VERSION ""

NS_ :

BS_:

BU_: PKP_PRND_Keypad HVAC Compressor_HPP DCDC_Inmotion_DC2 SME VCCU SME_4 SME_3 SME_2 SME_1 Diag_Tester BMS DCDC_inmotion_DC1 TCU Praker_GW OBC_Dilong DCDC_Dilong VCU
VAL_TABLE_ D_OBC_Faults 1 "Fault" 0 "Normal" ;
VAL_TABLE_ AAAAAAAAAAAAAAAAAAAAANew_Value_T 1 "Heating mode" 0 "Battery mode" ;
VAL_TABLE_ LED_Secondry_color 9 "Description for the value '0x9'" 8 "Amber/Orange" 7 "White/Light_Blue" 6 "Magenta" 5 "Cyan" 4 "Yellow" 3 "Blue" 2 "Green" 1 "Red" 0 "off" ;
VAL_TABLE_ Led_State 3 "Alternate_blink" 2 "Blink" 1 "On" 0 "Off" ;
VAL_TABLE_ LED_color 9 "Yellow/Green" 8 "Amber/Orange" 7 "White/light_Blue" 6 "magenta" 5 "Cyan" 4 "Yellow" 3 "Blue" 2 "Green" 1 "red" 0 "OFF" ;
VAL_TABLE_ Back_light_color 9 "Yellow/Green" 8 "Amber/Orange" 7 "White/light_blue" 6 "magenta" 5 "Cyan" 4 "Yellow" 3 "Blue" 2 "Green" 1 "Red" ;
VAL_TABLE_ Key_LED_number 4 "Description for the value '0x4'" 3 "Key_LED3" 2 "Key_LED2" 1 "Key_LED1" ;
VAL_TABLE_ Adress_claim_at_boot 1 "command_enabled" 0 "command_Disabled" ;
VAL_TABLE_ RX_command_list 128 "Set_CANopen_protocol" 125 "Set_backlight_color" 124 "LED_dim_at_startup" 123 "Set_backlight_level_at_startup" 122 "Start_DEMO_mode" 119 "Periodic_key_message_period" 117 "Heartbeat" 116 "Address_claim_at_boot" 115 "LED_acknowledgment" 114 "Event_state_transmission" 113 "Periodic_state_transmission" 112 "Set_source_address" 111 "Baud_rate_setting" 110 "Set_destination_address" 52 "Set_startup_LED_show" 42 "Get_software_revision" 40 "Set_startup_keys_message" 3 "Set_backlight_level" 2 "Set_LED_brightness_level" 1 "LED_Command" ;
VAL_TABLE_ Vt_Sig_LED_secondary_color 9 "Yellow/green" 8 "Amber/Orange" 7 "White/light_blue" 6 "Magenta" 5 "Cyan" 4 "Yellow" 3 "Blue" 2 "Green" 1 "Red" 0 "off" ;
VAL_TABLE_ TX_command_list 249 "Heart" 115 "LED_ack_message" 42 "software_revision" 1 "Key_contact_state" ;
VAL_TABLE_ VT_sig_LED_state 3 "Alternate_blink" 2 "Blink" 1 "on" 0 "off" ;
VAL_TABLE_ Vtsig_fault32_DC1 3 "Not Tested" 2 "Error Indicator" 1 "Active" 0 "Not Active" ;
VAL_TABLE_ Vtsig_fault31_DC1 3 "Not Tested" 2 "Error Indicator" 1 "Active" 0 "Not Active" ;
VAL_TABLE_ Vtsig_fault30_DC1 3 "Not Tested" 2 "Error Indicator" 1 "Active" 0 "Not Active" ;
VAL_TABLE_ Vtsig_fault29_DC1 3 "Not Tested" 2 "Error Indicator" 1 "Active" 0 "Not Active" ;
VAL_TABLE_ Vtsig_fault28_DC1 3 "Not Tested" 2 "Error Indicator" 1 "Active" 0 "Not Active" ;
VAL_TABLE_ Vtsig_fault27_DC1 3 "Not Tested" 2 "Error Indicator" 1 "Active" 0 "Not Active" ;
VAL_TABLE_ Vtsig_fault26_DC1 3 "Not Tested" 2 "Error Indicator" 1 "Active" 0 "Not Active" ;
VAL_TABLE_ Vtsig_fault25_DC1 3 "Not Tested" 2 "Error Indicator" 1 "Active" 0 "Not Active" ;
VAL_TABLE_ Vtsig_fault24_DC1 3 "Not Tested" 2 "Error Indicator" 1 "Active" 0 "Not Active" ;
VAL_TABLE_ Vtsig_fault23_DC1 3 "Not Tested" 2 "Error Indicator" 1 "Active" 0 "Not Active" ;
VAL_TABLE_ Vtsig_fault22_DC1 3 "Not Tested" 2 "Error Indicator" 1 "Active" 0 "Not Active" ;
VAL_TABLE_ Vtsig_fault21_DC1 3 "Not Tested" 2 "Error Indicator" 1 "Active" 0 "Not Active" ;
VAL_TABLE_ Vtsig_fault20_DC1 3 "Not Tested" 2 "Error Indicator" 1 "Active" 0 "Not Active" ;
VAL_TABLE_ Vtsig_fault19_DC1 3 "Not Tested" 2 "Error Indicator" 1 "Active" 0 "Not Active" ;
VAL_TABLE_ Vtsig_fault18_DC1 3 "Not Tested" 2 "Error Indicator" 1 "Active" 0 "Not Active" ;
VAL_TABLE_ Vtsig_fault17_DC1 3 "Not Tested" 2 "Error Indicator" 1 "Active" 0 "Not Active" ;
VAL_TABLE_ Vtsig_fault16_DC1 3 "Not Tested" 2 "Error Indicator" 1 "Active" 0 "Not Active" ;
VAL_TABLE_ Vtsig_fault15_DC1 3 "Not Tested" 2 "Error Indicator" 1 "Active" 0 "Not Active" ;
VAL_TABLE_ Vtsig_fault14_DC1 3 "Not Tested" 2 "Error Indicator" 1 "Active" 0 "Not Active" ;
VAL_TABLE_ Vtsig_fault13_DC1 3 "Not Tested" 2 "Error Indicator" 1 "Active" 0 "Not Active" ;
VAL_TABLE_ Vtsig_fault12_DC1 3 "Not Tested" 2 "Error Indicator" 1 "Active" 0 "Not Active" ;
VAL_TABLE_ Vtsig_fault11_DC1 3 "Not Tested" 2 "Error Indicator" 1 "Active" 0 "Not Active" ;
VAL_TABLE_ Vtsig_fault9_DC1 3 "Not Tested" 2 "Error Indicator" 1 "Active" 0 "Not Active" ;
VAL_TABLE_ Vtsig_fault8_DC1 3 "Not Tested" 2 "Error Indicator" 1 "Active" 0 "Not Active" ;
VAL_TABLE_ Vtsig_fault7_DC1 3 "Not Tested" 2 "Error Indicator" 1 "Active" 0 "Not Active" ;
VAL_TABLE_ Vtsig_fault6_DC1 3 "Not Tested" 2 "Error Indicator" 1 "Active" 0 "Not Active" ;
VAL_TABLE_ Vtsig_fault5_DC1 3 "Not Tested" 2 "Error Indicator" 1 "Active" 0 "Not Active" ;
VAL_TABLE_ Vtsig_fault4_DC1 3 "Not Tested" 2 "Error indicator" 1 "Active" 0 "Not Active" ;
VAL_TABLE_ Vtsig_fault3_DC1 3 "Not Tested'" 2 "Error indicator" 1 "Actve" 0 "Not Active" ;
VAL_TABLE_ Vtsig_fault2_DC1 3 "Not tested" 2 "Error indicator" 1 "Active" 0 "Not Active" ;
VAL_TABLE_ Fault11_DC1 3 "Not tested" 2 "Error indicator" 1 "Active" 0 "Not active" ;
VAL_TABLE_ Fault10_DC1 3 "Not tested" 2 "Error indicator" 1 "Active" 0 "not active" ;
VAL_TABLE_ A_HVAC_AC_group_2 128 "Zone 2 FRSH AIR " 64 "Zone 2 Heat ON" 32 "Zone 2 Fan HI" 16 "Zone 2 Fan ON" 8 "Floor Heat ON " 4 "Boost Pump ON " 2 "Fault Lamp ON " 1 "Heat Valve ON " ;
VAL_TABLE_ rx_ac_load_shading 3 "ignore" 2 "Medium Blowers speed" 1 "Run unloaded with medium " 0 "Run normal. " ;
VAL_TABLE_ rx_floor_heat_status 15 "ignored" 10 "Rear Unit High Blower Speed" 9 "Rear Unit Low Blower Speed" 8 "Rear Unit Natural Convection" 7 "Rear Unit Heat Valve Open" 6 "Rear Unit Heat Valve Closed" 5 "Front Unit High Blower Speed" 4 "Front Unit Low Blower Speed" 3 "Front Unit Natural Convection" 2 "Front Unit Heat Valve Open" 1 "Front Unit Heat Valve Closed" 0 "Inactive" ;
VAL_TABLE_ rx_freshair 3 "ignored" 2 "FreshAir" 1 "Recirculation" 0 "Controlled" ;
VAL_TABLE_ rx_hvac_opr_mode 15 "no action" 14 "EvapratoCondenserFansHigh Speed" 13 "Condenser Fans - High Speed" 12 "Evaporator Blowers - High Speed" 6 "All Heat Valves Open. AC OFF " 5 "Cooling/Reheat/Vent/low amb" 4 "Auto/Reheat" 3 "Reheat" 2 "Cooling/Vent    " 1 "Heating / Vent" 0 "Only Vent " ;
VAL_TABLE_ rx_controller_reset 3 "ignored" 2 "Not defined    " 1 "Forces blower speed to low speed" 0 "Runs in standard mode    " ;
VAL_TABLE_ rx_HighBlowerSpeedHeat 3 "Description for the value '0x3'" 1 "Force blower speed to high" 0 "Runs in standard mode" ;
VAL_TABLE_ rx_hvac_on_off 3 "Inactive" 1 "runs to default/ requested mode" 0 "Inactive" ;
VAL_TABLE_ rx_boostpump_signal 2 "no action" 1 "Boost Pump is oN" 0 "Boost Pump is off" ;
VAL_TABLE_ RX_blowerspeed 3 "igniore" 1 "Forceblowerspeedtolow" 0 "Runs in standard mode  " ;
VAL_TABLE_ Recirculation 3 "not used" 2 "door controlled per ladder diag" 1 "door open all the time" 0 "door closed all the time" ;
VAL_TABLE_ HigBloweHeatmode 1 "Heat mode-speed overidden" 0 "Normal" ;
VAL_TABLE_ HVACOperatingModes 15 "Description for the value '0xF'" 14 "EvporatorCondenserFansHighSpeed" 13 "Condenser Fans - High Speed" 12 "Evaporator Blowers - High Speed" 6 "All Heat Valves Open. AC OFF." 5 "Cooling/Reheat/Vent" 4 "Auto/Reheat ambient cut-out" 2 "Cooling/Vent" 1 "Heating/Vent" 0 "Only Vent (fresh air)" ;
VAL_TABLE_ BMSRequest 2 "Compressor off." 1 "Compressor at 50%,Heaters on off" 0 "Run normal." ;
VAL_TABLE_ BatteryCoolerStatus 2 "Ignore" 1 "ON" 0 "OFF" ;
VAL_TABLE_ IdleUpStatus 3 "Skip" 1 "ON" 0 "OFF" ;
VAL_TABLE_ BoostPumpStatus 2 "bus controls the boost pump" 1 "notify boost pump is oN" 0 "notify boost pump is off" ;
VAL_TABLE_ LowBlowerSpeedSignal 3 "Skip" 1 "Low" 0 "Standard" ;
VAL_TABLE_ A_HVAC_AC_group_1 128 "Fresh Air ON" 64 "Unloader 2 Energized " 32 "Unloader 1 Energized" 16 "Compressor ON" 8 "Cond. Fan Low Speed Bit" 4 "Cond. Fan High Speed" 2 "Evap. Fan Low Speed" 1 "Evap. Fan High Speed" ;
VAL_TABLE_ AAAaAAA_Electric 3 "Not Available" 2 "Critical Overheat" 1 "OverHeat" 0 "Ok" ;
VAL_TABLE_ AA_D_ElCompFaultOverloadOutput 3 "Not Available" 2 "Reserved" 1 "Error Active" 0 "OK" ;
VAL_TABLE_ AA_D_ElCompFaultTractionVoltage 3 "Not Available" 2 "OverVoltage" 1 "Undervoltage" 0 "Ok" ;
VAL_TABLE_ D_ElCompFaultTempElectrical 3 "Description for the value '0x3'" 2 "Critical Overheat" 1 "Overheat" 0 "OK" ;
VAL_TABLE_ AA_D_ElCompFaultOilLevel 3 "Not available" 2 "Reserved" 1 "LOW" 0 "OK" ;
VAL_TABLE_ AA_D_ElCompHvilStatus 7 "Not available" 6 "Reserved" 5 "Reserved" 4 "Reserved" 3 "Reserved" 2 "HVIL_diff >1V" 1 "HVIL < 5V" 0 "HVIl >= 5V" ;
VAL_TABLE_ AA_D_ElCompStatus 7 "Not available" 3 "Error Permanent" 2 "Error Recoverable" 1 "Running" 0 "Standby" ;
VAL_TABLE_ AA_D_ElCompEnableInput_NotUsed 3 "Not  Available" 2 "Error" 1 "RUN" 0 "Do not RUN" ;
VAL_TABLE_ A_MCU_Error 10 "MCU stator over temp" 9 "MCU inverter fault" 8 "MCU stator over temp" 7 "MCU CAN Active" 6 "MCU inverter over temp" 5 " MCU over speed warning" 4 "MCU over speed alarm" 3 "MCU undervoltage alarm" 2 "MCU overvoltage alarm" 1 "MCU limp home mode " 0 "No error" ;
VAL_TABLE_ A_TCu_error 3 "TCU_wtachdogerror2" 2 "TCU_wtachdogerror1" 1 "Trans Temp error" 0 "No error" ;
VAL_TABLE_ A_VMM_MiscellenousStatus 3 "Not available" 2 "Error" 1 "Active" 0 "Not active" ;
VAL_TABLE_ AA1_EBS 3 "SNA" 2 "Error" 1 "Brake pedal being pressed" 0 "BrakePedaisnot being Presssed" ;
VAL_TABLE_ A_halt_brake 3 "Not available" 2 "Error " 1 "Halt brake Active" 0 "Halt brake Passive" ;
VAL_TABLE_ A_ABS_amber_warn 3 "No action" 2 "Reserved" 1 "ON" 0 "OFF" ;
VAL_TABLE_ ABS_operation 3 "Not available" 2 "Reserved" 1 "Fully operational" 0 "Not Fully operational" ;
VAL_TABLE_ A_ABS_Off_Road 3 "Not available" 2 "Error" 1 "ABS off road active" 0 "ABS off road Passive" ;
VAL_TABLE_ A_ABC_Active 3 "Not Available" 2 "Reserved" 1 "ABS_Active" 0 "ABS passive but not active" ;
VAL_TABLE_ A_Brake_Switch 3 "Not available or not installed" 2 "Error" 1 "Brake Pedal Depressed" 0 "Brake Pedal Released" ;
VAL_TABLE_ A_park_brake 2 "Error" 1 "Brake Set" 0 "Brake not Set" ;
VAL_TABLE_ A_Seat_Belt 3 "Not available" 2 "Error" 1 "Buckled" 0 "Not Buckeld" ;
VAL_TABLE_ AA7 1 "Version 1,2 or  3" 0 "Version 4" ;
VAL_TABLE_ AA5 127 "SNA" ;
VAL_TABLE_ AA4 3 "SNA" 2 "Class C DTC" 1 "Fast Flash" 0 "Slow Flash" ;
VAL_TABLE_ AA3 3 "SNA" 2 "Reserved" 1 "Fast Flash" 0 "Slow Flash" ;
VAL_TABLE_ AA2 3 "SNA" 2 "Short MIL for WWH OBD" 1 "ON" 0 "OFF" ;
VAL_TABLE_ AA1 3 "SNA" 2 "Reserved" 1 "ON" 0 "OFF" ;
VAL_TABLE_ A_pgn 3 "Not tested" 2 "Error indicator" 1 "Active" 0 "Not active" ;
VAL_TABLE_ vtSig_ST_KL 15 "Signal Invalid" 10 "KL15- On" 9 "KL15- Change" 6 "KL30 B- On" 5 "KL30 B- Change" ;
VAL_TABLE_ VrSig_CTR_CLSY_CR 3 "signal invalid" 2 "open central locking" 1 "dont open central locking" ;
VAL_TABLE_ vtsig_bits16_siganlinvalid 65535 "Signal Invalid" ;
VAL_TABLE_ Vtsig_Bits2_DefaultValue0x3 3 "Default Value" ;
VAL_TABLE_ vtsig_bits12 4095 "Signal Invalid" ;
VAL_TABLE_ vtsig_bit4 15 "Signal Invalid" ;
VAL_TABLE_ vtsig_bits8 255 "Signal Invalid" ;
VAL_TABLE_ Wakeup_Rsn_Copy_3 255 "Snaa" 5 "Clamp15" 4 "Switch" 3 "RTC" 2 "Plug Present" 1 "Control_pilot" 0 "Network" ;
VAL_TABLE_ Vehicle_renegotiate_Copy_3 3 "SNA" 2 "Error" 1 "Requested" 0 "Not_requested" ;
VAL_TABLE_ Vehicle_contactor_status_Copy_3 3 "SNA" 2 "Stuck" 1 "Close" 0 "Open" ;
VAL_TABLE_ vehicle_chg_status_Copy_3 3 "Description for the value '0x3'" 2 "reserved" 1 "start_charging" 0 "stop_charging" ;
VAL_TABLE_ Vehicle_charge_selection_Copy_3 3 "SNA" 2 "error" 1 "secondary node" 0 "Primary node" ;
VAL_TABLE_ Vehicle_charge_permission_Copy_3 3 "Stop" 2 "Emergency stop" 1 "allowed" 0 "Not allowed" ;
VAL_TABLE_ VCVCCU_V2G_EVErrorCode_Copy_3 11 "No data" 10 "CHARGING_SYSTEM_INCOMPATIBILITY" 9 "RESERVED_C" 8 "RESERVED_B" 7 "RESERVED_A" 6 "CHARGING_VOLTAGE_OUT_OF_RANGE" 5 "FAILCHARGCURRENTDIFFERENTIAL" 4 "FAILED_EVRESSMALFUNCTION" 3 "FAILChargeCONNECT_LOCK_FAULT" 2 "FAILED_EVSHIFT_POSITION" 1 "FAILED_RESSTEMPERATURE_INHIBIT" 0 "NO_ERROR" ;
VAL_TABLE_ VCVCCU_V2G_Core_StackError_Copy_ 16 "StackError_PBufToSmall" 15 "StackError_InvalidKeyPair" 14 "StackError_NvM" 13 "StackError_NegativeResponseCode" 12 "StackError_InvalidRxParameter" 11 "StackError_InvalidRxMessage" 10 "StackError_Crypto" 9 "StackError_XmlSecurity" 8 "StackError_Exi" 7 "StackError_IpBase" 6 "StackError_Timeout" 5 "Timeout_RequestNotAcknowledged" 4 "Timeout_RequestAcknowledged" 3 "StackError_InvalidTxParameter" 2 "StackError_TransportLayer" 1 "StackError_SLAC" 0 "StackError_NoError" ;
VAL_TABLE_ VCVCCU_V2G_Core_SDPSecurityTx_Co 16 "SDPSecurity_None" 0 "SDPSecurity_Tls" ;
VAL_TABLE_ VCVCCU_V2G_Core_SAPSchemaID_Copy 4 "SAPSchemaIDs_None" 3 "NumOfSupportedSchemas" 2 "SAPSchemaIDs_DIN" 1 "SAPSchemaIDs_ISO_Ed2_CD" 0 "SAPSchemaIDs_ISO" ;
VAL_TABLE_ VCCU_mobile_status_Copy_3 3 "SNA" 2 "Vehicle immobile Fault" 1 "Vehicle Imobile" 0 "Vehicle mobile" ;
VAL_TABLE_ VCCU_Diag_Active_Copy_3 1 "Diag_no_active" 0 "Diag_active" ;
VAL_TABLE_ VCCU_Charge_unit_request_Copy_3 3 "SNA" 2 "Enable ventilation" 1 "Enable" 0 "Disable" ;
VAL_TABLE_ VCCU_8bit_Eroor_Copy_3 255 "SNA" 254 "Error" ;
VAL_TABLE_ VCCU_16bit_error_Copy_3 65535 "SNA" 65534 "Error" ;
VAL_TABLE_ V2G_SAP_response_code_Copy_3 2 "FAILED_NO_NEGOTIATION" 1 "OKNEGOTIAMINOR_DEVIATION" 0 "OK_SUCCESSFUL_NEGOTIATION" ;
VAL_TABLE_ V2G_core_msg_status_Copy_3 50 "StopCommunicationSession_Failed" 49 "StopCommunicationSession_OK" 48 "MsgStatus_SessionStop_Failed" 47 "MsgStatus_SessionStop_OK" 46 "WeldingDetection_Failed" 45 "MsgStatus_WeldingDetection_OK" 44 "MsgStatus_CurrentDemand_Failed" 43 "MsgStatus_CurrentDemand_OK" 42 "MsgStatus_PreCharge_Failed" 41 "MsgStatus_PreCharge_OK" 40 "MsgStatus_CableCheck_Failed" 39 "MsgStatus_CableCheck_OK" 38 "MsgStatus_ChargingStatus_Failed" 37 "MsgStatus_ChargingStatus_OK" 36 "MsgStatus_MeteringReceipt_Failed" 35 "MsgStatus_MeteringReceipt_OK" 34 "MsgStatus_PowerDelivery_Failed" 33 "MsgStatus_PowerDelivery_OK" 32 "ChargeParameterDiscovery_Failed" 31 "ChargeParameterDiscovery_OK" 30 "MsgStatus_Authorization_Failed" 29 "MsgStatus_Authorization_OK" 28 "MsgStatus_PaymentDetails_Failed" 27 "PaymentDetails_OK" 26 "CertificateUpdate_Failed" 25 "CertificateUpdate_OK" 24 "CertificateInstallation_Failed" 23 "CertificateInstallation_OK" 22 "MsgStatus_ReadProvCert_Failed" 21 "MsgStatus_ReadProvCert_OK" 20 "WrapperReadRootCerts_Failed" 19 "MsgStatus_ReadRootCerts_OK" 18 "PaymentServiceSelection_Failed" 17 "PaymentServiceSelection_OK" 16 "MsgStatus_ServiceDetail_Failed" 15 "MsgStatus_ServiceDetail_OK" 14 "ReadContrCertChain_Failed" 13 "ReadContrCertChain_OK" 12 "ServiceDiscovery_Failed" 11 "MsgStatus_ServiceDiscovery_OK" 10 "MsgStatus_SessionSetup_Failed" 9 "MsgStatus_SessionSetup_OK" 8 "SupportedAppProtocol_Failed" 7 "SupportedAppProtocol_OK" 6 "MsgStatus_TransportLayer_Failed" 5 "MsgStatus_TransportLayer_OK" 4 "SECCDiscoveryProtocol_Failed" 3 "SECCDiscoveryProtocol_OK" 2 "MsgStatus_SLAC_Failed" 1 "MsgStatus_SLAC_OK" 0 "MsgStatus_None" ;
VAL_TABLE_ V2G_core_msg_state_Copy_3 5 "msgstate_timeout" 4 "msgstate_response_received" 3 "msgstate_transmission_confirmed" 2 "msgstate_request_sent" 1 "msgstate_streaming_request" 0 "Msg_state_waitfor next_request" ;
VAL_TABLE_ UpShift_In_Progress_Copy_3 1 "High gear Shift is in progress" 0 "High Shift is not in progress" ;
VAL_TABLE_ Upshift_Failed_Copy_3 1 "shift to High gear failed" 0 "shift to High gear successful" ;
VAL_TABLE_ Tolerance_unit_Copy_3 9 "WH" 8 "W_S" 7 "W" 6 "VA" 5 "V" 4 "HA" 3 "A" 2 "S" 1 "M" 0 "H" ;
VAL_TABLE_ timer_status_Copy_3 3 "SNA" 2 "Elapsed" 1 "Running" 0 "Stopped" ;
VAL_TABLE_ TCU_System_type_Copy_3 0 "Unknown" ;
VAL_TABLE_ Sw_Status_Copy_3 3 "sna" 2 "Error" 1 "Pressed" 0 "Not Pressed" ;
VAL_TABLE_ StateM_machine_error_Copy_3 20 "SMER_InvalidControlPilotState" 19 "PaymtServiceSelect_ServMismatch" 18 "InitialAlignmentCheckOngoinTimer" 17 "SMER_Timer_PairingOngoingTimer" 16 "Timer_FinePositionOngoingTimer" 15 "SMER_StackError" 14 "NoContractInstallatiServiceAvbl" 13 "NoContractCertificateServiceAvlb" 12 "NoSharedPaymentOption" 11 "InvalidEnergyTransferMode" 10 "Discovery_NoSharedSecurityOption" 9 "InitializatContrctSelectiFailed" 8 "SMER_Timer_PreChargeOngoingTimer" 7 "Timer_CableCheckOngoingTimer" 6 "ChargeParmtrDiscveryOngoingTimer" 5 "Timer_AuthorizationOngoingTimer" 4 "SMETimer_ReadyToChargeTimer" 3 "Timer_CommunicationSetupTimer" 2 "SMER_Timer_SequencePerformTimer" 1 "SMER_Timer_IPAddressWaitTimer" 0 "SMER_NoError" ;
VAL_TABLE_ state_msg_state_Copy_3 3 "SMMS_WaitingForApplication" 2 "SMMS_ProcessingResponse" 1 "SMMS_WaitingForResponse" 0 "SMMS_PreparingRequest" ;
VAL_TABLE_ state_mchine_status_Copy_3 32 "PowerDemand" 31 "InitialAlignmentCheck" 30 "Pairing" 29 "FinePositioning" 28 "FinePositioningSetup" 27 "Error_Stopped" 26 "Error_WaitForRetry" 25 "Finished" 24 "StopCommunicationSession" 23 "SessionStop" 22 "WeldingDetection" 21 "MeteringReceipt" 20 "CurrentDemand" 19 "ChargingStatus" 18 "PowerDelivery" 17 "PreCharge" 16 "CableCheck" 15 "ChargeParameterDiscovery" 14 "Authorization" 13 "PaymentDetails" 12 "CertificateUpdate" 11 "CertificateInstallation" 10 "PaymentServiceSelection" 9 "ServiceDetails" 8 "ServiceDiscovery" 7 "SessionSetup" 6 "SupportedAppProtocol" 5 "TLConnection" 4 "SECCDiscoveryProtocol" 3 "WaitForIP" 2 "SLAC" 1 "Initialized" 0 "None" ;
VAL_TABLE_ ST_SER_DSCO_PLG_Copy_3 3 "Description for the value '0x2'" 2 "Service Disconnector Connected" 1 "Service Disconnector Open" ;
VAL_TABLE_ ST_MEASMT_ISL_Copy_3 3 "Signal Invalid" 2 "Iso measurement  running" 1 "Iso measurement not running" ;
VAL_TABLE_ ST_ERR_ISL_EXTN_BN_HV_VT_Copy_3 3 "Signal Invalid" 2 "Active" 1 "Not Active" 0 "No statement possible" ;
VAL_TABLE_ ST_AC_CHGNG_EPRG_Copy_3 2 "Signal Invalid" 1 "Activated" 0 "Deactivated" ;
VAL_TABLE_ SNA_Copy_3 255 "SNA" ;
VAL_TABLE_ Slow_Upshift_Copy_3 1 "Shift require more amnt of time" 0 "Shift in a normal amount of time" ;
VAL_TABLE_ Shift_Disabled_Copy_3 1 "Gear shift disabled" 0 "Gear shift not disabled" ;
VAL_TABLE_ Self_Diag_Status_Copy_3 7 "SNA" 6 "Error" 5 "Short Btw pins" 4 "Supply Voltage Failure'" 3 "Open Load" 2 "Short to Batt" 1 "Short to GND" 0 "Ok" ;
VAL_TABLE_ Selected_Gear_Copy_3 3 "Shift in Progress" 2 "High" 1 "Low" 0 "Neutral" ;
VAL_TABLE_ RTC_req_Copy_3 3 "SNA" 2 "reserved" 1 "requested" 0 "Not requested" ;
VAL_TABLE_ RQ_CHGRDI_Copy_3 2 "Char with depa time and cond" 1 "Plug & Charge (default)" 0 "no charging" ;
VAL_TABLE_ Retract_status_Copy_3 3 "Not avalible" 2 "Error" 1 "Ramp Extracted" 0 "Ramp retracted" ;
VAL_TABLE_ Resistance_Copy_3 7 "SNA" 6 "Error" 5 "S3_480_ohm" 4 "S3_150_ohm" 3 "1500 Ohm" 2 "680 ohm" 1 "220 Ohm" 0 "100 Ohm" ;
VAL_TABLE_ Ramp_move_Copy_3 3 "Not availble" 2 "error" 1 "Ramp being move" 0 "ramp being not move" ;
VAL_TABLE_ Ramp_enable_Copy_3 3 "not available" 2 "error" 1 "enable" 0 "disable" ;
VAL_TABLE_ PWM_charge_mode_req_Copy_3 3 "Description for the value '0x3'" 2 "Error" 1 "PWM_charge_mode_request_D" 0 "PWM_charge_mode_request_C" ;
VAL_TABLE_ PTC_diag_Copy_3 7 "SNA" 6 "Error" 5 "Reserved 1" 4 "Out of range" 3 "Open Load" 2 "Short to Batt" 1 "Short to GND" 0 "Ok" ;
VAL_TABLE_ PTC2_Copy_3 7 "SNA" 6 "reserved3" 5 "reserved2" 4 "reserved1" 3 "Open Load" 2 "Short to Batt" 1 "Short to GND" 0 "Ok" ;
VAL_TABLE_ Precond_desire_Copy_3 255 "SNA" 1 "Yes" 0 "No" ;
VAL_TABLE_ Pre_HVAC_Copy_3 3 "SNA" 2 "no_warm water , cool & venti" 1 "hot water and heating" 0 "only warm water , ventilation" ;
VAL_TABLE_ Pos_Feedback_Copy_3 7 "SNA" 6 "Reseved3" 5 "Reserved2" 4 "Reserved1" 3 "Open Load" 2 "Short to Batt" 1 "Short to GND" 0 "Ok" ;
VAL_TABLE_ Plug_present_self_diag_Copy_3 7 "SNA" 6 "Reseved3" 5 "Reserved2" 4 "Reserved1" 3 "Open Load" 2 "Short to Batt" 1 "Short to GND" 0 "Ok" ;
VAL_TABLE_ plug_lock_permission_Copy_3 3 "Description for the value '0x3'" 2 "Reserved" 1 "Allowed" 0 "Not_allowed" ;
VAL_TABLE_ PKP_number_Copy_3 3 "Key 4" 2 "Key 3" 1 "Key 2" 0 "Key 1" ;
VAL_TABLE_ Openstatusofdoor1_Copy_3 3 "Not availble" 2 "Error" 1 "Open" 0 "Closed" ;
VAL_TABLE_ Nm01_Copy_3 1 "Charg_Comm_active" 0 "Charg_Comm_not _active" ;
VAL_TABLE_ New_Value_Table_151_Copy_3 11 "reserved c" 10 "reserved B" 9 "Reserved A" 8 "Reserved 9" 7 "Reserved 8" 6 "EVSE Malfunction" 5 "EVSE Emergency Shutdwon" 4 "EVSE Isolation Monitoring Active" 3 "EVSE Utility Interrupt Event" 2 "EVSE Shutdown" 1 "EVSE Ready" 0 "EVSE_Not_Ready" ;
VAL_TABLE_ Motor_Req_Copy_3 7 "SNA" 6 "Reserved3" 5 "Reserved2" 4 "Reserved1" 3 "Measurement" 2 "Direction B" 1 "Directon A" 0 "Stop" ;
VAL_TABLE_ Motor_L_U_Copy_3 3 "SNA" 2 "Reserved" 1 "Unlock" 0 "Lock" ;
VAL_TABLE_ Modes_Copy_3 1 "Battery mode" 0 "Heating mode" ;
VAL_TABLE_ MCU_System_Type_Copy_3 15 "Undefined" 14 "Undefined" 13 "Undefined" 12 "Undefined" 11 "Undefined" 10 "Undefined" 9 "Undefined" 8 "Undefined" 7 "EM-PMI318B-T360-465V" 6 "Undefined" 5 "EM-PMI318B-T520E-465V" 4 "EM-PMI318B-T440E-255V" 3 "EM-PMI318-T400-255V" 2 "EM-PMI318-T360-425V" 1 "EM-PMI318-T350-255V" 0 "UnKnown" ;
VAL_TABLE_ lockstatusofdoor1_Copy_3 3 "Not Available" 2 "Error" 1 "lock" 0 "Unlock" ;
VAL_TABLE_ Lock_motor_Copy_3 7 "SNA" 6 "Error" 5 "Reserved2" 4 "Resserved1" 3 "Measurement" 2 "Direction B" 1 "Direction A" 0 "Idle" ;
VAL_TABLE_ LIN_Freq_Copy_3 255 "Not Available" 1 "60 Hz" 0 "50 Hz" ;
VAL_TABLE_ LIN_EV_Frequencies_Copy_3 255 "Not available" 2 "both 50 Hz_60 Hz" 1 "only 60 Hz" 0 "only 50 Hz" ;
VAL_TABLE_ Limit_mode_Copy_3 15 "Error indicator" 14 "Not Available" 11 "External output voltage limit" 10 "Internal output voltage limit" 9 "External current limitation" 8 "High side current limitation" 7 "High side power limitation" 6 "coolant temp limitation" 5 "Power stage temp limitation" 4 "High input voltage limitation" 3 "low input voltage limitation" 2 "Event limitation" 1 "Maximum current limitatio" 0 "No Limitation" ;
VAL_TABLE_ LED_State_Copy_3 3 "Description for the value '0x3'" 2 "Off" 1 "On" 0 "Off" ;
VAL_TABLE_ LED_colour_Secondary_colour_Copy 9 "Yellow / Green  " 8 "Amber / Orange" 7 "White / Light blue " 6 "Magneta" 5 "Cyan" 4 "Yellow" 3 "Blue" 2 "Green" 1 "Red" 0 "Off" ;
VAL_TABLE_ isolation_mesmt_req_Copy_3 3 "Description for the value '0x3'" 2 "reserved" 1 "requested" 0 "Not_requested" ;
VAL_TABLE_ isolate_mesmt_status_Copy_3 3 "SNA" 2 "Error" 1 "Active" 0 "Not active" ;
VAL_TABLE_ inlet_motor_status_Copy_3 7 "SNA" 6 "Error" 5 "Reserved3" 4 "Reserved2" 3 "Reserved1" 2 "Moving" 1 "Locked" 0 "Unlocked" ;
VAL_TABLE_ Hw_varient_Copy_3 3 "SNA" 2 "reserved" 1 "Combo1 inlet" 0 "Combo2 " ;
VAL_TABLE_ HS_req_Copy_3 3 "SNA" 2 "Reserved" 1 "Enable" 0 "Disable" ;
VAL_TABLE_ high_side_diag_Copy_3 7 "SNA" 6 "Error" 5 "Short Btw pins" 4 "Inverse Currrent" 3 "Open Load" 2 "Short to Batt" 1 "Short to GND" 0 "Ok" ;
VAL_TABLE_ Forced_Gear_Engagement_Torque_Co 1 "TCU imposing min torque reqt" 0 "TCU not imposing min torque reqt" ;
VAL_TABLE_ EVSE_resp_code_Copy_3 26 "FAILED_CERTIFICATE_REVOKED" 25 "FAILED_CERTIFICATE_NOT_ALLOW_e" 24 "FAILED_CONTACTOR_ERROR" 22 "FAILED_WRNG_ENRGY_TRNSFER_TYPE" 21 "FAILED_NO_CHARGE_SERVICE_SELECt" 20 "FAILED_MTRING_SIGNTURE_NOT_VALID" 19 "FAILED_CHARGING_PROFILE_INVALID" 18 "FAILED_TARIFF_SELECTION_INVALID" 17 "FAILED_POWER_DELIVERY_NOT_APPLy" 16 "FAILED_WRONG_CHARGE_PARAMETER" 15 "FAILED_CONTRACT_CANCELED" 14 "FAILED_CHALLENGE_INVALID" 13 "FAILED_CERT_CHAIN_ERROR" 12 "FAILED_NO_CERTIFICATE_AVAILABLE" 11 "FAILED_SIGNATURE_ERROR" 10 "FAILED_CERTIFICATE_EXPIRED" 9 "FAILED_PAYMENT_SELECTION_INVALID" 8 "FAILED_SERVICE_SELECTION_INVALID" 7 "FAILED_UNKNOWN_SESSION" 6 "FAILED_SERVICE_IDINVALID" 5 "FAILED_SEQUENCE_ERROR" 4 "FAILED" 3 "OK_CERTIFICATE_EXPIRES_SOON" 2 "OK_OLD_SESSION_JOINED" 1 "OK_NEW_SESSION_ESTABLISHED" 0 "OK" ;
VAL_TABLE_ EVSE_Process_Copy_3 1 "ongoing" 0 "Finished" ;
VAL_TABLE_ EVSE_notification_Copy_3 2 "Re_Negotation" 1 "Stop Charging" 0 "None" ;
VAL_TABLE_ EVSE_isoltae_status_Copy_3 4 "No_Imd" 3 "Fault" 2 "Warning" 1 "Valid" 0 "Invalid" ;
VAL_TABLE_ energy_trans_mode_Copy_3 32 "Description for the value '0x18'" 16 "Energy_transfermode_combo_core" 8 "Energy_transfermode_DC_extend" 4 "Energy_transfermode_DCcore" 2 "Energy_transfermode_AC_3P" 1 "Energy_transfermode_AC_1P" 0 "Energy_transfermode_none" ;
VAL_TABLE_ energy_mode_Copy_3 15 "undefined" 5 "DC_unique" 4 "DC_combo_core" 3 "DC_extended" 2 "DC_core" 1 "AC_three_phase_core" 0 "Ac_single_phse_core" ;
VAL_TABLE_ E2E_state_charge_vehicle_Copy_3 32 "NoDATA_OK" 5 "Valid_NND" 3 "Valid_Error" 2 "Valid_SEQ" 1 "Valid_REP" 0 "Valid_Ok" ;
VAL_TABLE_ e2e_state_Copy_3 255 "Hard_run_time_error" 119 "Soft_run_time_error" 69 "Invalid_NND" 67 "Invalid_Error" 66 "Invalid_SEQ" 65 "Invalid_REP" 64 "Invalid_Ok" 53 "Init_NND" 51 "Init_error" 50 "Init_SEQ" 49 "Init_REP" 48 "Init_Ok" 37 "No_Data_NND" 35 "No_data_error" 34 "No_data_SEQ" 33 "No_data_REP" 32 "No_data_ok" 5 "valid NND" 3 "valid Error" 2 "valid SEQ" 1 "valid REP" 0 "valid ok" ;
VAL_TABLE_ Down_Shift_In_progress_Copy_3 1 "High gear Shift is in progress" 0 "High Shift is not in progress" ;
VAL_TABLE_ Down_Shift_failed_Copy_3 1 "shift to low gear failed" 0 "shift to Low gear Successful" ;
VAL_TABLE_ Door_Enable_Copy_3 2 "Not available" 1 "Error" 0 "Enabled" ;
VAL_TABLE_ DM13_suspend_signal_Copy_3 15 "not available" 14 "ResumingNormalpattern" 3 "Temporarysuspensionofsomemsg" 2 "Temporarysuspensionofallmsg" 1 "Indefinitesuspensionofsomemsg" 0 "Indefinitesuspensionofallmsg" ;
VAL_TABLE_ DM13_hold_signal_Copy_3 15 "Not available" 1 "Devices whose broadcast state" 0 "All Devices" ;
VAL_TABLE_ DilongDCDC_Faults_Copy_3 256 "Communication fault" 128 "Internal fault" 64 "Output short circuit protection" 32 "Input under voltage" 16 "Input over voltage" 8 "Output under voltage" 4 "Output over voltage" 2 "Output over current" 1 "Over temperature shutdown" ;
VAL_TABLE_ dept_Copy_3 0 "SNA" ;
VAL_TABLE_ DCDC_control_Copy_3 15 "Error Indicator" 14 "Not availble" 13 "Error state" 12 "Shutting down" 2 "Current control" 1 "Voltage control" 0 "Standby" ;
VAL_TABLE_ D_OBC_Mode_Copy_3 1 "Heating" 0 "Battery" ;
VAL_TABLE_ D_OBC_Charging_status_flag_Copy_ 16 "0 com normal 1 com timeout" 8 "0 start state 1 off" 4 "0 normal 1 input volt error" 2 "0 normal 1 charg temp too high" 1 "0 normal 1 HW failure" ;
VAL_TABLE_ D_OBC_Charging_state_Copy_3 2 "Charging complete" 1 "Bat prote,charger turn off op" 0 "The charger starts charging " ;
VAL_TABLE_ D_OBC_Charging_boot_status_Copy_ 32 "0 normal 1 alarm" 16 "0 normal 1 alarm" 8 "0 normal 1 alarm" 4 "2 fault 3 no electic lock" 2 "0 unlock 1 lock" 1 "0 disconnect 1 HW close" ;
VAL_TABLE_ D_DCDC_Switch_Control_Copy_3 1 "Shutdown" 0 "Power on" ;
VAL_TABLE_ D_DCDC_status_Copy_3 1 "Stop" 0 "Work" ;
VAL_TABLE_ D_DCDC_Fault_list_Copy_3 32768 "Reserve" 16384 "Reserve" 8192 "Reserve" 4096 "Reserve" 2048 "Reserve" 1024 "Reserve" 512 "Reserve" 256 "Communication fault alarm" 128 "Internal fault alarm " 64 "Output shortcircuit protection " 32 "Input under voltage alarm " 16 "Input over-voltage alarm" 8 "Output undervoltage alarm" 4 "Output over-voltage alarm" 2 "Output over-current alarm" 1 "Over temperature shutdown" ;
VAL_TABLE_ Current_Transmission_Mode_Copy_3 3 "Forward Low" 2 "Forward Automatic" 1 "Reverse" 0 "Neutral" ;
VAL_TABLE_ CTR_FKTN_PRTNT_DRV_Copy_3 -2147483648 "Signal invalid" ;
VAL_TABLE_ CTR_BS_PRTNT_DRV_Copy_3 65535 "Signal Invalid" ;
VAL_TABLE_ Cp_wakeup_Copy_3 3 "sna" 2 "error" 1 "wakeup detected" 0 "wakeup not detected" ;
VAL_TABLE_ CP_chrage_mode_req_Copy_3 7 "SNA" 6 "Error" 5 "Reserved 3" 4 "Reserved 2" 3 "Reserved 1" 2 "Mode D" 1 "Mode C" 0 "Mode B" ;
VAL_TABLE_ Controlmode_Copy_3 3 "take no action" 2 "reserved" 1 "Current control" 0 "Voltage control " ;
VAL_TABLE_ Contactor_req_Copy_3 3 "Description for the value '0x3'" 2 "force_open" 1 "close" 0 "open" ;
VAL_TABLE_ connection_status_Copy_3 3 "Description for the value '0x3'" 2 "error" 1 "connected" 0 "not connected" ;
VAL_TABLE_ CommandEnableDCC2_Copy_3 3 "Take no action" 2 "Reserved" 1 "Enable" 0 "Standby" ;
VAL_TABLE_ Clamp_15_active_Copy_3 1 "Clamp_15_noactive" 0 "Clamp15_Active" ;
VAL_TABLE_ chg_unit_state_Copy_3 7 "SNA" 6 "EVSE State F" 5 "EVSE State E" 4 "EVSE State D" 3 "EVSE State C" 2 "EVSE State B2" 1 "EVSE state B1" 0 "EVSE state A" ;
VAL_TABLE_ chg_unit_mode_Copy_3 7 "sna" 6 "error" 5 "reserved" 4 "Charge Pantograph" 3 "Charging LIN" 2 "Charging Not allowed" 1 "Charge PWM" 0 "Charge V2G" ;
VAL_TABLE_ chg_selct_ack_Copy_3 3 "sna" 2 "error" 1 "secondary node" 0 "primary_node" ;
VAL_TABLE_ Charge_State_Copy_3 2 "Charging complete" 1 "Bat prtect charger turn off" 0 "Charger start charging" ;
VAL_TABLE_ Charge_Comm_Active_Copy_3 1 "Description for the value '0x1'" 0 "Charg_Comm_Active" ;
VAL_TABLE_ Charg_Lin_Active_Copy_3 1 "Charg_Lin_Non active" 0 "Charg_Lin_Active" ;
VAL_TABLE_ Broadcast_Copy_3 3 "dont care" 2 "reserved" 1 "start broadcast" 0 "Stop broadcast" ;
VAL_TABLE_ Brakes_Copy_3 3 "Not available" 2 "Error indicator" 1 "Fuel level sufficient" 0 "Fuel level not sufficient" ;
VAL_TABLE_ Boolean_Copy_3 1 "True" 0 "False" ;
VAL_TABLE_ appl_func_mode_req_Copy_3 2 "Reset" 1 "Charging mode" 0 "none" ;
VAL_TABLE_ appl_chg_mode_req_Copy_3 6 "Stop Charging" 5 "Renegotation" 4 "Start welding detection" 3 "Start power delivery" 2 "Precharge completed" 1 "Negotating Charging Parameters" 0 "None" ;
VAL_TABLE_ AMB_TEMP_Copy_3 127 "SNA" ;
VAL_TABLE_ Air_Pressure_Out_of_Range_Copy_3 1 "solenoids is out of range" 0 "solenoids is in normal range" ;
VAL_TABLE_ Wakeup_Rsn_Copy_2 255 "Snaa" 5 "Clamp15" 4 "Switch" 3 "RTC" 2 "Plug Present" 1 "Control_pilot" 0 "Network" ;
VAL_TABLE_ Vehicle_renegotiate_Copy_2 3 "SNA" 2 "Error" 1 "Requested" 0 "Not_requested" ;
VAL_TABLE_ Vehicle_contactor_status_Copy_2 3 "SNA" 2 "Stuck" 1 "Close" 0 "Open" ;
VAL_TABLE_ vehicle_chg_status_Copy_2 3 "Description for the value '0x3'" 2 "reserved" 1 "start_charging" 0 "stop_charging" ;
VAL_TABLE_ Vehicle_charge_selection_Copy_2 3 "SNA" 2 "error" 1 "secondary node" 0 "Primary node" ;
VAL_TABLE_ Vehicle_charge_permission_Copy_2 3 "Stop" 2 "Emergency stop" 1 "allowed" 0 "Not allowed" ;
VAL_TABLE_ VCVCCU_V2G_EVErrorCode_Copy_2 11 "No data" 10 "CHARGING_SYSTEM_INCOMPATIBILITY" 9 "RESERVED_C" 8 "RESERVED_B" 7 "RESERVED_A" 6 "CHARGING_VOLTAGE_OUT_OF_RANGE" 5 "FAILCHARGCURRENTDIFFERENTIAL" 4 "FAILED_EVRESSMALFUNCTION" 3 "FAILChargeCONNECT_LOCK_FAULT" 2 "FAILED_EVSHIFT_POSITION" 1 "FAILED_RESSTEMPERATURE_INHIBIT" 0 "NO_ERROR" ;
VAL_TABLE_ VCVCCU_V2G_Core_StackError_Copy_ 16 "StackError_PBufToSmall" 15 "StackError_InvalidKeyPair" 14 "StackError_NvM" 13 "StackError_NegativeResponseCode" 12 "StackError_InvalidRxParameter" 11 "StackError_InvalidRxMessage" 10 "StackError_Crypto" 9 "StackError_XmlSecurity" 8 "StackError_Exi" 7 "StackError_IpBase" 6 "StackError_Timeout" 5 "Timeout_RequestNotAcknowledged" 4 "Timeout_RequestAcknowledged" 3 "StackError_InvalidTxParameter" 2 "StackError_TransportLayer" 1 "StackError_SLAC" 0 "StackError_NoError" ;
VAL_TABLE_ VCVCCU_V2G_Core_SDPSecurityTx_Co 16 "SDPSecurity_None" 0 "SDPSecurity_Tls" ;
VAL_TABLE_ VCVCCU_V2G_Core_SAPSchemaID_Copy 4 "SAPSchemaIDs_None" 3 "NumOfSupportedSchemas" 2 "SAPSchemaIDs_DIN" 1 "SAPSchemaIDs_ISO_Ed2_CD" 0 "SAPSchemaIDs_ISO" ;
VAL_TABLE_ VCCU_mobile_status_Copy_2 3 "SNA" 2 "Vehicle immobile Fault" 1 "Vehicle Imobile" 0 "Vehicle mobile" ;
VAL_TABLE_ VCCU_Diag_Active_Copy_2 1 "Diag_no_active" 0 "Diag_active" ;
VAL_TABLE_ VCCU_Charge_unit_request_Copy_2 3 "SNA" 2 "Enable ventilation" 1 "Enable" 0 "Disable" ;
VAL_TABLE_ VCCU_8bit_Eroor_Copy_2 255 "SNA" 254 "Error" ;
VAL_TABLE_ VCCU_16bit_error_Copy_2 65535 "SNA" 65534 "Error" ;
VAL_TABLE_ V2G_SAP_response_code_Copy_2 2 "FAILED_NO_NEGOTIATION" 1 "OKNEGOTIAMINOR_DEVIATION" 0 "OK_SUCCESSFUL_NEGOTIATION" ;
VAL_TABLE_ V2G_core_msg_status_Copy_2 50 "StopCommunicationSession_Failed" 49 "StopCommunicationSession_OK" 48 "MsgStatus_SessionStop_Failed" 47 "MsgStatus_SessionStop_OK" 46 "WeldingDetection_Failed" 45 "MsgStatus_WeldingDetection_OK" 44 "MsgStatus_CurrentDemand_Failed" 43 "MsgStatus_CurrentDemand_OK" 42 "MsgStatus_PreCharge_Failed" 41 "MsgStatus_PreCharge_OK" 40 "MsgStatus_CableCheck_Failed" 39 "MsgStatus_CableCheck_OK" 38 "MsgStatus_ChargingStatus_Failed" 37 "MsgStatus_ChargingStatus_OK" 36 "MsgStatus_MeteringReceipt_Failed" 35 "MsgStatus_MeteringReceipt_OK" 34 "MsgStatus_PowerDelivery_Failed" 33 "MsgStatus_PowerDelivery_OK" 32 "ChargeParameterDiscovery_Failed" 31 "ChargeParameterDiscovery_OK" 30 "MsgStatus_Authorization_Failed" 29 "MsgStatus_Authorization_OK" 28 "MsgStatus_PaymentDetails_Failed" 27 "PaymentDetails_OK" 26 "CertificateUpdate_Failed" 25 "CertificateUpdate_OK" 24 "CertificateInstallation_Failed" 23 "CertificateInstallation_OK" 22 "MsgStatus_ReadProvCert_Failed" 21 "MsgStatus_ReadProvCert_OK" 20 "WrapperReadRootCerts_Failed" 19 "MsgStatus_ReadRootCerts_OK" 18 "PaymentServiceSelection_Failed" 17 "PaymentServiceSelection_OK" 16 "MsgStatus_ServiceDetail_Failed" 15 "MsgStatus_ServiceDetail_OK" 14 "ReadContrCertChain_Failed" 13 "ReadContrCertChain_OK" 12 "ServiceDiscovery_Failed" 11 "MsgStatus_ServiceDiscovery_OK" 10 "MsgStatus_SessionSetup_Failed" 9 "MsgStatus_SessionSetup_OK" 8 "SupportedAppProtocol_Failed" 7 "SupportedAppProtocol_OK" 6 "MsgStatus_TransportLayer_Failed" 5 "MsgStatus_TransportLayer_OK" 4 "SECCDiscoveryProtocol_Failed" 3 "SECCDiscoveryProtocol_OK" 2 "MsgStatus_SLAC_Failed" 1 "MsgStatus_SLAC_OK" 0 "MsgStatus_None" ;
VAL_TABLE_ V2G_core_msg_state_Copy_2 5 "msgstate_timeout" 4 "msgstate_response_received" 3 "msgstate_transmission_confirmed" 2 "msgstate_request_sent" 1 "msgstate_streaming_request" 0 "Msg_state_waitfor next_request" ;
VAL_TABLE_ UpShift_In_Progress_Copy_2 1 "High gear Shift is in progress" 0 "High Shift is not in progress" ;
VAL_TABLE_ Upshift_Failed_Copy_2 1 "shift to High gear failed" 0 "shift to High gear successful" ;
VAL_TABLE_ Tolerance_unit_Copy_2 9 "WH" 8 "W_S" 7 "W" 6 "VA" 5 "V" 4 "HA" 3 "A" 2 "S" 1 "M" 0 "H" ;
VAL_TABLE_ timer_status_Copy_2 3 "SNA" 2 "Elapsed" 1 "Running" 0 "Stopped" ;
VAL_TABLE_ TCU_System_type_Copy_2 0 "Unknown" ;
VAL_TABLE_ Sw_Status_Copy_2 3 "sna" 2 "Error" 1 "Pressed" 0 "Not Pressed" ;
VAL_TABLE_ StateM_machine_error_Copy_2 20 "SMER_InvalidControlPilotState" 19 "PaymtServiceSelect_ServMismatch" 18 "InitialAlignmentCheckOngoinTimer" 17 "SMER_Timer_PairingOngoingTimer" 16 "Timer_FinePositionOngoingTimer" 15 "SMER_StackError" 14 "NoContractInstallatiServiceAvbl" 13 "NoContractCertificateServiceAvlb" 12 "NoSharedPaymentOption" 11 "InvalidEnergyTransferMode" 10 "Discovery_NoSharedSecurityOption" 9 "InitializatContrctSelectiFailed" 8 "SMER_Timer_PreChargeOngoingTimer" 7 "Timer_CableCheckOngoingTimer" 6 "ChargeParmtrDiscveryOngoingTimer" 5 "Timer_AuthorizationOngoingTimer" 4 "SMETimer_ReadyToChargeTimer" 3 "Timer_CommunicationSetupTimer" 2 "SMER_Timer_SequencePerformTimer" 1 "SMER_Timer_IPAddressWaitTimer" 0 "SMER_NoError" ;
VAL_TABLE_ state_msg_state_Copy_2 3 "SMMS_WaitingForApplication" 2 "SMMS_ProcessingResponse" 1 "SMMS_WaitingForResponse" 0 "SMMS_PreparingRequest" ;
VAL_TABLE_ state_mchine_status_Copy_2 32 "PowerDemand" 31 "InitialAlignmentCheck" 30 "Pairing" 29 "FinePositioning" 28 "FinePositioningSetup" 27 "Error_Stopped" 26 "Error_WaitForRetry" 25 "Finished" 24 "StopCommunicationSession" 23 "SessionStop" 22 "WeldingDetection" 21 "MeteringReceipt" 20 "CurrentDemand" 19 "ChargingStatus" 18 "PowerDelivery" 17 "PreCharge" 16 "CableCheck" 15 "ChargeParameterDiscovery" 14 "Authorization" 13 "PaymentDetails" 12 "CertificateUpdate" 11 "CertificateInstallation" 10 "PaymentServiceSelection" 9 "ServiceDetails" 8 "ServiceDiscovery" 7 "SessionSetup" 6 "SupportedAppProtocol" 5 "TLConnection" 4 "SECCDiscoveryProtocol" 3 "WaitForIP" 2 "SLAC" 1 "Initialized" 0 "None" ;
VAL_TABLE_ ST_SER_DSCO_PLG_Copy_2 3 "Description for the value '0x2'" 2 "Service Disconnector Connected" 1 "Service Disconnector Open" ;
VAL_TABLE_ ST_MEASMT_ISL_Copy_2 3 "Signal Invalid" 2 "Iso measurement  running" 1 "Iso measurement not running" ;
VAL_TABLE_ ST_ERR_ISL_EXTN_BN_HV_VT_Copy_2 3 "Signal Invalid" 2 "Active" 1 "Not Active" 0 "No statement possible" ;
VAL_TABLE_ ST_AC_CHGNG_EPRG_Copy_2 2 "Signal Invalid" 1 "Activated" 0 "Deactivated" ;
VAL_TABLE_ SNA_Copy_2 255 "SNA" ;
VAL_TABLE_ Slow_Upshift_Copy_2 1 "Shift require more amnt of time" 0 "Shift in a normal amount of time" ;
VAL_TABLE_ Shift_Disabled_Copy_2 1 "Gear shift disabled" 0 "Gear shift not disabled" ;
VAL_TABLE_ Self_Diag_Status_Copy_2 7 "SNA" 6 "Error" 5 "Short Btw pins" 4 "Supply Voltage Failure'" 3 "Open Load" 2 "Short to Batt" 1 "Short to GND" 0 "Ok" ;
VAL_TABLE_ Selected_Gear_Copy_2 3 "Shift in Progress" 2 "High" 1 "Low" 0 "Neutral" ;
VAL_TABLE_ RTC_req_Copy_2 3 "SNA" 2 "reserved" 1 "requested" 0 "Not requested" ;
VAL_TABLE_ RQ_CHGRDI_Copy_2 2 "Char with depa time and cond" 1 "Plug & Charge (default)" 0 "no charging" ;
VAL_TABLE_ Retract_status_Copy_2 3 "Not avalible" 2 "Error" 1 "Ramp Extracted" 0 "Ramp retracted" ;
VAL_TABLE_ Resistance_Copy_2 7 "SNA" 6 "Error" 5 "S3_480_ohm" 4 "S3_150_ohm" 3 "1500 Ohm" 2 "680 ohm" 1 "220 Ohm" 0 "100 Ohm" ;
VAL_TABLE_ Ramp_move_Copy_2 3 "Not availble" 2 "error" 1 "Ramp being move" 0 "ramp being not move" ;
VAL_TABLE_ Ramp_enable_Copy_2 3 "not available" 2 "error" 1 "enable" 0 "disable" ;
VAL_TABLE_ PWM_charge_mode_req_Copy_2 3 "Description for the value '0x3'" 2 "Error" 1 "PWM_charge_mode_request_D" 0 "PWM_charge_mode_request_C" ;
VAL_TABLE_ PTC_diag_Copy_2 7 "SNA" 6 "Error" 5 "Reserved 1" 4 "Out of range" 3 "Open Load" 2 "Short to Batt" 1 "Short to GND" 0 "Ok" ;
VAL_TABLE_ PTC2_Copy_2 7 "SNA" 6 "reserved3" 5 "reserved2" 4 "reserved1" 3 "Open Load" 2 "Short to Batt" 1 "Short to GND" 0 "Ok" ;
VAL_TABLE_ Precond_desire_Copy_2 255 "SNA" 1 "Yes" 0 "No" ;
VAL_TABLE_ Pre_HVAC_Copy_2 3 "SNA" 2 "no_warm water , cool & venti" 1 "hot water and heating" 0 "only warm water , ventilation" ;
VAL_TABLE_ Pos_Feedback_Copy_2 7 "SNA" 6 "Reseved3" 5 "Reserved2" 4 "Reserved1" 3 "Open Load" 2 "Short to Batt" 1 "Short to GND" 0 "Ok" ;
VAL_TABLE_ Plug_present_self_diag_Copy_2 7 "SNA" 6 "Reseved3" 5 "Reserved2" 4 "Reserved1" 3 "Open Load" 2 "Short to Batt" 1 "Short to GND" 0 "Ok" ;
VAL_TABLE_ plug_lock_permission_Copy_2 3 "Description for the value '0x3'" 2 "Reserved" 1 "Allowed" 0 "Not_allowed" ;
VAL_TABLE_ PKP_number_Copy_2 3 "Key 4" 2 "Key 3" 1 "Key 2" 0 "Key 1" ;
VAL_TABLE_ Openstatusofdoor1_Copy_2 3 "Not availble" 2 "Error" 1 "Open" 0 "Closed" ;
VAL_TABLE_ Nm01_Copy_2 1 "Charg_Comm_active" 0 "Charg_Comm_not _active" ;
VAL_TABLE_ New_Value_Table_151_Copy_2 11 "reserved c" 10 "reserved B" 9 "Reserved A" 8 "Reserved 9" 7 "Reserved 8" 6 "EVSE Malfunction" 5 "EVSE Emergency Shutdwon" 4 "EVSE Isolation Monitoring Active" 3 "EVSE Utility Interrupt Event" 2 "EVSE Shutdown" 1 "EVSE Ready" 0 "EVSE_Not_Ready" ;
VAL_TABLE_ Motor_Req_Copy_2 7 "SNA" 6 "Reserved3" 5 "Reserved2" 4 "Reserved1" 3 "Measurement" 2 "Direction B" 1 "Directon A" 0 "Stop" ;
VAL_TABLE_ Motor_L_U_Copy_2 3 "SNA" 2 "Reserved" 1 "Unlock" 0 "Lock" ;
VAL_TABLE_ Modes_Copy_2 1 "Battery mode" 0 "Heating mode" ;
VAL_TABLE_ MCU_System_Type_Copy_2 15 "Undefined" 14 "Undefined" 13 "Undefined" 12 "Undefined" 11 "Undefined" 10 "Undefined" 9 "Undefined" 8 "Undefined" 7 "EM-PMI318B-T360-465V" 6 "Undefined" 5 "EM-PMI318B-T520E-465V" 4 "EM-PMI318B-T440E-255V" 3 "EM-PMI318-T400-255V" 2 "EM-PMI318-T360-425V" 1 "EM-PMI318-T350-255V" 0 "UnKnown" ;
VAL_TABLE_ lockstatusofdoor1_Copy_2 3 "Not Available" 2 "Error" 1 "lock" 0 "Unlock" ;
VAL_TABLE_ Lock_motor_Copy_2 7 "SNA" 6 "Error" 5 "Reserved2" 4 "Resserved1" 3 "Measurement" 2 "Direction B" 1 "Direction A" 0 "Idle" ;
VAL_TABLE_ LIN_Freq_Copy_2 255 "Not Available" 1 "60 Hz" 0 "50 Hz" ;
VAL_TABLE_ LIN_EV_Frequencies_Copy_2 255 "Not available" 2 "both 50 Hz_60 Hz" 1 "only 60 Hz" 0 "only 50 Hz" ;
VAL_TABLE_ Limit_mode_Copy_2 15 "Error indicator" 14 "Not Available" 11 "External output voltage limit" 10 "Internal output voltage limit" 9 "External current limitation" 8 "High side current limitation" 7 "High side power limitation" 6 "coolant temp limitation" 5 "Power stage temp limitation" 4 "High input voltage limitation" 3 "low input voltage limitation" 2 "Event limitation" 1 "Maximum current limitatio" 0 "No Limitation" ;
VAL_TABLE_ LED_State_Copy_2 3 "Description for the value '0x3'" 2 "Off" 1 "On" 0 "Off" ;
VAL_TABLE_ LED_colour_Secondary_colour_Copy 9 "Yellow / Green  " 8 "Amber / Orange" 7 "White / Light blue " 6 "Magneta" 5 "Cyan" 4 "Yellow" 3 "Blue" 2 "Green" 1 "Red" 0 "Off" ;
VAL_TABLE_ isolation_mesmt_req_Copy_2 3 "Description for the value '0x3'" 2 "reserved" 1 "requested" 0 "Not_requested" ;
VAL_TABLE_ isolate_mesmt_status_Copy_2 3 "SNA" 2 "Error" 1 "Active" 0 "Not active" ;
VAL_TABLE_ inlet_motor_status_Copy_2 7 "SNA" 6 "Error" 5 "Reserved3" 4 "Reserved2" 3 "Reserved1" 2 "Moving" 1 "Locked" 0 "Unlocked" ;
VAL_TABLE_ Hw_varient_Copy_2 3 "SNA" 2 "reserved" 1 "Combo1 inlet" 0 "Combo2 " ;
VAL_TABLE_ HS_req_Copy_2 3 "SNA" 2 "Reserved" 1 "Enable" 0 "Disable" ;
VAL_TABLE_ high_side_diag_Copy_2 7 "SNA" 6 "Error" 5 "Short Btw pins" 4 "Inverse Currrent" 3 "Open Load" 2 "Short to Batt" 1 "Short to GND" 0 "Ok" ;
VAL_TABLE_ Forced_Gear_Engagement_Torque_Co 1 "TCU imposing min torque reqt" 0 "TCU not imposing min torque reqt" ;
VAL_TABLE_ EVSE_resp_code_Copy_2 26 "FAILED_CERTIFICATE_REVOKED" 25 "FAILED_CERTIFICATE_NOT_ALLOW_e" 24 "FAILED_CONTACTOR_ERROR" 22 "FAILED_WRNG_ENRGY_TRNSFER_TYPE" 21 "FAILED_NO_CHARGE_SERVICE_SELECt" 20 "FAILED_MTRING_SIGNTURE_NOT_VALID" 19 "FAILED_CHARGING_PROFILE_INVALID" 18 "FAILED_TARIFF_SELECTION_INVALID" 17 "FAILED_POWER_DELIVERY_NOT_APPLy" 16 "FAILED_WRONG_CHARGE_PARAMETER" 15 "FAILED_CONTRACT_CANCELED" 14 "FAILED_CHALLENGE_INVALID" 13 "FAILED_CERT_CHAIN_ERROR" 12 "FAILED_NO_CERTIFICATE_AVAILABLE" 11 "FAILED_SIGNATURE_ERROR" 10 "FAILED_CERTIFICATE_EXPIRED" 9 "FAILED_PAYMENT_SELECTION_INVALID" 8 "FAILED_SERVICE_SELECTION_INVALID" 7 "FAILED_UNKNOWN_SESSION" 6 "FAILED_SERVICE_IDINVALID" 5 "FAILED_SEQUENCE_ERROR" 4 "FAILED" 3 "OK_CERTIFICATE_EXPIRES_SOON" 2 "OK_OLD_SESSION_JOINED" 1 "OK_NEW_SESSION_ESTABLISHED" 0 "OK" ;
VAL_TABLE_ EVSE_Process_Copy_2 1 "ongoing" 0 "Finished" ;
VAL_TABLE_ EVSE_notification_Copy_2 2 "Re_Negotation" 1 "Stop Charging" 0 "None" ;
VAL_TABLE_ EVSE_isoltae_status_Copy_2 4 "No_Imd" 3 "Fault" 2 "Warning" 1 "Valid" 0 "Invalid" ;
VAL_TABLE_ energy_trans_mode_Copy_2 32 "Description for the value '0x18'" 16 "Energy_transfermode_combo_core" 8 "Energy_transfermode_DC_extend" 4 "Energy_transfermode_DCcore" 2 "Energy_transfermode_AC_3P" 1 "Energy_transfermode_AC_1P" 0 "Energy_transfermode_none" ;
VAL_TABLE_ energy_mode_Copy_2 15 "undefined" 5 "DC_unique" 4 "DC_combo_core" 3 "DC_extended" 2 "DC_core" 1 "AC_three_phase_core" 0 "Ac_single_phse_core" ;
VAL_TABLE_ E2E_state_charge_vehicle_Copy_2 32 "NoDATA_OK" 5 "Valid_NND" 3 "Valid_Error" 2 "Valid_SEQ" 1 "Valid_REP" 0 "Valid_Ok" ;
VAL_TABLE_ e2e_state_Copy_2 255 "Hard_run_time_error" 119 "Soft_run_time_error" 69 "Invalid_NND" 67 "Invalid_Error" 66 "Invalid_SEQ" 65 "Invalid_REP" 64 "Invalid_Ok" 53 "Init_NND" 51 "Init_error" 50 "Init_SEQ" 49 "Init_REP" 48 "Init_Ok" 37 "No_Data_NND" 35 "No_data_error" 34 "No_data_SEQ" 33 "No_data_REP" 32 "No_data_ok" 5 "valid NND" 3 "valid Error" 2 "valid SEQ" 1 "valid REP" 0 "valid ok" ;
VAL_TABLE_ Down_Shift_In_progress_Copy_2 1 "High gear Shift is in progress" 0 "High Shift is not in progress" ;
VAL_TABLE_ Down_Shift_failed_Copy_2 1 "shift to low gear failed" 0 "shift to Low gear Successful" ;
VAL_TABLE_ Door_Enable_Copy_2 2 "Not available" 1 "Error" 0 "Enabled" ;
VAL_TABLE_ DM13_suspend_signal_Copy_2 15 "not available" 14 "ResumingNormalpattern" 3 "Temporarysuspensionofsomemsg" 2 "Temporarysuspensionofallmsg" 1 "Indefinitesuspensionofsomemsg" 0 "Indefinitesuspensionofallmsg" ;
VAL_TABLE_ DM13_hold_signal_Copy_2 15 "Not available" 1 "Devices whose broadcast state" 0 "All Devices" ;
VAL_TABLE_ DilongDCDC_Faults_Copy_2 256 "Communication fault" 128 "Internal fault" 64 "Output short circuit protection" 32 "Input under voltage" 16 "Input over voltage" 8 "Output under voltage" 4 "Output over voltage" 2 "Output over current" 1 "Over temperature shutdown" ;
VAL_TABLE_ dept_Copy_2 0 "SNA" ;
VAL_TABLE_ DCDC_control_Copy_2 15 "Error Indicator" 14 "Not availble" 13 "Error state" 12 "Shutting down" 2 "Current control" 1 "Voltage control" 0 "Standby" ;
VAL_TABLE_ D_OBC_Mode_Copy_2 1 "Heating" 0 "Battery" ;
VAL_TABLE_ D_OBC_Charging_status_flag_Copy_ 16 "0 com normal 1 com timeout" 8 "0 start state 1 off" 4 "0 normal 1 input volt error" 2 "0 normal 1 charg temp too high" 1 "0 normal 1 HW failure" ;
VAL_TABLE_ D_OBC_Charging_state_Copy_2 2 "Charging complete" 1 "Bat prote,charger turn off op" 0 "The charger starts charging " ;
VAL_TABLE_ D_OBC_Charging_boot_status_Copy_ 32 "0 normal 1 alarm" 16 "0 normal 1 alarm" 8 "0 normal 1 alarm" 4 "2 fault 3 no electic lock" 2 "0 unlock 1 lock" 1 "0 disconnect 1 HW close" ;
VAL_TABLE_ D_DCDC_Switch_Control_Copy_2 1 "Shutdown" 0 "Power on" ;
VAL_TABLE_ D_DCDC_status_Copy_2 1 "Stop" 0 "Work" ;
VAL_TABLE_ D_DCDC_Fault_list_Copy_2 32768 "Reserve" 16384 "Reserve" 8192 "Reserve" 4096 "Reserve" 2048 "Reserve" 1024 "Reserve" 512 "Reserve" 256 "Communication fault alarm" 128 "Internal fault alarm " 64 "Output shortcircuit protection " 32 "Input under voltage alarm " 16 "Input over-voltage alarm" 8 "Output undervoltage alarm" 4 "Output over-voltage alarm" 2 "Output over-current alarm" 1 "Over temperature shutdown" ;
VAL_TABLE_ Current_Transmission_Mode_Copy_2 3 "Forward Low" 2 "Forward Automatic" 1 "Reverse" 0 "Neutral" ;
VAL_TABLE_ CTR_FKTN_PRTNT_DRV_Copy_2 -2147483648 "Signal invalid" ;
VAL_TABLE_ CTR_BS_PRTNT_DRV_Copy_2 65535 "Signal Invalid" ;
VAL_TABLE_ Cp_wakeup_Copy_2 3 "sna" 2 "error" 1 "wakeup detected" 0 "wakeup not detected" ;
VAL_TABLE_ CP_chrage_mode_req_Copy_2 7 "SNA" 6 "Error" 5 "Reserved 3" 4 "Reserved 2" 3 "Reserved 1" 2 "Mode D" 1 "Mode C" 0 "Mode B" ;
VAL_TABLE_ Controlmode_Copy_2 3 "take no action" 2 "reserved" 1 "Current control" 0 "Voltage control " ;
VAL_TABLE_ Contactor_req_Copy_2 3 "Description for the value '0x3'" 2 "force_open" 1 "close" 0 "open" ;
VAL_TABLE_ connection_status_Copy_2 3 "Description for the value '0x3'" 2 "error" 1 "connected" 0 "not connected" ;
VAL_TABLE_ CommandEnableDCC2_Copy_2 3 "Take no action" 2 "Reserved" 1 "Enable" 0 "Standby" ;
VAL_TABLE_ Clamp_15_active_Copy_2 1 "Clamp_15_noactive" 0 "Clamp15_Active" ;
VAL_TABLE_ chg_unit_state_Copy_2 7 "SNA" 6 "EVSE State F" 5 "EVSE State E" 4 "EVSE State D" 3 "EVSE State C" 2 "EVSE State B2" 1 "EVSE state B1" 0 "EVSE state A" ;
VAL_TABLE_ chg_unit_mode_Copy_2 7 "sna" 6 "error" 5 "reserved" 4 "Charge Pantograph" 3 "Charging LIN" 2 "Charging Not allowed" 1 "Charge PWM" 0 "Charge V2G" ;
VAL_TABLE_ chg_selct_ack_Copy_2 3 "sna" 2 "error" 1 "secondary node" 0 "primary_node" ;
VAL_TABLE_ Charge_State_Copy_2 2 "Charging complete" 1 "Bat prtect charger turn off" 0 "Charger start charging" ;
VAL_TABLE_ Charge_Comm_Active_Copy_2 1 "Description for the value '0x1'" 0 "Charg_Comm_Active" ;
VAL_TABLE_ Charg_Lin_Active_Copy_2 1 "Charg_Lin_Non active" 0 "Charg_Lin_Active" ;
VAL_TABLE_ Broadcast_Copy_2 3 "dont care" 2 "reserved" 1 "start broadcast" 0 "Stop broadcast" ;
VAL_TABLE_ Brakes_Copy_2 3 "Not available" 2 "Error indicator" 1 "Fuel level sufficient" 0 "Fuel level not sufficient" ;
VAL_TABLE_ Boolean_Copy_2 1 "True" 0 "False" ;
VAL_TABLE_ appl_func_mode_req_Copy_2 2 "Reset" 1 "Charging mode" 0 "none" ;
VAL_TABLE_ appl_chg_mode_req_Copy_2 6 "Stop Charging" 5 "Renegotation" 4 "Start welding detection" 3 "Start power delivery" 2 "Precharge completed" 1 "Negotating Charging Parameters" 0 "None" ;
VAL_TABLE_ AMB_TEMP_Copy_2 127 "SNA" ;
VAL_TABLE_ Air_Pressure_Out_of_Range_Copy_2 1 "solenoids is out of range" 0 "solenoids is in normal range" ;
VAL_TABLE_ Wakeup_Rsn_Copy_1 255 "Snaa" 5 "Clamp15" 4 "Switch" 3 "RTC" 2 "Plug Present" 1 "Control_pilot" 0 "Network" ;
VAL_TABLE_ Vehicle_renegotiate_Copy_1 3 "SNA" 2 "Error" 1 "Requested" 0 "Not_requested" ;
VAL_TABLE_ Vehicle_contactor_status_Copy_1 3 "SNA" 2 "Stuck" 1 "Close" 0 "Open" ;
VAL_TABLE_ vehicle_chg_status_Copy_1 3 "Description for the value '0x3'" 2 "reserved" 1 "start_charging" 0 "stop_charging" ;
VAL_TABLE_ Vehicle_charge_selection_Copy_1 3 "SNA" 2 "error" 1 "secondary node" 0 "Primary node" ;
VAL_TABLE_ Vehicle_charge_permission_Copy_1 3 "Stop" 2 "Emergency stop" 1 "allowed" 0 "Not allowed" ;
VAL_TABLE_ VCVCCU_V2G_EVErrorCode_Copy_1 11 "No data" 10 "CHARGING_SYSTEM_INCOMPATIBILITY" 9 "RESERVED_C" 8 "RESERVED_B" 7 "RESERVED_A" 6 "CHARGING_VOLTAGE_OUT_OF_RANGE" 5 "FAILCHARGCURRENTDIFFERENTIAL" 4 "FAILED_EVRESSMALFUNCTION" 3 "FAILChargeCONNECT_LOCK_FAULT" 2 "FAILED_EVSHIFT_POSITION" 1 "FAILED_RESSTEMPERATURE_INHIBIT" 0 "NO_ERROR" ;
VAL_TABLE_ VCVCCU_V2G_Core_StackError_Copy_ 16 "StackError_PBufToSmall" 15 "StackError_InvalidKeyPair" 14 "StackError_NvM" 13 "StackError_NegativeResponseCode" 12 "StackError_InvalidRxParameter" 11 "StackError_InvalidRxMessage" 10 "StackError_Crypto" 9 "StackError_XmlSecurity" 8 "StackError_Exi" 7 "StackError_IpBase" 6 "StackError_Timeout" 5 "Timeout_RequestNotAcknowledged" 4 "Timeout_RequestAcknowledged" 3 "StackError_InvalidTxParameter" 2 "StackError_TransportLayer" 1 "StackError_SLAC" 0 "StackError_NoError" ;
VAL_TABLE_ VCVCCU_V2G_Core_SDPSecurityTx_Co 16 "SDPSecurity_None" 0 "SDPSecurity_Tls" ;
VAL_TABLE_ VCVCCU_V2G_Core_SAPSchemaID_Copy 4 "SAPSchemaIDs_None" 3 "NumOfSupportedSchemas" 2 "SAPSchemaIDs_DIN" 1 "SAPSchemaIDs_ISO_Ed2_CD" 0 "SAPSchemaIDs_ISO" ;
VAL_TABLE_ VCCU_mobile_status_Copy_1 3 "SNA" 2 "Vehicle immobile Fault" 1 "Vehicle Imobile" 0 "Vehicle mobile" ;
VAL_TABLE_ VCCU_Diag_Active_Copy_1 1 "Diag_no_active" 0 "Diag_active" ;
VAL_TABLE_ VCCU_Charge_unit_request_Copy_1 3 "SNA" 2 "Enable ventilation" 1 "Enable" 0 "Disable" ;
VAL_TABLE_ VCCU_8bit_Eroor_Copy_1 255 "SNA" 254 "Error" ;
VAL_TABLE_ VCCU_16bit_error_Copy_1 65535 "SNA" 65534 "Error" ;
VAL_TABLE_ V2G_SAP_response_code_Copy_1 2 "FAILED_NO_NEGOTIATION" 1 "OKNEGOTIAMINOR_DEVIATION" 0 "OK_SUCCESSFUL_NEGOTIATION" ;
VAL_TABLE_ V2G_core_msg_status_Copy_1 50 "StopCommunicationSession_Failed" 49 "StopCommunicationSession_OK" 48 "MsgStatus_SessionStop_Failed" 47 "MsgStatus_SessionStop_OK" 46 "WeldingDetection_Failed" 45 "MsgStatus_WeldingDetection_OK" 44 "MsgStatus_CurrentDemand_Failed" 43 "MsgStatus_CurrentDemand_OK" 42 "MsgStatus_PreCharge_Failed" 41 "MsgStatus_PreCharge_OK" 40 "MsgStatus_CableCheck_Failed" 39 "MsgStatus_CableCheck_OK" 38 "MsgStatus_ChargingStatus_Failed" 37 "MsgStatus_ChargingStatus_OK" 36 "MsgStatus_MeteringReceipt_Failed" 35 "MsgStatus_MeteringReceipt_OK" 34 "MsgStatus_PowerDelivery_Failed" 33 "MsgStatus_PowerDelivery_OK" 32 "ChargeParameterDiscovery_Failed" 31 "ChargeParameterDiscovery_OK" 30 "MsgStatus_Authorization_Failed" 29 "MsgStatus_Authorization_OK" 28 "MsgStatus_PaymentDetails_Failed" 27 "PaymentDetails_OK" 26 "CertificateUpdate_Failed" 25 "CertificateUpdate_OK" 24 "CertificateInstallation_Failed" 23 "CertificateInstallation_OK" 22 "MsgStatus_ReadProvCert_Failed" 21 "MsgStatus_ReadProvCert_OK" 20 "WrapperReadRootCerts_Failed" 19 "MsgStatus_ReadRootCerts_OK" 18 "PaymentServiceSelection_Failed" 17 "PaymentServiceSelection_OK" 16 "MsgStatus_ServiceDetail_Failed" 15 "MsgStatus_ServiceDetail_OK" 14 "ReadContrCertChain_Failed" 13 "ReadContrCertChain_OK" 12 "ServiceDiscovery_Failed" 11 "MsgStatus_ServiceDiscovery_OK" 10 "MsgStatus_SessionSetup_Failed" 9 "MsgStatus_SessionSetup_OK" 8 "SupportedAppProtocol_Failed" 7 "SupportedAppProtocol_OK" 6 "MsgStatus_TransportLayer_Failed" 5 "MsgStatus_TransportLayer_OK" 4 "SECCDiscoveryProtocol_Failed" 3 "SECCDiscoveryProtocol_OK" 2 "MsgStatus_SLAC_Failed" 1 "MsgStatus_SLAC_OK" 0 "MsgStatus_None" ;
VAL_TABLE_ V2G_core_msg_state_Copy_1 5 "msgstate_timeout" 4 "msgstate_response_received" 3 "msgstate_transmission_confirmed" 2 "msgstate_request_sent" 1 "msgstate_streaming_request" 0 "Msg_state_waitfor next_request" ;
VAL_TABLE_ UpShift_In_Progress_Copy_1 1 "High gear Shift is in progress" 0 "High Shift is not in progress" ;
VAL_TABLE_ Upshift_Failed_Copy_1 1 "shift to High gear failed" 0 "shift to High gear successful" ;
VAL_TABLE_ Tolerance_unit_Copy_1 9 "WH" 8 "W_S" 7 "W" 6 "VA" 5 "V" 4 "HA" 3 "A" 2 "S" 1 "M" 0 "H" ;
VAL_TABLE_ timer_status_Copy_1 3 "SNA" 2 "Elapsed" 1 "Running" 0 "Stopped" ;
VAL_TABLE_ TCU_System_type_Copy_1 0 "Unknown" ;
VAL_TABLE_ Sw_Status_Copy_1 3 "sna" 2 "Error" 1 "Pressed" 0 "Not Pressed" ;
VAL_TABLE_ StateM_machine_error_Copy_1 20 "SMER_InvalidControlPilotState" 19 "PaymtServiceSelect_ServMismatch" 18 "InitialAlignmentCheckOngoinTimer" 17 "SMER_Timer_PairingOngoingTimer" 16 "Timer_FinePositionOngoingTimer" 15 "SMER_StackError" 14 "NoContractInstallatiServiceAvbl" 13 "NoContractCertificateServiceAvlb" 12 "NoSharedPaymentOption" 11 "InvalidEnergyTransferMode" 10 "Discovery_NoSharedSecurityOption" 9 "InitializatContrctSelectiFailed" 8 "SMER_Timer_PreChargeOngoingTimer" 7 "Timer_CableCheckOngoingTimer" 6 "ChargeParmtrDiscveryOngoingTimer" 5 "Timer_AuthorizationOngoingTimer" 4 "SMETimer_ReadyToChargeTimer" 3 "Timer_CommunicationSetupTimer" 2 "SMER_Timer_SequencePerformTimer" 1 "SMER_Timer_IPAddressWaitTimer" 0 "SMER_NoError" ;
VAL_TABLE_ state_msg_state_Copy_1 3 "SMMS_WaitingForApplication" 2 "SMMS_ProcessingResponse" 1 "SMMS_WaitingForResponse" 0 "SMMS_PreparingRequest" ;
VAL_TABLE_ state_mchine_status_Copy_1 32 "PowerDemand" 31 "InitialAlignmentCheck" 30 "Pairing" 29 "FinePositioning" 28 "FinePositioningSetup" 27 "Error_Stopped" 26 "Error_WaitForRetry" 25 "Finished" 24 "StopCommunicationSession" 23 "SessionStop" 22 "WeldingDetection" 21 "MeteringReceipt" 20 "CurrentDemand" 19 "ChargingStatus" 18 "PowerDelivery" 17 "PreCharge" 16 "CableCheck" 15 "ChargeParameterDiscovery" 14 "Authorization" 13 "PaymentDetails" 12 "CertificateUpdate" 11 "CertificateInstallation" 10 "PaymentServiceSelection" 9 "ServiceDetails" 8 "ServiceDiscovery" 7 "SessionSetup" 6 "SupportedAppProtocol" 5 "TLConnection" 4 "SECCDiscoveryProtocol" 3 "WaitForIP" 2 "SLAC" 1 "Initialized" 0 "None" ;
VAL_TABLE_ ST_SER_DSCO_PLG_Copy_1 3 "Description for the value '0x2'" 2 "Service Disconnector Connected" 1 "Service Disconnector Open" ;
VAL_TABLE_ ST_MEASMT_ISL_Copy_1 3 "Signal Invalid" 2 "Iso measurement  running" 1 "Iso measurement not running" ;
VAL_TABLE_ ST_ERR_ISL_EXTN_BN_HV_VT_Copy_1 3 "Signal Invalid" 2 "Active" 1 "Not Active" 0 "No statement possible" ;
VAL_TABLE_ ST_AC_CHGNG_EPRG_Copy_1 2 "Signal Invalid" 1 "Activated" 0 "Deactivated" ;
VAL_TABLE_ SNA_Copy_1 255 "SNA" ;
VAL_TABLE_ Slow_Upshift_Copy_1 1 "Shift require more amnt of time" 0 "Shift in a normal amount of time" ;
VAL_TABLE_ Shift_Disabled_Copy_1 1 "Gear shift disabled" 0 "Gear shift not disabled" ;
VAL_TABLE_ Self_Diag_Status_Copy_1 7 "SNA" 6 "Error" 5 "Short Btw pins" 4 "Supply Voltage Failure'" 3 "Open Load" 2 "Short to Batt" 1 "Short to GND" 0 "Ok" ;
VAL_TABLE_ Selected_Gear_Copy_1 3 "Shift in Progress" 2 "High" 1 "Low" 0 "Neutral" ;
VAL_TABLE_ RTC_req_Copy_1 3 "SNA" 2 "reserved" 1 "requested" 0 "Not requested" ;
VAL_TABLE_ RQ_CHGRDI_Copy_1 2 "Char with depa time and cond" 1 "Plug & Charge (default)" 0 "no charging" ;
VAL_TABLE_ Retract_status_Copy_1 3 "Not avalible" 2 "Error" 1 "Ramp Extracted" 0 "Ramp retracted" ;
VAL_TABLE_ Resistance_Copy_1 7 "SNA" 6 "Error" 5 "S3_480_ohm" 4 "S3_150_ohm" 3 "1500 Ohm" 2 "680 ohm" 1 "220 Ohm" 0 "100 Ohm" ;
VAL_TABLE_ Ramp_move_Copy_1 3 "Not availble" 2 "error" 1 "Ramp being move" 0 "ramp being not move" ;
VAL_TABLE_ Ramp_enable_Copy_1 3 "not available" 2 "error" 1 "enable" 0 "disable" ;
VAL_TABLE_ PWM_charge_mode_req_Copy_1 3 "Description for the value '0x3'" 2 "Error" 1 "PWM_charge_mode_request_D" 0 "PWM_charge_mode_request_C" ;
VAL_TABLE_ PTC_diag_Copy_1 7 "SNA" 6 "Error" 5 "Reserved 1" 4 "Out of range" 3 "Open Load" 2 "Short to Batt" 1 "Short to GND" 0 "Ok" ;
VAL_TABLE_ PTC2_Copy_1 7 "SNA" 6 "reserved3" 5 "reserved2" 4 "reserved1" 3 "Open Load" 2 "Short to Batt" 1 "Short to GND" 0 "Ok" ;
VAL_TABLE_ Precond_desire_Copy_1 255 "SNA" 1 "Yes" 0 "No" ;
VAL_TABLE_ Pre_HVAC_Copy_1 3 "SNA" 2 "no_warm water , cool & venti" 1 "hot water and heating" 0 "only warm water , ventilation" ;
VAL_TABLE_ Pos_Feedback_Copy_1 7 "SNA" 6 "Reseved3" 5 "Reserved2" 4 "Reserved1" 3 "Open Load" 2 "Short to Batt" 1 "Short to GND" 0 "Ok" ;
VAL_TABLE_ Plug_present_self_diag_Copy_1 7 "SNA" 6 "Reseved3" 5 "Reserved2" 4 "Reserved1" 3 "Open Load" 2 "Short to Batt" 1 "Short to GND" 0 "Ok" ;
VAL_TABLE_ plug_lock_permission_Copy_1 3 "Description for the value '0x3'" 2 "Reserved" 1 "Allowed" 0 "Not_allowed" ;
VAL_TABLE_ PKP_number_Copy_1 3 "Key 4" 2 "Key 3" 1 "Key 2" 0 "Key 1" ;
VAL_TABLE_ Openstatusofdoor1_Copy_1 3 "Not availble" 2 "Error" 1 "Open" 0 "Closed" ;
VAL_TABLE_ Nm01_Copy_1 1 "Charg_Comm_active" 0 "Charg_Comm_not _active" ;
VAL_TABLE_ New_Value_Table_151_Copy_1 11 "reserved c" 10 "reserved B" 9 "Reserved A" 8 "Reserved 9" 7 "Reserved 8" 6 "EVSE Malfunction" 5 "EVSE Emergency Shutdwon" 4 "EVSE Isolation Monitoring Active" 3 "EVSE Utility Interrupt Event" 2 "EVSE Shutdown" 1 "EVSE Ready" 0 "EVSE_Not_Ready" ;
VAL_TABLE_ Motor_Req_Copy_1 7 "SNA" 6 "Reserved3" 5 "Reserved2" 4 "Reserved1" 3 "Measurement" 2 "Direction B" 1 "Directon A" 0 "Stop" ;
VAL_TABLE_ Motor_L_U_Copy_1 3 "SNA" 2 "Reserved" 1 "Unlock" 0 "Lock" ;
VAL_TABLE_ Modes_Copy_1 1 "Battery mode" 0 "Heating mode" ;
VAL_TABLE_ MCU_System_Type_Copy_1 15 "Undefined" 14 "Undefined" 13 "Undefined" 12 "Undefined" 11 "Undefined" 10 "Undefined" 9 "Undefined" 8 "Undefined" 7 "EM-PMI318B-T360-465V" 6 "Undefined" 5 "EM-PMI318B-T520E-465V" 4 "EM-PMI318B-T440E-255V" 3 "EM-PMI318-T400-255V" 2 "EM-PMI318-T360-425V" 1 "EM-PMI318-T350-255V" 0 "UnKnown" ;
VAL_TABLE_ lockstatusofdoor1_Copy_1 3 "Not Available" 2 "Error" 1 "lock" 0 "Unlock" ;
VAL_TABLE_ Lock_motor_Copy_1 7 "SNA" 6 "Error" 5 "Reserved2" 4 "Resserved1" 3 "Measurement" 2 "Direction B" 1 "Direction A" 0 "Idle" ;
VAL_TABLE_ LIN_Freq_Copy_1 255 "Not Available" 1 "60 Hz" 0 "50 Hz" ;
VAL_TABLE_ LIN_EV_Frequencies_Copy_1 255 "Not available" 2 "both 50 Hz_60 Hz" 1 "only 60 Hz" 0 "only 50 Hz" ;
VAL_TABLE_ Limit_mode_Copy_1 15 "Error indicator" 14 "Not Available" 11 "External output voltage limit" 10 "Internal output voltage limit" 9 "External current limitation" 8 "High side current limitation" 7 "High side power limitation" 6 "coolant temp limitation" 5 "Power stage temp limitation" 4 "High input voltage limitation" 3 "low input voltage limitation" 2 "Event limitation" 1 "Maximum current limitatio" 0 "No Limitation" ;
VAL_TABLE_ LED_State_Copy_1 3 "Description for the value '0x3'" 2 "Off" 1 "On" 0 "Off" ;
VAL_TABLE_ LED_colour_Secondary_colour_Copy 9 "Yellow / Green  " 8 "Amber / Orange" 7 "White / Light blue " 6 "Magneta" 5 "Cyan" 4 "Yellow" 3 "Blue" 2 "Green" 1 "Red" 0 "Off" ;
VAL_TABLE_ isolation_mesmt_req_Copy_1 3 "Description for the value '0x3'" 2 "reserved" 1 "requested" 0 "Not_requested" ;
VAL_TABLE_ isolate_mesmt_status_Copy_1 3 "SNA" 2 "Error" 1 "Active" 0 "Not active" ;
VAL_TABLE_ inlet_motor_status_Copy_1 7 "SNA" 6 "Error" 5 "Reserved3" 4 "Reserved2" 3 "Reserved1" 2 "Moving" 1 "Locked" 0 "Unlocked" ;
VAL_TABLE_ Hw_varient_Copy_1 3 "SNA" 2 "reserved" 1 "Combo1 inlet" 0 "Combo2 " ;
VAL_TABLE_ HS_req_Copy_1 3 "SNA" 2 "Reserved" 1 "Enable" 0 "Disable" ;
VAL_TABLE_ high_side_diag_Copy_1 7 "SNA" 6 "Error" 5 "Short Btw pins" 4 "Inverse Currrent" 3 "Open Load" 2 "Short to Batt" 1 "Short to GND" 0 "Ok" ;
VAL_TABLE_ Forced_Gear_Engagement_Torque_Co 1 "TCU imposing min torque reqt" 0 "TCU not imposing min torque reqt" ;
VAL_TABLE_ EVSE_resp_code_Copy_1 26 "FAILED_CERTIFICATE_REVOKED" 25 "FAILED_CERTIFICATE_NOT_ALLOW_e" 24 "FAILED_CONTACTOR_ERROR" 22 "FAILED_WRNG_ENRGY_TRNSFER_TYPE" 21 "FAILED_NO_CHARGE_SERVICE_SELECt" 20 "FAILED_MTRING_SIGNTURE_NOT_VALID" 19 "FAILED_CHARGING_PROFILE_INVALID" 18 "FAILED_TARIFF_SELECTION_INVALID" 17 "FAILED_POWER_DELIVERY_NOT_APPLy" 16 "FAILED_WRONG_CHARGE_PARAMETER" 15 "FAILED_CONTRACT_CANCELED" 14 "FAILED_CHALLENGE_INVALID" 13 "FAILED_CERT_CHAIN_ERROR" 12 "FAILED_NO_CERTIFICATE_AVAILABLE" 11 "FAILED_SIGNATURE_ERROR" 10 "FAILED_CERTIFICATE_EXPIRED" 9 "FAILED_PAYMENT_SELECTION_INVALID" 8 "FAILED_SERVICE_SELECTION_INVALID" 7 "FAILED_UNKNOWN_SESSION" 6 "FAILED_SERVICE_IDINVALID" 5 "FAILED_SEQUENCE_ERROR" 4 "FAILED" 3 "OK_CERTIFICATE_EXPIRES_SOON" 2 "OK_OLD_SESSION_JOINED" 1 "OK_NEW_SESSION_ESTABLISHED" 0 "OK" ;
VAL_TABLE_ EVSE_Process_Copy_1 1 "ongoing" 0 "Finished" ;
VAL_TABLE_ EVSE_notification_Copy_1 2 "Re_Negotation" 1 "Stop Charging" 0 "None" ;
VAL_TABLE_ EVSE_isoltae_status_Copy_1 4 "No_Imd" 3 "Fault" 2 "Warning" 1 "Valid" 0 "Invalid" ;
VAL_TABLE_ energy_trans_mode_Copy_1 32 "Description for the value '0x18'" 16 "Energy_transfermode_combo_core" 8 "Energy_transfermode_DC_extend" 4 "Energy_transfermode_DCcore" 2 "Energy_transfermode_AC_3P" 1 "Energy_transfermode_AC_1P" 0 "Energy_transfermode_none" ;
VAL_TABLE_ energy_mode_Copy_1 15 "undefined" 5 "DC_unique" 4 "DC_combo_core" 3 "DC_extended" 2 "DC_core" 1 "AC_three_phase_core" 0 "Ac_single_phse_core" ;
VAL_TABLE_ E2E_state_charge_vehicle_Copy_1 32 "NoDATA_OK" 5 "Valid_NND" 3 "Valid_Error" 2 "Valid_SEQ" 1 "Valid_REP" 0 "Valid_Ok" ;
VAL_TABLE_ e2e_state_Copy_1 255 "Hard_run_time_error" 119 "Soft_run_time_error" 69 "Invalid_NND" 67 "Invalid_Error" 66 "Invalid_SEQ" 65 "Invalid_REP" 64 "Invalid_Ok" 53 "Init_NND" 51 "Init_error" 50 "Init_SEQ" 49 "Init_REP" 48 "Init_Ok" 37 "No_Data_NND" 35 "No_data_error" 34 "No_data_SEQ" 33 "No_data_REP" 32 "No_data_ok" 5 "valid NND" 3 "valid Error" 2 "valid SEQ" 1 "valid REP" 0 "valid ok" ;
VAL_TABLE_ Down_Shift_In_progress_Copy_1 1 "High gear Shift is in progress" 0 "High Shift is not in progress" ;
VAL_TABLE_ Down_Shift_failed_Copy_1 1 "shift to low gear failed" 0 "shift to Low gear Successful" ;
VAL_TABLE_ Door_Enable_Copy_1 2 "Not available" 1 "Error" 0 "Enabled" ;
VAL_TABLE_ DM13_suspend_signal_Copy_1 15 "not available" 14 "ResumingNormalpattern" 3 "Temporarysuspensionofsomemsg" 2 "Temporarysuspensionofallmsg" 1 "Indefinitesuspensionofsomemsg" 0 "Indefinitesuspensionofallmsg" ;
VAL_TABLE_ DM13_hold_signal_Copy_1 15 "Not available" 1 "Devices whose broadcast state" 0 "All Devices" ;
VAL_TABLE_ DilongDCDC_Faults_Copy_1 256 "Communication fault" 128 "Internal fault" 64 "Output short circuit protection" 32 "Input under voltage" 16 "Input over voltage" 8 "Output under voltage" 4 "Output over voltage" 2 "Output over current" 1 "Over temperature shutdown" ;
VAL_TABLE_ dept_Copy_1 0 "SNA" ;
VAL_TABLE_ DCDC_control_Copy_1 15 "Error Indicator" 14 "Not availble" 13 "Error state" 12 "Shutting down" 2 "Current control" 1 "Voltage control" 0 "Standby" ;
VAL_TABLE_ D_OBC_Mode_Copy_1 1 "Heating" 0 "Battery" ;
VAL_TABLE_ D_OBC_Charging_status_flag_Copy_ 16 "0 com normal 1 com timeout" 8 "0 start state 1 off" 4 "0 normal 1 input volt error" 2 "0 normal 1 charg temp too high" 1 "0 normal 1 HW failure" ;
VAL_TABLE_ D_OBC_Charging_state_Copy_1 2 "Charging complete" 1 "Bat prote,charger turn off op" 0 "The charger starts charging " ;
VAL_TABLE_ D_OBC_Charging_boot_status_Copy_ 32 "0 normal 1 alarm" 16 "0 normal 1 alarm" 8 "0 normal 1 alarm" 4 "2 fault 3 no electic lock" 2 "0 unlock 1 lock" 1 "0 disconnect 1 HW close" ;
VAL_TABLE_ D_DCDC_Switch_Control_Copy_1 1 "Shutdown" 0 "Power on" ;
VAL_TABLE_ D_DCDC_status_Copy_1 1 "Stop" 0 "Work" ;
VAL_TABLE_ D_DCDC_Fault_list_Copy_1 32768 "Reserve" 16384 "Reserve" 8192 "Reserve" 4096 "Reserve" 2048 "Reserve" 1024 "Reserve" 512 "Reserve" 256 "Communication fault alarm" 128 "Internal fault alarm " 64 "Output shortcircuit protection " 32 "Input under voltage alarm " 16 "Input over-voltage alarm" 8 "Output undervoltage alarm" 4 "Output over-voltage alarm" 2 "Output over-current alarm" 1 "Over temperature shutdown" ;
VAL_TABLE_ Current_Transmission_Mode_Copy_1 3 "Forward Low" 2 "Forward Automatic" 1 "Reverse" 0 "Neutral" ;
VAL_TABLE_ CTR_FKTN_PRTNT_DRV_Copy_1 -2147483648 "Signal invalid" ;
VAL_TABLE_ CTR_BS_PRTNT_DRV_Copy_1 65535 "Signal Invalid" ;
VAL_TABLE_ Cp_wakeup_Copy_1 3 "sna" 2 "error" 1 "wakeup detected" 0 "wakeup not detected" ;
VAL_TABLE_ CP_chrage_mode_req_Copy_1 7 "SNA" 6 "Error" 5 "Reserved 3" 4 "Reserved 2" 3 "Reserved 1" 2 "Mode D" 1 "Mode C" 0 "Mode B" ;
VAL_TABLE_ Controlmode_Copy_1 3 "take no action" 2 "reserved" 1 "Current control" 0 "Voltage control " ;
VAL_TABLE_ Contactor_req_Copy_1 3 "Description for the value '0x3'" 2 "force_open" 1 "close" 0 "open" ;
VAL_TABLE_ connection_status_Copy_1 3 "Description for the value '0x3'" 2 "error" 1 "connected" 0 "not connected" ;
VAL_TABLE_ CommandEnableDCC2_Copy_1 3 "Take no action" 2 "Reserved" 1 "Enable" 0 "Standby" ;
VAL_TABLE_ Clamp_15_active_Copy_1 1 "Clamp_15_noactive" 0 "Clamp15_Active" ;
VAL_TABLE_ chg_unit_state_Copy_1 7 "SNA" 6 "EVSE State F" 5 "EVSE State E" 4 "EVSE State D" 3 "EVSE State C" 2 "EVSE State B2" 1 "EVSE state B1" 0 "EVSE state A" ;
VAL_TABLE_ chg_unit_mode_Copy_1 7 "sna" 6 "error" 5 "reserved" 4 "Charge Pantograph" 3 "Charging LIN" 2 "Charging Not allowed" 1 "Charge PWM" 0 "Charge V2G" ;
VAL_TABLE_ chg_selct_ack_Copy_1 3 "sna" 2 "error" 1 "secondary node" 0 "primary_node" ;
VAL_TABLE_ Charge_State_Copy_1 2 "Charging complete" 1 "Bat prtect charger turn off" 0 "Charger start charging" ;
VAL_TABLE_ Charge_Comm_Active_Copy_1 1 "Description for the value '0x1'" 0 "Charg_Comm_Active" ;
VAL_TABLE_ Charg_Lin_Active_Copy_1 1 "Charg_Lin_Non active" 0 "Charg_Lin_Active" ;
VAL_TABLE_ Broadcast_Copy_1 3 "dont care" 2 "reserved" 1 "start broadcast" 0 "Stop broadcast" ;
VAL_TABLE_ Brakes_Copy_1 3 "Not available" 2 "Error indicator" 1 "Fuel level sufficient" 0 "Fuel level not sufficient" ;
VAL_TABLE_ Boolean_Copy_1 1 "True" 0 "False" ;
VAL_TABLE_ appl_func_mode_req_Copy_1 2 "Reset" 1 "Charging mode" 0 "none" ;
VAL_TABLE_ appl_chg_mode_req_Copy_1 6 "Stop Charging" 5 "Renegotation" 4 "Start welding detection" 3 "Start power delivery" 2 "Precharge completed" 1 "Negotating Charging Parameters" 0 "None" ;
VAL_TABLE_ AMB_TEMP_Copy_1 127 "SNA" ;
VAL_TABLE_ Air_Pressure_Out_of_Range_Copy_1 1 "solenoids is out of range" 0 "solenoids is in normal range" ;
VAL_TABLE_ RTC_req 3 "SNA" 2 "reserved" 1 "requested" 0 "Not requested" ;
VAL_TABLE_ Motor_Req 7 "SNA" 6 "Reserved3" 5 "Reserved2" 4 "Reserved1" 3 "Measurement" 2 "Direction B" 1 "Directon A" 0 "Stop" ;
VAL_TABLE_ SNA 255 "SNA" ;
VAL_TABLE_ Motor_L_U 3 "SNA" 2 "Reserved" 1 "Unlock" 0 "Lock" ;
VAL_TABLE_ HS_req 3 "SNA" 2 "Reserved" 1 "Enable" 0 "Disable" ;
VAL_TABLE_ CP_chrage_mode_req 7 "SNA" 6 "Error" 5 "Reserved 3" 4 "Reserved 2" 3 "Reserved 1" 2 "Mode D" 1 "Mode C" 0 "Mode B" ;
VAL_TABLE_ VCCU_Charge_unit_request 3 "SNA" 2 "Enable ventilation" 1 "Enable" 0 "Disable" ;
VAL_TABLE_ energy_mode 15 "undefined" 5 "DC_unique" 4 "DC_combo_core" 3 "DC_extended" 2 "DC_core" 1 "AC_three_phase_core" 0 "Ac_single_phse_core" ;
VAL_TABLE_ VCVCCU_V2G_EVErrorCode 11 "No data" 10 "CHARGING_SYSTEM_INCOMPATIBILITY" 9 "RESERVED_C" 8 "RESERVED_B" 7 "RESERVED_A" 6 "CHARGING_VOLTAGE_OUT_OF_RANGE" 5 "FAILCHARGCURRENTDIFFERENTIAL" 4 "FAILED_EVRESSMALFUNCTION" 3 "FAILChargeCONNECT_LOCK_FAULT" 2 "FAILED_EVSHIFT_POSITION" 1 "FAILED_RESSTEMPERATURE_INHIBIT" 0 "NO_ERROR" ;
VAL_TABLE_ LIN_EV_Frequencies 255 "Not available" 2 "both 50 Hz_60 Hz" 1 "only 60 Hz" 0 "only 50 Hz" ;
VAL_TABLE_ Vehicle_renegotiate 3 "SNA" 2 "Error" 1 "Requested" 0 "Not_requested" ;
VAL_TABLE_ PWM_charge_mode_req 3 "Description for the value '0x3'" 2 "Error" 1 "PWM_charge_mode_request_D" 0 "PWM_charge_mode_request_C" ;
VAL_TABLE_ plug_lock_permission 3 "Description for the value '0x3'" 2 "Reserved" 1 "Allowed" 0 "Not_allowed" ;
VAL_TABLE_ isolate_mesmt_status 3 "SNA" 2 "Error" 1 "Active" 0 "Not active" ;
VAL_TABLE_ Vehicle_contactor_status 3 "SNA" 2 "Stuck" 1 "Close" 0 "Open" ;
VAL_TABLE_ Vehicle_charge_selection 3 "SNA" 2 "error" 1 "secondary node" 0 "Primary node" ;
VAL_TABLE_ Vehicle_charge_permission 3 "Stop" 2 "Emergency stop" 1 "allowed" 0 "Not allowed" ;
VAL_TABLE_ DM13_suspend_signal 15 "not available" 14 "ResumingNormalpattern" 3 "Temporarysuspensionofsomemsg" 2 "Temporarysuspensionofallmsg" 1 "Indefinitesuspensionofsomemsg" 0 "Indefinitesuspensionofallmsg" ;
VAL_TABLE_ DM13_hold_signal 15 "Not available" 1 "Devices whose broadcast state" 0 "All Devices" ;
VAL_TABLE_ Broadcast 3 "dont care" 2 "reserved" 1 "start broadcast" 0 "Stop broadcast" ;
VAL_TABLE_ VCVCCU_V2G_Core_StackError 16 "StackError_PBufToSmall" 15 "StackError_InvalidKeyPair" 14 "StackError_NvM" 13 "StackError_NegativeResponseCode" 12 "StackError_InvalidRxParameter" 11 "StackError_InvalidRxMessage" 10 "StackError_Crypto" 9 "StackError_XmlSecurity" 8 "StackError_Exi" 7 "StackError_IpBase" 6 "StackError_Timeout" 5 "Timeout_RequestNotAcknowledged" 4 "Timeout_RequestAcknowledged" 3 "StackError_InvalidTxParameter" 2 "StackError_TransportLayer" 1 "StackError_SLAC" 0 "StackError_NoError" ;
VAL_TABLE_ VCVCCU_V2G_Core_SDPSecurityTx 16 "SDPSecurity_None" 0 "SDPSecurity_Tls" ;
VAL_TABLE_ VCVCCU_V2G_Core_SAPSchemaID 4 "SAPSchemaIDs_None" 3 "NumOfSupportedSchemas" 2 "SAPSchemaIDs_DIN" 1 "SAPSchemaIDs_ISO_Ed2_CD" 0 "SAPSchemaIDs_ISO" ;
VAL_TABLE_ V2G_SAP_response_code 2 "FAILED_NO_NEGOTIATION" 1 "OKNEGOTIAMINOR_DEVIATION" 0 "OK_SUCCESSFUL_NEGOTIATION" ;
VAL_TABLE_ V2G_core_msg_status 50 "StopCommunicationSession_Failed" 49 "StopCommunicationSession_OK" 48 "MsgStatus_SessionStop_Failed" 47 "MsgStatus_SessionStop_OK" 46 "WeldingDetection_Failed" 45 "MsgStatus_WeldingDetection_OK" 44 "MsgStatus_CurrentDemand_Failed" 43 "MsgStatus_CurrentDemand_OK" 42 "MsgStatus_PreCharge_Failed" 41 "MsgStatus_PreCharge_OK" 40 "MsgStatus_CableCheck_Failed" 39 "MsgStatus_CableCheck_OK" 38 "MsgStatus_ChargingStatus_Failed" 37 "MsgStatus_ChargingStatus_OK" 36 "MsgStatus_MeteringReceipt_Failed" 35 "MsgStatus_MeteringReceipt_OK" 34 "MsgStatus_PowerDelivery_Failed" 33 "MsgStatus_PowerDelivery_OK" 32 "ChargeParameterDiscovery_Failed" 31 "ChargeParameterDiscovery_OK" 30 "MsgStatus_Authorization_Failed" 29 "MsgStatus_Authorization_OK" 28 "MsgStatus_PaymentDetails_Failed" 27 "PaymentDetails_OK" 26 "CertificateUpdate_Failed" 25 "CertificateUpdate_OK" 24 "CertificateInstallation_Failed" 23 "CertificateInstallation_OK" 22 "MsgStatus_ReadProvCert_Failed" 21 "MsgStatus_ReadProvCert_OK" 20 "WrapperReadRootCerts_Failed" 19 "MsgStatus_ReadRootCerts_OK" 18 "PaymentServiceSelection_Failed" 17 "PaymentServiceSelection_OK" 16 "MsgStatus_ServiceDetail_Failed" 15 "MsgStatus_ServiceDetail_OK" 14 "ReadContrCertChain_Failed" 13 "ReadContrCertChain_OK" 12 "ServiceDiscovery_Failed" 11 "MsgStatus_ServiceDiscovery_OK" 10 "MsgStatus_SessionSetup_Failed" 9 "MsgStatus_SessionSetup_OK" 8 "SupportedAppProtocol_Failed" 7 "SupportedAppProtocol_OK" 6 "MsgStatus_TransportLayer_Failed" 5 "MsgStatus_TransportLayer_OK" 4 "SECCDiscoveryProtocol_Failed" 3 "SECCDiscoveryProtocol_OK" 2 "MsgStatus_SLAC_Failed" 1 "MsgStatus_SLAC_OK" 0 "MsgStatus_None" ;
VAL_TABLE_ V2G_core_msg_state 5 "msgstate_timeout" 4 "msgstate_response_received" 3 "msgstate_transmission_confirmed" 2 "msgstate_request_sent" 1 "msgstate_streaming_request" 0 "Msg_state_waitfor next_request" ;
VAL_TABLE_ state_mchine_status 32 "PowerDemand" 31 "InitialAlignmentCheck" 30 "Pairing" 29 "FinePositioning" 28 "FinePositioningSetup" 27 "Error_Stopped" 26 "Error_WaitForRetry" 25 "Finished" 24 "StopCommunicationSession" 23 "SessionStop" 22 "WeldingDetection" 21 "MeteringReceipt" 20 "CurrentDemand" 19 "ChargingStatus" 18 "PowerDelivery" 17 "PreCharge" 16 "CableCheck" 15 "ChargeParameterDiscovery" 14 "Authorization" 13 "PaymentDetails" 12 "CertificateUpdate" 11 "CertificateInstallation" 10 "PaymentServiceSelection" 9 "ServiceDetails" 8 "ServiceDiscovery" 7 "SessionSetup" 6 "SupportedAppProtocol" 5 "TLConnection" 4 "SECCDiscoveryProtocol" 3 "WaitForIP" 2 "SLAC" 1 "Initialized" 0 "None" ;
VAL_TABLE_ state_msg_state 3 "SMMS_WaitingForApplication" 2 "SMMS_ProcessingResponse" 1 "SMMS_WaitingForResponse" 0 "SMMS_PreparingRequest" ;
VAL_TABLE_ StateM_machine_error 20 "SMER_InvalidControlPilotState" 19 "PaymtServiceSelect_ServMismatch" 18 "InitialAlignmentCheckOngoinTimer" 17 "SMER_Timer_PairingOngoingTimer" 16 "Timer_FinePositionOngoingTimer" 15 "SMER_StackError" 14 "NoContractInstallatiServiceAvbl" 13 "NoContractCertificateServiceAvlb" 12 "NoSharedPaymentOption" 11 "InvalidEnergyTransferMode" 10 "Discovery_NoSharedSecurityOption" 9 "InitializatContrctSelectiFailed" 8 "SMER_Timer_PreChargeOngoingTimer" 7 "Timer_CableCheckOngoingTimer" 6 "ChargeParmtrDiscveryOngoingTimer" 5 "Timer_AuthorizationOngoingTimer" 4 "SMETimer_ReadyToChargeTimer" 3 "Timer_CommunicationSetupTimer" 2 "SMER_Timer_SequencePerformTimer" 1 "SMER_Timer_IPAddressWaitTimer" 0 "SMER_NoError" ;
VAL_TABLE_ energy_trans_mode 32 "Description for the value '0x18'" 16 "Energy_transfermode_combo_core" 8 "Energy_transfermode_DC_extend" 4 "Energy_transfermode_DCcore" 2 "Energy_transfermode_AC_3P" 1 "Energy_transfermode_AC_1P" 0 "Energy_transfermode_none" ;
VAL_TABLE_ appl_func_mode_req 2 "Reset" 1 "Charging mode" 0 "none" ;
VAL_TABLE_ appl_chg_mode_req 6 "Stop Charging" 5 "Renegotation" 4 "Start welding detection" 3 "Start power delivery" 2 "Precharge completed" 1 "Negotating Charging Parameters" 0 "None" ;
VAL_TABLE_ dept 0 "SNA" ;
VAL_TABLE_ Pre_HVAC 3 "SNA" 2 "no_warm water , cool & venti" 1 "hot water and heating" 0 "only warm water , ventilation" ;
VAL_TABLE_ Precond_desire 255 "SNA" 1 "Yes" 0 "No" ;
VAL_TABLE_ AMB_TEMP 127 "SNA" ;
VAL_TABLE_ EVSE_resp_code 26 "FAILED_CERTIFICATE_REVOKED" 25 "FAILED_CERTIFICATE_NOT_ALLOW_e" 24 "FAILED_CONTACTOR_ERROR" 22 "FAILED_WRNG_ENRGY_TRNSFER_TYPE" 21 "FAILED_NO_CHARGE_SERVICE_SELECt" 20 "FAILED_MTRING_SIGNTURE_NOT_VALID" 19 "FAILED_CHARGING_PROFILE_INVALID" 18 "FAILED_TARIFF_SELECTION_INVALID" 17 "FAILED_POWER_DELIVERY_NOT_APPLy" 16 "FAILED_WRONG_CHARGE_PARAMETER" 15 "FAILED_CONTRACT_CANCELED" 14 "FAILED_CHALLENGE_INVALID" 13 "FAILED_CERT_CHAIN_ERROR" 12 "FAILED_NO_CERTIFICATE_AVAILABLE" 11 "FAILED_SIGNATURE_ERROR" 10 "FAILED_CERTIFICATE_EXPIRED" 9 "FAILED_PAYMENT_SELECTION_INVALID" 8 "FAILED_SERVICE_SELECTION_INVALID" 7 "FAILED_UNKNOWN_SESSION" 6 "FAILED_SERVICE_IDINVALID" 5 "FAILED_SEQUENCE_ERROR" 4 "FAILED" 3 "OK_CERTIFICATE_EXPIRES_SOON" 2 "OK_OLD_SESSION_JOINED" 1 "OK_NEW_SESSION_ESTABLISHED" 0 "OK" ;
VAL_TABLE_ New_Value_Table_151 11 "reserved c" 10 "reserved B" 9 "Reserved A" 8 "Reserved 9" 7 "Reserved 8" 6 "EVSE Malfunction" 5 "EVSE Emergency Shutdwon" 4 "EVSE Isolation Monitoring Active" 3 "EVSE Utility Interrupt Event" 2 "EVSE Shutdown" 1 "EVSE Ready" 0 "EVSE_Not_Ready" ;
VAL_TABLE_ EVSE_Process 1 "ongoing" 0 "Finished" ;
VAL_TABLE_ EVSE_notification 2 "Re_Negotation" 1 "Stop Charging" 0 "None" ;
VAL_TABLE_ EVSE_isoltae_status 4 "No_Imd" 3 "Fault" 2 "Warning" 1 "Valid" 0 "Invalid" ;
VAL_TABLE_ Tolerance_unit 9 "WH" 8 "W_S" 7 "W" 6 "VA" 5 "V" 4 "HA" 3 "A" 2 "S" 1 "M" 0 "H" ;
VAL_TABLE_ Boolean 1 "True" 0 "False" ;
VAL_TABLE_ timer_status 3 "SNA" 2 "Elapsed" 1 "Running" 0 "Stopped" ;
VAL_TABLE_ PTC2 7 "SNA" 6 "reserved3" 5 "reserved2" 4 "reserved1" 3 "Open Load" 2 "Short to Batt" 1 "Short to GND" 0 "Ok" ;
VAL_TABLE_ PTC_diag 7 "SNA" 6 "Error" 5 "Reserved 1" 4 "Out of range" 3 "Open Load" 2 "Short to Batt" 1 "Short to GND" 0 "Ok" ;
VAL_TABLE_ high_side_diag 7 "SNA" 6 "Error" 5 "Short Btw pins" 4 "Inverse Currrent" 3 "Open Load" 2 "Short to Batt" 1 "Short to GND" 0 "Ok" ;
VAL_TABLE_ LIN_Freq 255 "Not Available" 1 "60 Hz" 0 "50 Hz" ;
VAL_TABLE_ Pos_Feedback 7 "SNA" 6 "Reseved3" 5 "Reserved2" 4 "Reserved1" 3 "Open Load" 2 "Short to Batt" 1 "Short to GND" 0 "Ok" ;
VAL_TABLE_ Plug_present_self_diag 7 "SNA" 6 "Reseved3" 5 "Reserved2" 4 "Reserved1" 3 "Open Load" 2 "Short to Batt" 1 "Short to GND" 0 "Ok" ;
VAL_TABLE_ Resistance 7 "SNA" 6 "Error" 5 "S3_480_ohm" 4 "S3_150_ohm" 3 "1500 Ohm" 2 "680 ohm" 1 "220 Ohm" 0 "100 Ohm" ;
VAL_TABLE_ Self_Diag_Status 7 "SNA" 6 "Error" 5 "Short Btw pins" 4 "Supply Voltage Failure'" 3 "Open Load" 2 "Short to Batt" 1 "Short to GND" 0 "Ok" ;
VAL_TABLE_ Lock_motor 7 "SNA" 6 "Error" 5 "Reserved2" 4 "Resserved1" 3 "Measurement" 2 "Direction B" 1 "Direction A" 0 "Idle" ;
VAL_TABLE_ inlet_motor_status 7 "SNA" 6 "Error" 5 "Reserved3" 4 "Reserved2" 3 "Reserved1" 2 "Moving" 1 "Locked" 0 "Unlocked" ;
VAL_TABLE_ Hw_varient 3 "SNA" 2 "reserved" 1 "Combo1 inlet" 0 "Combo2 " ;
VAL_TABLE_ connection_status 3 "Description for the value '0x3'" 2 "error" 1 "connected" 0 "not connected" ;
VAL_TABLE_ Sw_Status 3 "sna" 2 "Error" 1 "Pressed" 0 "Not Pressed" ;
VAL_TABLE_ Cp_wakeup 3 "sna" 2 "error" 1 "wakeup detected" 0 "wakeup not detected" ;
VAL_TABLE_ chg_unit_state 7 "SNA" 6 "EVSE State F" 5 "EVSE State E" 4 "EVSE State D" 3 "EVSE State C" 2 "EVSE State B2" 1 "EVSE state B1" 0 "EVSE state A" ;
VAL_TABLE_ chg_unit_mode 7 "sna" 6 "error" 5 "reserved" 4 "Charge Pantograph" 3 "Charging LIN" 2 "Charging Not allowed" 1 "Charge PWM" 0 "Charge V2G" ;
VAL_TABLE_ e2e_state 255 "Hard_run_time_error" 119 "Soft_run_time_error" 69 "Invalid_NND" 67 "Invalid_Error" 66 "Invalid_SEQ" 65 "Invalid_REP" 64 "Invalid_Ok" 53 "Init_NND" 51 "Init_error" 50 "Init_SEQ" 49 "Init_REP" 48 "Init_Ok" 37 "No_Data_NND" 35 "No_data_error" 34 "No_data_SEQ" 33 "No_data_REP" 32 "No_data_ok" 5 "valid NND" 3 "valid Error" 2 "valid SEQ" 1 "valid REP" 0 "valid ok" ;
VAL_TABLE_ chg_selct_ack 3 "sna" 2 "error" 1 "secondary node" 0 "primary_node" ;
VAL_TABLE_ vehicle_chg_status 3 "Description for the value '0x3'" 2 "reserved" 1 "start_charging" 0 "stop_charging" ;
VAL_TABLE_ Contactor_req 3 "Description for the value '0x3'" 2 "force_open" 1 "close" 0 "open" ;
VAL_TABLE_ isolation_mesmt_req 3 "Description for the value '0x3'" 2 "reserved" 1 "requested" 0 "Not_requested" ;
VAL_TABLE_ VCCU_mobile_status 3 "SNA" 2 "Vehicle immobile Fault" 1 "Vehicle Imobile" 0 "Vehicle mobile" ;
VAL_TABLE_ Wakeup_Rsn 255 "Snaa" 5 "Clamp15" 4 "Switch" 3 "RTC" 2 "Plug Present" 1 "Control_pilot" 0 "Network" ;
VAL_TABLE_ VCCU_Diag_Active 1 "Diag_no_active" 0 "Diag_active" ;
VAL_TABLE_ Clamp_15_active 1 "Clamp_15_noactive" 0 "Clamp15_Active" ;
VAL_TABLE_ Charg_Lin_Active 1 "Charg_Lin_Non active" 0 "Charg_Lin_Active" ;
VAL_TABLE_ Charge_Comm_Active 1 "Description for the value '0x1'" 0 "Charg_Comm_Active" ;
VAL_TABLE_ E2E_state_charge_vehicle 32 "NoDATA_OK" 5 "Valid_NND" 3 "Valid_Error" 2 "Valid_SEQ" 1 "Valid_REP" 0 "Valid_Ok" ;
VAL_TABLE_ Nm01 1 "Charg_Comm_active" 0 "Charg_Comm_not _active" ;
VAL_TABLE_ Limit_mode 15 "Error indicator" 14 "Not Available" 11 "External output voltage limit" 10 "Internal output voltage limit" 9 "External current limitation" 8 "High side current limitation" 7 "High side power limitation" 6 "coolant temp limitation" 5 "Power stage temp limitation" 4 "High input voltage limitation" 3 "low input voltage limitation" 2 "Event limitation" 1 "Maximum current limitatio" 0 "No Limitation" ;
VAL_TABLE_ DCDC_control 15 "Error Indicator" 14 "Not availble" 13 "Error state" 12 "Shutting down" 2 "Current control" 1 "Voltage control" 0 "Standby" ;
VAL_TABLE_ Ramp_move 3 "Not availble" 2 "error" 1 "Ramp being move" 0 "ramp being not move" ;
VAL_TABLE_ Ramp_enable 3 "not available" 2 "error" 1 "enable" 0 "disable" ;
VAL_TABLE_ Retract_status 3 "Not avalible" 2 "Error" 1 "Ramp Extracted" 0 "Ramp retracted" ;
VAL_TABLE_ Door_Enable 2 "Not available" 1 "Error" 0 "Enabled" ;
VAL_TABLE_ Openstatusofdoor1 3 "Not availble" 2 "Error" 1 "Open" 0 "Closed" ;
VAL_TABLE_ lockstatusofdoor1 3 "Not Available" 2 "Error" 1 "lock" 0 "Unlock" ;
VAL_TABLE_ Brakes 3 "Not available" 2 "Error indicator" 1 "Fuel level sufficient" 0 "Fuel level not sufficient" ;
VAL_TABLE_ Modes 1 "Battery mode" 0 "Heating mode" ;
VAL_TABLE_ Charge_State 2 "Charging complete" 1 "Bat prtect charger turn off" 0 "Charger start charging" ;
VAL_TABLE_ DilongDCDC_Faults 256 "Communication fault" 128 "Internal fault" 64 "Output short circuit protection" 32 "Input under voltage" 16 "Input over voltage" 8 "Output under voltage" 4 "Output over voltage" 2 "Output over current" 1 "Over temperature shutdown" ;
VAL_TABLE_ Controlmode 3 "take no action" 2 "reserved" 1 "Current control" 0 "Voltage control " ;
VAL_TABLE_ CommandEnableDCC2 3 "Take no action" 2 "Reserved" 1 "Enable" 0 "Standby" ;
VAL_TABLE_ VCCU_8bit_Eroor 255 "SNA" 254 "Error" ;
VAL_TABLE_ VCCU_16bit_error 65535 "SNA" 65534 "Error" ;
VAL_TABLE_ ST_MEASMT_ISL 3 "Signal Invalid" 2 "Iso measurement  running" 1 "Iso measurement not running" ;
VAL_TABLE_ ST_SER_DSCO_PLG 3 "Description for the value '0x2'" 2 "Service Disconnector Connected" 1 "Service Disconnector Open" ;
VAL_TABLE_ CTR_FKTN_PRTNT_DRV -2147483648 "Signal invalid" ;
VAL_TABLE_ CTR_BS_PRTNT_DRV 65535 "Signal Invalid" ;
VAL_TABLE_ RQ_CHGRDI 2 "Char with depa time and cond" 1 "Plug & Charge (default)" 0 "no charging" ;
VAL_TABLE_ ST_AC_CHGNG_EPRG 2 "Signal Invalid" 1 "Activated" 0 "Deactivated" ;
VAL_TABLE_ ST_ERR_ISL_EXTN_BN_HV_VT 3 "Signal Invalid" 2 "Active" 1 "Not Active" 0 "No statement possible" ;
VAL_TABLE_ Forced_Gear_Engagement_Torque 1 "TCU imposing min torque reqt" 0 "TCU not imposing min torque reqt" ;
VAL_TABLE_ Air_Pressure_Out_of_Range 1 "solenoids is out of range" 0 "solenoids is in normal range" ;
VAL_TABLE_ Shift_Disabled 1 "Gear shift disabled" 0 "Gear shift not disabled" ;
VAL_TABLE_ Slow_Upshift 1 "Shift require more amnt of time" 0 "Shift in a normal amount of time" ;
VAL_TABLE_ Down_Shift_failed 1 "shift to low gear failed" 0 "shift to Low gear Successful" ;
VAL_TABLE_ Upshift_Failed 1 "shift to High gear failed" 0 "shift to High gear successful" ;
VAL_TABLE_ Down_Shift_In_progress 1 "High gear Shift is in progress" 0 "High Shift is not in progress" ;
VAL_TABLE_ UpShift_In_Progress 1 "High gear Shift is in progress" 0 "High Shift is not in progress" ;
VAL_TABLE_ Selected_Gear 3 "Shift in Progress" 2 "High" 1 "Low" 0 "Neutral" ;
VAL_TABLE_ Current_Transmission_Mode 3 "Forward Low" 2 "Forward Automatic" 1 "Reverse" 0 "Neutral" ;
VAL_TABLE_ TCU_System_type 0 "Unknown" ;
VAL_TABLE_ MCU_System_Type 15 "Undefined" 14 "Undefined" 13 "Undefined" 12 "Undefined" 11 "Undefined" 10 "Undefined" 9 "Undefined" 8 "Undefined" 7 "EM-PMI318B-T360-465V" 6 "Undefined" 5 "EM-PMI318B-T520E-465V" 4 "EM-PMI318B-T440E-255V" 3 "EM-PMI318-T400-255V" 2 "EM-PMI318-T360-425V" 1 "EM-PMI318-T350-255V" 0 "UnKnown" ;
VAL_TABLE_ LED_State 3 "Description for the value '0x3'" 2 "Off" 1 "On" 0 "Off" ;
VAL_TABLE_ LED_colour_Secondary_colour 9 "Yellow / Green  " 8 "Amber / Orange" 7 "White / Light blue " 6 "Magneta" 5 "Cyan" 4 "Yellow" 3 "Blue" 2 "Green" 1 "Red" 0 "Off" ;
VAL_TABLE_ PKP_number 3 "Key 4" 2 "Key 3" 1 "Key 2" 0 "Key 1" ;
VAL_TABLE_ D_OBC_Charging_boot_status 32 "0 normal 1 alarm" 16 "0 normal 1 alarm" 8 "0 normal 1 alarm" 4 "2 fault 3 no electic lock" 2 "0 unlock 1 lock" 1 "0 disconnect 1 HW close" ;
VAL_TABLE_ D_OBC_Charging_status_flag 16 "0 com normal 1 com timeout" 8 "0 start state 1 off" 4 "0 normal 1 input volt error" 2 "0 normal 1 charg temp too high" 1 "0 normal 1 HW failure" ;
VAL_TABLE_ D_OBC_Mode 1 "Heating" 0 "Battery" ;
VAL_TABLE_ D_OBC_Charging_state 2 "Charging complete" 1 "Bat prote,charger turn off op" 0 "The charger starts charging " ;
VAL_TABLE_ D_DCDC_status 1 "Stop" 0 "Work" ;
VAL_TABLE_ D_DCDC_Fault_list 32768 "Reserve" 16384 "Reserve" 8192 "Reserve" 4096 "Reserve" 2048 "Reserve" 1024 "Reserve" 512 "Reserve" 256 "Communication fault alarm" 128 "Internal fault alarm " 64 "Output shortcircuit protection " 32 "Input under voltage alarm " 16 "Input over-voltage alarm" 8 "Output undervoltage alarm" 4 "Output over-voltage alarm" 2 "Output over-current alarm" 1 "Over temperature shutdown" ;
VAL_TABLE_ D_DCDC_Switch_Control 1 "Shutdown" 0 "Power on" ;

BO_ 3221225472 VECTOR__INDEPENDENT_SIG_MSG: 0 Vector__XXX
 SG_ MCU_rotor_over_temp : 0|2@1+ (1,0) [0|3] "" Vector__XXX
 SG_ TCU_cmd_MSG_1_watchdog_timeout : 0|2@1+ (1,0) [0|3] "" Vector__XXX
 SG_ CompSpd_V2_LIN_status : 0|16@1+ (1,0) [0|65535] "" Vector__XXX
 SG_ SWPartNumber : 0|16@1+ (1,0) [0|65535] "" Vector__XXX
 SG_ DEMO_mode : 0|8@1+ (1,0) [0|255] "" Vector__XXX
 SG_ VCU_DummySig_10 : 0|8@1+ (1,0) [0|255] "percentage" Vector__XXX
 SG_ VCU_Dummy10 : 0|8@1+ (1,0) [0|255] "Integer" Vector__XXX
 SG_ Charging_pilot_alarm : 0|8@1+ (1,0) [0|255] "" Vector__XXX
 SG_ VCVCCU_V2G_EVSEMaxVltgLimitFlag : 0|2@1+ (1,0) [0|3] "" Vector__XXX
 SG_ DIAG_RESP_VCVCCU : 0|64@1+ (1,0) [0|1.84467440737096E+019] "" Vector__XXX
 SG_ V2G_EVMaximumcurrentlimit_Flag : 0|2@1+ (1,0) [0|3] "" Vector__XXX
 SG_ Reserved_2 : 0|8@1+ (1,0) [0|255] "" Vector__XXX
 SG_ Reserved_2 : 0|8@1+ (1,0) [0|255] "" Vector__XXX
 SG_ Status_Bit_4 : 0|8@1+ (1,0) [0|255] "" Vector__XXX
 SG_ Status_Bit_3 : 0|8@1+ (1,0) [0|255] "" Vector__XXX
 SG_ Status_Bit_2 : 0|8@1+ (1,0) [0|255] "" Vector__XXX
 SG_ Status_Bit_1 : 0|8@1+ (1,0) [0|255] "" Vector__XXX
 SG_ Set_speed_relative_4 : 0|8@1+ (0.5,0) [0|100] "%" Vector__XXX
 SG_ Set_speed_absolute_4 : 0|16@1+ (1,0) [0|3200] "rpm" Vector__XXX
 SG_ Reserved_3 : 0|8@1+ (1,0) [0|255] "" Vector__XXX
 SG_ Set_speed_relative_3 : 0|8@1+ (0.5,0) [0|100] "%" Vector__XXX
 SG_ Set_speed_absolute_3 : 0|16@1+ (1,0) [0|3200] "rpm" Vector__XXX
 SG_ Reserved_3 : 0|8@1+ (1,0) [0|255] "" Vector__XXX
 SG_ Set_speed_relative_2 : 0|8@1+ (0.5,0) [0|100] "%" Vector__XXX
 SG_ Set_speed_absolute_2 : 0|16@1+ (1,0) [0|3200] "rpm" Vector__XXX
 SG_ Reserved_3 : 0|8@1+ (1,0) [0|255] "" Vector__XXX
 SG_ Reserved_3 : 0|8@1+ (1,0) [0|255] "" Vector__XXX
 SG_ Set_speed_relative_1 : 0|8@1+ (0.5,0) [0|100] "%" Vector__XXX
 SG_ Set_speed_absolute_1 : 0|16@1+ (1,0) [0|3200] "rpm" Vector__XXX
 SG_ Reserved_7 : 0|8@1+ (1,0) [0|255] "" Vector__XXX
 SG_ D_OBC_Charging_alarm : 0|8@1+ (1,0) [0|255] "" Vector__XXX
 SG_ LIN_SeNomVoltageL1N : 0|8@1+ (1,0) [0|255] "" Vector__XXX
 SG_ V2G_EVSEPresentCurrent_Values : 0|8@1- (1,0) [-128|127] "" Vector__XXX
 SG_ V2G_EVSEMinCurrent_Multiplier : 0|8@1- (1,0) [-128|127] "" Vector__XXX
 SG_ V2G_EVMaxcurrentlimit_Unitflag : 0|8@1- (1,0) [-128|127] "" Vector__XXX
 SG_ V2G_MaxCurrentLimit_Multiplier : 0|16@1+ (1,0) [0|255] "" Vector__XXX
 SG_ E2E_State_ChargeFromVehicle : 0|4@1+ (1,0) [0|15] "" Vector__XXX
 SG_ VCVCCU_Vehcle_ChrgeSelectnAck : 0|2@1+ (1,0) [0|3] "" Vector__XXX
 SG_ Reserved_bit_7 : 0|1@1+ (1,0) [0|0] "" Vector__XXX
 SG_ Reserved_bit_6 : 0|1@1+ (1,0) [0|0] "" Vector__XXX
 SG_ Reserved_bit_5 : 0|1@1+ (1,0) [0|0] "" Vector__XXX
 SG_ Reserved_bit_3 : 0|1@1+ (1,0) [0|0] "" Vector__XXX
 SG_ Reserved_bit_2 : 0|1@1+ (1,0) [0|0] "" Vector__XXX
 SG_ Reserved_bit_1 : 0|1@1+ (1,0) [0|0] "" Vector__XXX
 SG_ Reserved_5 : 0|8@1+ (1,0) [0|255] "" Vector__XXX
 SG_ Reserved_4 : 0|8@1+ (1,0) [0|255] "" Vector__XXX
 SG_ Reserved_1 : 0|8@1+ (1,0) [0|255] "" Vector__XXX
 SG_ Reserved_0 : 0|8@1+ (1,0) [0|255] "" Vector__XXX
 SG_ Reserved_bit_7 : 0|1@1+ (1,0) [0|0] "" Vector__XXX
 SG_ Reserved_bit_6 : 0|1@1+ (1,0) [0|0] "" Vector__XXX
 SG_ Reserved_bit_5 : 0|1@1+ (1,0) [0|0] "" Vector__XXX
 SG_ Reserved_bit_4 : 0|1@1+ (1,0) [0|0] "" Vector__XXX
 SG_ Reserved_bit_7 : 0|1@1+ (1,0) [0|0] "" Vector__XXX
 SG_ Reserved_bit_6 : 0|1@1+ (1,0) [0|0] "" Vector__XXX
 SG_ Reserved_bit_3 : 0|1@1+ (1,0) [0|0] "" Vector__XXX
 SG_ Reserved_bit_2 : 0|1@1+ (1,0) [0|0] "" Vector__XXX
 SG_ Reserved_bit_1 : 0|1@1+ (1,0) [0|0] "" Vector__XXX
 SG_ Reserved_3 : 0|8@1+ (1,0) [0|255] "" Vector__XXX
 SG_ Reserved_bit_3 : 0|1@1+ (1,0) [0|0] "" Vector__XXX
 SG_ Reserved_bit_2 : 0|1@1+ (1,0) [0|0] "" Vector__XXX
 SG_ Reserved_bit_1 : 0|1@1+ (1,0) [0|0] "" Vector__XXX
 SG_ Reserved_bit_7 : 0|1@1+ (1,0) [0|0] "" Vector__XXX
 SG_ Reserved_bit_6 : 0|1@1+ (1,0) [0|0] "" Vector__XXX
 SG_ Reserved_bit_5 : 0|1@1+ (1,0) [0|0] "" Vector__XXX
 SG_ Reserved_bit_3 : 0|1@1+ (1,0) [0|0] "" Vector__XXX
 SG_ Reserved_0 : 0|8@1+ (1,0) [0|255] "" Vector__XXX
 SG_ Reserved_bit_3 : 0|1@1+ (1,0) [0|0] "" Vector__XXX
 SG_ Reserved_bit_2 : 0|1@1+ (1,0) [0|0] "" Vector__XXX
 SG_ Reserved_bit_1 : 0|1@1+ (1,0) [0|0] "" Vector__XXX
 SG_ Reserved_bit_7 : 0|1@1+ (1,0) [0|0] "" Vector__XXX
 SG_ Reserved_bit_6 : 0|1@1+ (1,0) [0|0] "" Vector__XXX
 SG_ Reserved_bit_5 : 0|1@1+ (1,0) [0|0] "" Vector__XXX
 SG_ Reserved_5 : 0|8@1+ (1,0) [0|255] "" Vector__XXX
 SG_ Reserved_4 : 0|8@1+ (1,0) [0|255] "" Vector__XXX
 SG_ Reserved_3 : 0|8@1+ (1,0) [0|255] "" Vector__XXX
 SG_ Reserved_2 : 0|8@1+ (1,0) [0|255] "" Vector__XXX
 SG_ Reserved_1 : 0|8@1+ (1,0) [0|255] "" Vector__XXX
 SG_ Reserved_7 : 0|8@1+ (1,0) [0|255] "" Vector__XXX
 SG_ Reserved_bit_5 : 0|1@1+ (1,0) [0|0] "" Vector__XXX
 SG_ Reserved_bit_7 : 0|1@1+ (1,0) [0|0] "" Vector__XXX
 SG_ Reserved_bit_6 : 0|1@1+ (1,0) [0|0] "" Vector__XXX
 SG_ Reserved_bit_5 : 0|1@1+ (1,0) [0|0] "" Vector__XXX
 SG_ Reserved_bit_4 : 0|1@1+ (1,0) [0|0] "" Vector__XXX
 SG_ Reserved_bit_3 : 0|1@1+ (1,0) [0|0] "" Vector__XXX
 SG_ Reserved_bit_4 : 0|1@1+ (1,0) [0|0] "" Vector__XXX
 SG_ Reserved_bit_1 : 0|1@1+ (1,0) [0|0] "" Vector__XXX
 SG_ ST_WARN_OTMP_HVSTO : 0|2@1+ (1,0) [0|3] "" Vector__XXX
 SG_ Limitation_Mode : 0|4@1+ (1,0) [0|15] "" Vector__XXX
 SG_ BatterySensorVoltage : 0|16@1+ (0.05,0) [0|3212.75] "Volt" Vector__XXX
 SG_ Reserved_7 : 0|8@1+ (1,0) [0|255] "" Vector__XXX
 SG_ Reserved_6 : 0|8@1+ (1,0) [0|255] "" Vector__XXX
 SG_ Reserved_bit_5 : 0|1@1+ (1,0) [0|0] "" Vector__XXX
 SG_ Reserved_bit_4 : 0|1@1+ (1,0) [0|0] "" Vector__XXX
 SG_ Reserved_bit_3 : 0|1@1+ (1,0) [0|0] "" Vector__XXX
 SG_ Reserved_bit_3 : 0|1@1+ (1,0) [0|0] "" Vector__XXX
 SG_ Reserved_bit_2 : 0|1@1+ (1,0) [0|0] "" Vector__XXX
 SG_ Reserved_bit_2 : 0|1@1+ (1,0) [0|0] "" Vector__XXX
 SG_ Reserved_bit_1 : 0|1@1+ (1,0) [0|0] "" Vector__XXX
 SG_ Reserved_bit_1 : 0|1@1+ (1,0) [0|0] "" Vector__XXX
 SG_ Reserved_bit : 0|1@1+ (1,0) [0|0] "" Vector__XXX
 SG_ Reserved_bit : 0|1@1+ (1,0) [0|0] "" Vector__XXX
 SG_ Command_Enable_DCD2_2 : 0|2@1+ (1,0) [0|3] "" Vector__XXX
 SG_ Command_Enable_DCD2_1 : 0|2@1+ (1,0) [0|3] "" Vector__XXX
 SG_ WakeupRsn_VCVCCU : 0|8@1+ (1,0) [0|255] "" Vector__XXX
 SG_ Awakediag_Clamp15_Actv_VCVCCU : 0|1@1+ (1,0) [0|1] "" Vector__XXX
 SG_ Awakediag_Chargecom_Actv_VCVCCU : 0|1@1+ (1,0) [0|1] "" Vector__XXX
 SG_ Awakediag_Actv_VCVCCU : 0|1@1+ (1,0) [0|1] "" Vector__XXX
 SG_ BMS_Errors : 0|16@1+ (1,0) [0|65535] "" Vector__XXX
 SG_ Task1_executionTime : 0|8@1+ (1,0) [0|255] "Integer" Vector__XXX
 SG_ Task1_executionTime : 0|8@1+ (1,0) [0|255] "Percentage" Vector__XXX
 SG_ Faults : 0|8@1+ (1,0) [0|255] "" Vector__XXX
 SG_ MCU_Errors : 0|8@1+ (1,0) [0|255] "" Vector__XXX
 SG_ TCU_Errors : 0|8@1+ (1,0) [0|255] "" Vector__XXX
 SG_ CP_Status : 0|1@1+ (1,0) [0|1] "" Vector__XXX
 SG_ CC_Status : 0|1@1+ (1,0) [0|1] "" Vector__XXX
 SG_ Charging_socket_over_temp_alarm : 0|1@1+ (1,0) [0|1] "" Vector__XXX
 SG_ Electronic_lock_status : 0|2@1+ (1,0) [0|3] "" Vector__XXX
 SG_ S2_switch_status : 0|1@1+ (1,0) [0|1] "" Vector__XXX
 SG_ Retain : 0|8@1+ (1,0) [0|255] "" Vector__XXX
 SG_ D_OBC_Status_flag : 0|8@1+ (1,0) [0|255] "" Vector__XXX

BO_ 2565875024 VCU_Data_and_Status3: 8 VCU
 SG_ VCU_State : 16|8@1+ (1,0) [0|255] "" Vector__XXX
 SG_ BMS_PRD_DUR_CHGNG : 0|16@1+ (1,0) [0|65532] "" Vector__XXX

BO_ 2349596414 New_Message_179: 8 Vector__XXX
 SG_ New_Signal_1422 : 16|8@1+ (1,0) [0|0] "" Vector__XXX

BO_ 2349530878 New_Message_178: 8 Vector__XXX
 SG_ New_Signal_1421 : 0|8@1+ (1,0) [0|0] "" Vector__XXX

BO_ 2349465342 VCU_Internal_Float_1: 8 VCU
 SG_ Dummy_Float_2 : 32|32@1- (1,0) [-3.4E+038|3.4E+038] "" Vector__XXX
 SG_ Dummy_Float1 : 0|32@1- (1,0) [-3.4E+038|3.4E+038] "" Vector__XXX

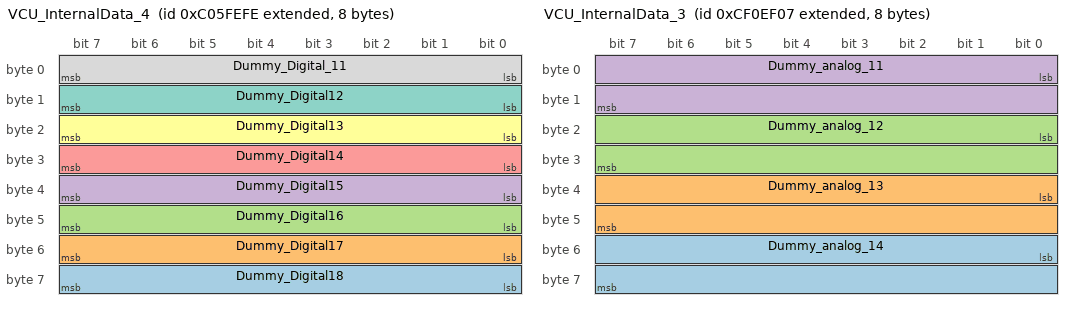
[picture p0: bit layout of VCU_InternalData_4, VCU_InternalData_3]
BO_ 2349203198 VCU_InternalData_4: 8 Vector__XXX
 SG_ Dummy_Digital18 : 56|8@1+ (1,0) [0|255] "" Vector__XXX
 SG_ Dummy_Digital17 : 48|8@1+ (1,0) [0|255] "" Vector__XXX
 SG_ Dummy_Digital16 : 40|8@1+ (1,0) [0|255] "" Vector__XXX
 SG_ Dummy_Digital15 : 32|8@1+ (1,0) [0|255] "" Vector__XXX
 SG_ Dummy_Digital14 : 24|8@1+ (1,0) [0|255] "" Vector__XXX
 SG_ Dummy_Digital13 : 16|8@1+ (1,0) [0|255] "" Vector__XXX
 SG_ Dummy_Digital12 : 8|8@1+ (1,0) [0|255] "" Vector__XXX
 SG_ Dummy_Digital_11 : 0|8@1+ (1,0) [0|255] "" Vector__XXX

BO_ 2364600071 VCU_InternalData_3: 8 Vector__XXX
 SG_ Dummy_analog_14 : 48|16@1+ (1,0) [0|65535] "" Vector__XXX
 SG_ Dummy_analog_13 : 32|16@1+ (1,0) [0|65535] "" Vector__XXX
 SG_ Dummy_analog_12 : 16|16@1+ (1,0) [0|65535] "" Vector__XXX
 SG_ Dummy_analog_11 : 0|16@1+ (1,0) [0|65535] "" Vector__XXX

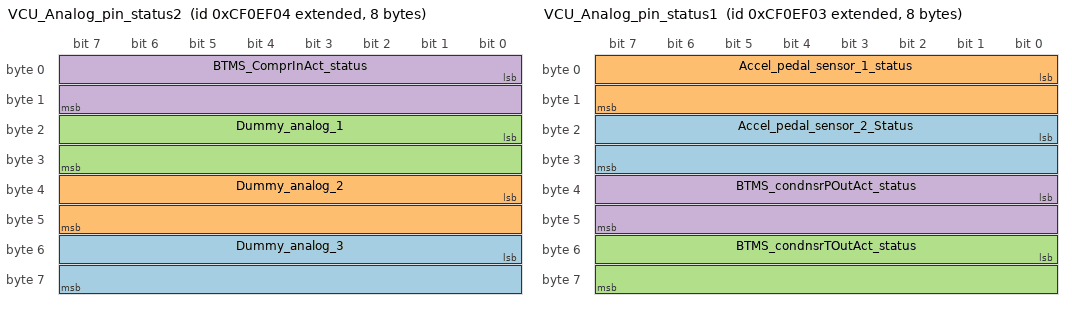
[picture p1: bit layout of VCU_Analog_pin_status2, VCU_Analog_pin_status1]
BO_ 2364600068 VCU_Analog_pin_status2: 8 VCU
 SG_ Dummy_analog_3 : 48|16@1+ (1,0) [0|65535] "" Vector__XXX
 SG_ Dummy_analog_2 : 32|16@1+ (1,0) [0|65535] "" Vector__XXX
 SG_ Dummy_analog_1 : 16|16@1+ (1,0) [0|65535] "" Vector__XXX
 SG_ BTMS_ComprInAct_status : 0|16@1+ (1,0) [0|65535] "" Vector__XXX

BO_ 2364600067 VCU_Analog_pin_status1: 8 VCU
 SG_ Accel_pedal_sensor_2_Status : 16|16@1+ (1,0) [0|65535] "" Vector__XXX
 SG_ Accel_pedal_sensor_1_status : 0|16@1+ (1,0) [0|65535] "" Vector__XXX
 SG_ BTMS_condnsrTOutAct_status : 48|16@1+ (1,0) [0|65535] "" Vector__XXX
 SG_ BTMS_condnsrPOutAct_status : 32|16@1+ (1,0) [0|65535] "" Vector__XXX

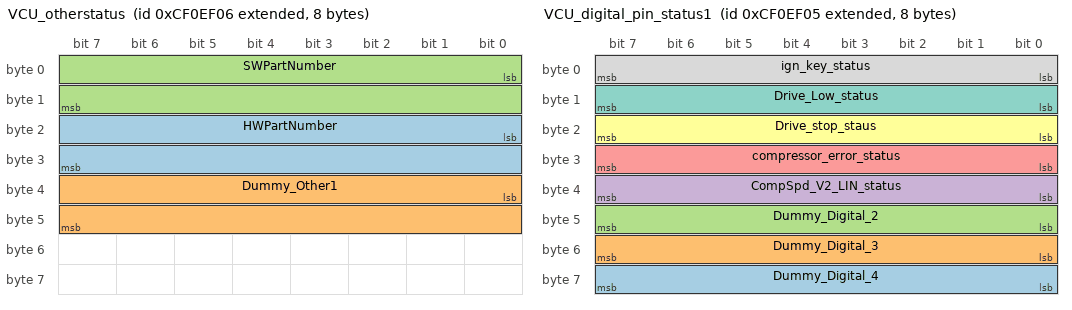
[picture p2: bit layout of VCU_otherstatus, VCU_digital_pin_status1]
BO_ 2364600070 VCU_otherstatus: 8 VCU
 SG_ HWPartNumber : 16|16@1+ (1,0) [0|65535] "" Vector__XXX
 SG_ Dummy_Other1 : 32|16@1+ (1,0) [0|65535] "" Vector__XXX
 SG_ SWPartNumber : 0|16@1+ (1,0) [0|65535] "" Vector__XXX

BO_ 2364600069 VCU_digital_pin_status1: 8 VCU
 SG_ Dummy_Digital_4 : 56|8@1+ (1,0) [0|255] "" Vector__XXX
 SG_ Dummy_Digital_3 : 48|8@1+ (1,0) [0|255] "" Vector__XXX
 SG_ Dummy_Digital_2 : 40|8@1+ (1,0) [0|255] "" Vector__XXX
 SG_ CompSpd_V2_LIN_status : 32|8@1+ (1,0) [0|255] "" Vector__XXX
 SG_ compressor_error_status : 24|8@1+ (1,0) [0|255] "" Vector__XXX
 SG_ Drive_stop_staus : 16|8@1+ (1,0) [0|255] "" Vector__XXX
 SG_ Drive_Low_status : 8|8@1+ (1,0) [0|255] "" Vector__XXX
 SG_ ign_key_status : 0|8@1+ (1,0) [0|255] "" Vector__XXX

BO_ 2565799713 Address_Claim_msg: 8 PKP_PRND_Keypad
 SG_ Address_Claim_Message : 0|64@1+ (1,0) [0|1.84467440737096E+019] "" Vector__XXX

BO_ 2565808384 PKP_PRND_Status: 8 VCU
 SG_ LED_secondary_color m1 : 48|8@1+ (1,0) [0|9] "" Vector__XXX
 SG_ LED_state m1 : 40|8@1+ (1,0) [0|3] "" Vector__XXX
 SG_ LED_color m1 : 32|8@1+ (1,0) [0|9] "" Vector__XXX
 SG_ Keypad_identifier m112 : 32|8@1+ (1,0) [0|253] "" Vector__XXX
 SG_ Heartbeat_period m117 : 32|8@1+ (10,0) [5|254] "msec" Vector__XXX
 SG_ Startup_LED_show m52 : 24|8@1+ (1,0) [0|2] "" Vector__XXX
 SG_ Startup_keys_message m40 : 24|8@1+ (1,0) [0|1] "" Vector__XXX
 SG_ Periodic_state_transmission m113 : 24|8@1+ (1,0) [0|1] "" Vector__XXX
 SG_ LED_brightness_level m2 : 24|8@1+ (1,0) [0|63] "" Vector__XXX
 SG_ LED_acknowledgment_state m115 : 24|8@1+ (1,0) [0|1] "" Vector__XXX
 SG_ Key_message_period m119 : 24|8@1+ (10,0) [5|254] "msec" Vector__XXX
 SG_ Key_LED_number m1 : 24|8@1+ (1,0) [1|4] "" Vector__XXX
 SG_ Heartbeat_state m117 : 24|8@1+ (1,0) [0|1] "" Vector__XXX
 SG_ Event_state_transmission m114 : 24|8@1+ (1,0) [0|255] "" Vector__XXX
 SG_ DEMO_mode m122 : 24|8@1+ (1,0) [0|1] "" Vector__XXX
 SG_ CANopen_protocol m128 : 24|8@1+ (1,0) [0|255] "" Vector__XXX
 SG_ CAN_source_address m112 : 24|8@1+ (1,0) [0|253] "" Vector__XXX
 SG_ CAN_destination_address m110 : 24|8@1+ (1,0) [0|255] "" Vector__XXX
 SG_ Baud_rate_setting m111 : 24|8@1+ (-250,1000) [2|3] "kbps" Vector__XXX
 SG_ Backlight_color m125 : 24|8@1+ (1,0) [1|9] "" Vector__XXX
 SG_ Backlight_brightness_level m3 : 24|8@1+ (1,0) [0|63] "" Vector__XXX
 SG_ Address_claim_at_boot m116 : 24|8@1+ (1,0) [0|1] "" Vector__XXX
 SG_ RX_command_list M : 16|8@1+ (1,0) [0|128] "" Vector__XXX

BO_ 2565865249 PKP_PRND_Command: 8 PKP_PRND_Keypad
 SG_ LED_state m115 : 40|8@1+ (1,0) [0|3] "" Vector__XXX
 SG_ TX_command_list M : 16|8@1+ (1,0) [1|249] "" Vector__XXX
 SG_ Message_counter m249 : 48|8@1+ (1,0) [0|255] "" Vector__XXX
 SG_ LED_secondary_color m115 : 32|8@1+ (1,0) [0|9] "" Vector__XXX
 SG_ LED_color m115 : 24|8@1+ (1,0) [0|9] "" Vector__XXX
 SG_ Key_Number m1 : 32|8@1+ (1,0) [1|4] "" Vector__XXX
 SG_ Contact_state m1 : 24|8@1+ (1,0) [0|1] "" Vector__XXX
 SG_ Button_state_indicators m249 : 32|4@1+ (1,0) [0|15] "" Vector__XXX

BO_ 2566866168 DC2_Faults1: 8 DCDC_Inmotion_DC2
 SG_ Fault9_DC2 : 16|2@1+ (1,0) [0|3] "" Vector__XXX
 SG_ Fault8_DC2 : 14|2@1+ (1,0) [0|3] "" Vector__XXX
 SG_ Fault7_DC2 : 12|2@1+ (1,0) [0|3] "" Vector__XXX
 SG_ Fault6_DC2 : 10|2@1+ (1,0) [0|3] "" Vector__XXX
 SG_ Fault5_DC2 : 8|2@1+ (1,0) [0|3] "" Vector__XXX
 SG_ Fault4_DC2 : 6|2@1+ (1,0) [0|3] "" Vector__XXX
 SG_ Fault3_DC2 : 4|2@1+ (1,0) [0|3] "" Vector__XXX
 SG_ Fault32_DC2 : 62|2@1+ (1,0) [0|3] "" Vector__XXX
 SG_ Fault31_DC2 : 60|2@1+ (1,0) [0|3] "" Vector__XXX
 SG_ Fault30_DC2 : 58|2@1+ (1,0) [0|3] "" Vector__XXX
 SG_ Fault2_DC2 : 2|2@1+ (1,0) [0|3] "" Vector__XXX
 SG_ Fault29_DC2 : 56|2@1+ (1,0) [0|3] "" Vector__XXX
 SG_ Fault28_DC2 : 54|2@1+ (1,0) [0|3] "" Vector__XXX
 SG_ Fault27_DC2 : 52|2@1+ (1,0) [0|3] "" Vector__XXX
 SG_ Fault26_DC2 : 50|2@1+ (1,0) [0|3] "" Vector__XXX
 SG_ Fault25_DC2 : 48|2@1+ (1,0) [0|3] "" Vector__XXX
 SG_ Fault24_DC2 : 46|2@1+ (1,0) [0|3] "" Vector__XXX
 SG_ Fault23_DC2 : 44|2@1+ (1,0) [0|3] "" Vector__XXX
 SG_ Fault22_DC2 : 42|2@1+ (1,0) [0|3] "" Vector__XXX
 SG_ Fault21_DC2 : 40|2@1+ (1,0) [0|3] "" Vector__XXX
 SG_ Fault20_DC2 : 38|2@1+ (1,0) [0|3] "" Vector__XXX
 SG_ Fault1_DC2 : 0|2@1+ (1,0) [0|3] "" Vector__XXX
 SG_ Fault19_DC2 : 36|2@1+ (1,0) [0|3] "" Vector__XXX
 SG_ Fault18_DC2 : 34|2@1+ (1,0) [0|3] "" Vector__XXX
 SG_ Fault17_DC2 : 32|2@1+ (1,0) [0|3] "" Vector__XXX
 SG_ Fault16_DC2 : 30|2@1+ (1,0) [0|3] "" Vector__XXX
 SG_ Fault15_DC2 : 28|2@1+ (1,0) [0|3] "" Vector__XXX
 SG_ Fault14_DC2 : 26|2@1+ (1,0) [0|3] "" Vector__XXX
 SG_ Fault13_DC2 : 24|2@1+ (1,0) [0|3] "" Vector__XXX
 SG_ Fault12_DC2 : 22|2@1+ (1,0) [0|3] "" Vector__XXX
 SG_ Fault11_DC2 : 20|2@1+ (1,0) [0|3] "" Vector__XXX
 SG_ Fault10_DC2 : 18|2@1+ (1,0) [0|3] "" Vector__XXX

BO_ 2566866166 DC1_Faults1: 8 DCDC_inmotion_DC1
 SG_ Fault9_DC2 : 16|2@1+ (1,0) [0|3] "" Vector__XXX
 SG_ Fault8_DC2 : 14|2@1+ (1,0) [0|3] "" Vector__XXX
 SG_ Fault7_DC2 : 12|2@1+ (1,0) [0|3] "" Vector__XXX
 SG_ Fault6_DC2 : 10|2@1+ (1,0) [0|3] "" Vector__XXX
 SG_ Fault5_DC2 : 8|2@1+ (1,0) [0|3] "" Vector__XXX
 SG_ Fault4_DC2 : 6|2@1+ (1,0) [0|3] "" Vector__XXX
 SG_ Fault3_DC2 : 4|2@1+ (1,0) [0|3] "" Vector__XXX
 SG_ Fault32_DC2 : 62|2@1+ (1,0) [0|3] "" Vector__XXX
 SG_ Fault31_DC2 : 60|2@1+ (1,0) [0|3] "" Vector__XXX
 SG_ Fault30_DC2 : 58|2@1+ (1,0) [0|3] "" Vector__XXX
 SG_ Fault2_DC2 : 2|2@1+ (1,0) [0|3] "" Vector__XXX
 SG_ Fault29_DC2 : 56|2@1+ (1,0) [0|3] "" Vector__XXX
 SG_ Fault28_DC2 : 54|2@1+ (1,0) [0|3] "" Vector__XXX
 SG_ Fault27_DC2 : 52|2@1+ (1,0) [0|3] "" Vector__XXX
 SG_ Fault26_DC2 : 50|2@1+ (1,0) [0|3] "" Vector__XXX
 SG_ Fault25_DC2 : 48|2@1+ (1,0) [0|3] "" Vector__XXX
 SG_ Fault24_DC2 : 46|2@1+ (1,0) [0|3] "" Vector__XXX
 SG_ Fault23_DC2 : 44|2@1+ (1,0) [0|3] "" Vector__XXX
 SG_ Fault22_DC2 : 42|2@1+ (1,0) [0|3] "" Vector__XXX
 SG_ Fault21_DC2 : 40|2@1+ (1,0) [0|3] "" Vector__XXX
 SG_ Fault20_DC2 : 38|2@1+ (1,0) [0|3] "" Vector__XXX
 SG_ Fault1_DC2 : 0|2@1+ (1,0) [0|3] "" Vector__XXX
 SG_ Fault19_DC2 : 36|2@1+ (1,0) [0|3] "" Vector__XXX
 SG_ Fault18_DC2 : 34|2@1+ (1,0) [0|3] "" Vector__XXX
 SG_ Fault17_DC2 : 32|2@1+ (1,0) [0|3] "" Vector__XXX
 SG_ Fault16_DC2 : 30|2@1+ (1,0) [0|3] "" Vector__XXX
 SG_ Fault15_DC2 : 28|2@1+ (1,0) [0|3] "" Vector__XXX
 SG_ Fault14_DC2 : 26|2@1+ (1,0) [0|3] "" Vector__XXX
 SG_ Fault13_DC2 : 24|2@1+ (1,0) [0|3] "" Vector__XXX
 SG_ Fault12_DC2 : 22|2@1+ (1,0) [0|3] "" Vector__XXX
 SG_ Fault11_DC2 : 20|2@1+ (1,0) [0|3] "" Vector__XXX
 SG_ Fault10_DC2 : 18|2@1+ (1,0) [0|3] "" Vector__XXX

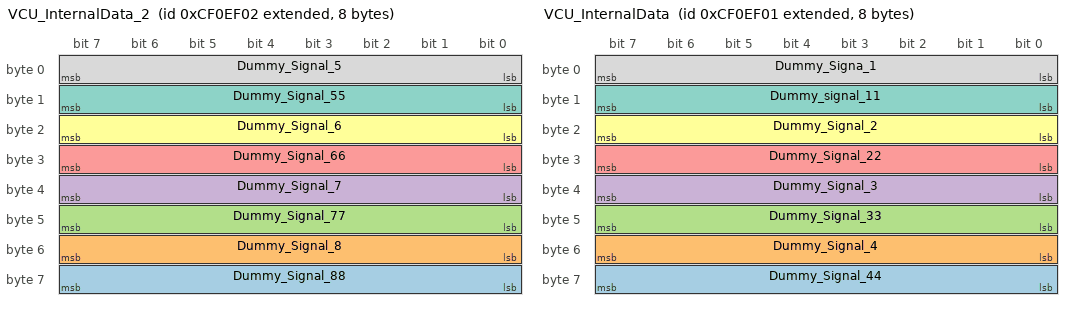
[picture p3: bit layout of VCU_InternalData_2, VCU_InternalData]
BO_ 2364600066 VCU_InternalData_2: 8 VCU
 SG_ Dummy_Signal_88 : 56|8@1+ (1,0) [0|255] "Percentage" Vector__XXX
 SG_ Dummy_Signal_8 : 48|8@1+ (1,0) [0|255] "Integer" Vector__XXX
 SG_ Dummy_Signal_77 : 40|8@1+ (1,0) [0|255] "Percentage" Vector__XXX
 SG_ Dummy_Signal_7 : 32|8@1+ (1,0) [0|255] "Integer" Vector__XXX
 SG_ Dummy_Signal_66 : 24|8@1+ (1,0) [0|255] "percentage" Vector__XXX
 SG_ Dummy_Signal_6 : 16|8@1+ (1,0) [0|255] "Integer" Vector__XXX
 SG_ Dummy_Signal_55 : 8|8@1+ (1,0) [0|255] "Percentage" Vector__XXX
 SG_ Dummy_Signal_5 : 0|8@1+ (1,0) [0|255] "Integer" Vector__XXX

BO_ 2364600065 VCU_InternalData: 8 VCU
 SG_ Dummy_Signal_44 : 56|8@1+ (1,0) [0|255] "percentage" Vector__XXX
 SG_ Dummy_Signal_4 : 48|8@1+ (1,0) [0|255] "Integer" Vector__XXX
 SG_ Dummy_Signal_33 : 40|8@1+ (1,0) [0|255] "percentage" Vector__XXX
 SG_ Dummy_Signal_3 : 32|8@1+ (1,0) [0|255] "Integer" Vector__XXX
 SG_ Dummy_Signal_22 : 24|8@1+ (1,0) [0|255] "percentage" Vector__XXX
 SG_ Dummy_Signal_2 : 16|8@1+ (1,0) [0|255] "Integer" Vector__XXX
 SG_ Dummy_signal_11 : 8|8@1+ (1,0) [0|255] "Percentage" Vector__XXX
 SG_ Dummy_Signa_1 : 0|8@1+ (1,0) [0|255] "Integer" Vector__XXX

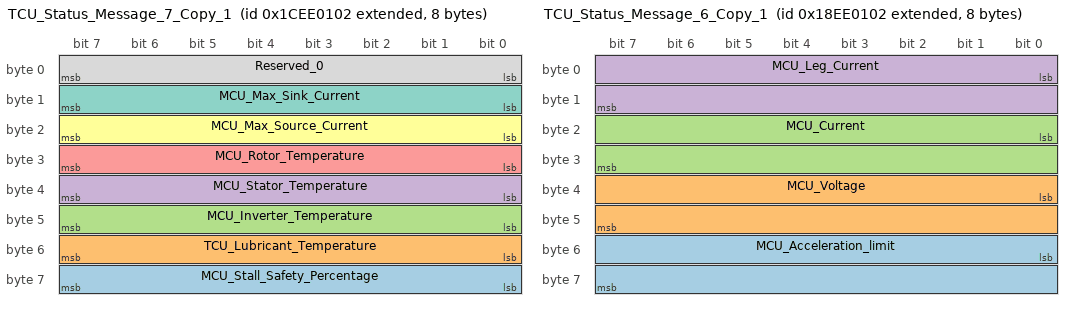
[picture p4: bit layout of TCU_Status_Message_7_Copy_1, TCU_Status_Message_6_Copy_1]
BO_ 2632843522 TCU_Status_Message_7_Copy_1: 8 TCU
 SG_ MCU_Stall_Safety_Percentage : 56|8@1+ (0.4,0) [0|100] "%" Vector__XXX
 SG_ TCU_Lubricant_Temperature : 48|8@1+ (1,-40) [-40|210] "°C" Vector__XXX
 SG_ MCU_Inverter_Temperature : 40|8@1+ (1,-40) [-40|210] "°C" Vector__XXX
 SG_ MCU_Stator_Temperature : 32|8@1+ (1,-40) [-40|210] "°C" Vector__XXX
 SG_ MCU_Rotor_Temperature : 24|8@1+ (1,-40) [-40|210] "°C" Vector__XXX
 SG_ MCU_Max_Source_Current : 16|8@1+ (5,0) [0|1275] "Amps" Vector__XXX
 SG_ MCU_Max_Sink_Current : 8|8@1+ (5,0) [0|1275] "Amps" Vector__XXX
 SG_ Reserved_0 : 0|8@1+ (1,0) [0|255] "" Vector__XXX

BO_ 2565734658 TCU_Status_Message_6_Copy_1: 8 TCU
 SG_ MCU_Acceleration_limit : 48|16@1+ (1,0) [0|32768] "rpm/s " Vector__XXX
 SG_ MCU_Voltage : 32|16@1- (0.1,0) [-3212.8|3212.8] "volts" Vector__XXX
 SG_ MCU_Current : 16|16@1- (0.1,0) [-3212.8|3212.8] "amps" Vector__XXX
 SG_ MCU_Leg_Current : 0|16@1+ (1,0) [0|32768] "amps" Vector__XXX

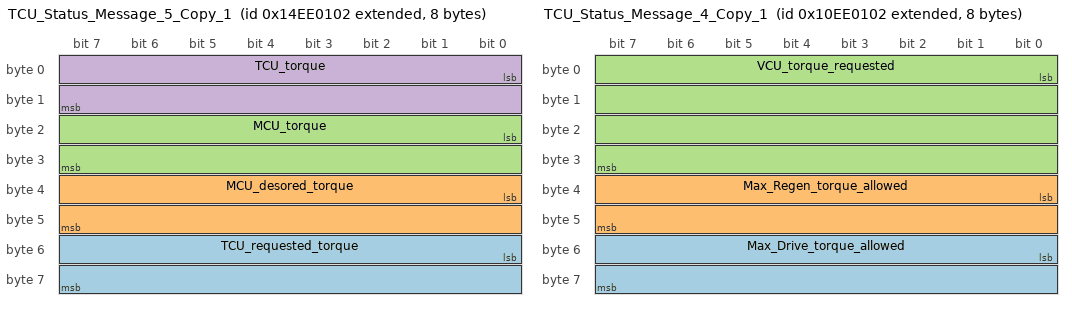
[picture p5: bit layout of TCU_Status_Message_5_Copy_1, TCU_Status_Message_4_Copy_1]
BO_ 2498625794 TCU_Status_Message_5_Copy_1: 8 TCU
 SG_ TCU_requested_torque : 48|16@1- (0.1,0) [-3212.8|3212.8] "Nm" Vector__XXX
 SG_ MCU_desored_torque : 32|16@1- (0.1,0) [-3212.8|3212.8] "Nm" Vector__XXX
 SG_ MCU_torque : 16|16@1- (0.1,0) [-3212.8|3212.8] "Nm" Vector__XXX
 SG_ TCU_torque : 0|16@1- (0.2,0) [-6425.6|6425.6] "Nm" Vector__XXX

BO_ 2431516930 TCU_Status_Message_4_Copy_1: 8 TCU
 SG_ Max_Drive_torque_allowed : 48|16@1+ (0.1,0) [0|6425.6] "Nm" Vector__XXX
 SG_ Max_Regen_torque_allowed : 32|16@1+ (0.1,0) [0|6425.6] "Nm" Vector__XXX
 SG_ VCU_torque_requested : 0|32@1- (0.1,0) [-6425.6|6425.6] "Nm" Vector__XXX

BO_ 2364408066 TCU_Status_Message_3_Copy_1: 8 TCU
 SG_ MCU_inverter_fault : 63|1@1+ (1,0) [0|1] "Boolean" Vector__XXX
 SG_ MCU_intverter_fault_history : 62|1@1+ (1,0) [0|1] "Boolean" Vector__XXX
 SG_ MCU_intverter_fault_latched : 61|1@1+ (1,0) [0|1] "Boolean" Vector__XXX
 SG_ MCU_intverter_fault_latch_histry : 60|1@1+ (1,0) [0|1] "Boolean" Vector__XXX
 SG_ MCU_limp_home_mode : 59|1@1+ (1,0) [0|1] "Boolean" Vector__XXX
 SG_ MCU_limp_home_mode_history : 58|1@1+ (1,0) [0|1] "Boolean" Vector__XXX
 SG_ MCU_ADC_calibration_problem : 57|1@1+ (1,0) [0|1] "Boolean" Vector__XXX
 SG_ MCU_ADC_calibrate_prblem_histry : 56|1@1+ (1,0) [0|1] "Boolean" Vector__XXX
 SG_ MCU_overvoltage_alarm_history : 54|1@1+ (1,0) [0|1] "Boolean" Vector__XXX
 SG_ MCU_overvoltage_alarm : 55|1@1+ (1,0) [0|1] "Boolean" Vector__XXX
 SG_ MCU_overspeed_alarm : 53|1@1+ (1,0) [0|1] "Boolean" Vector__XXX
 SG_ MCU_overspeed_alarm_history : 52|1@1+ (1,0) [0|1] "Boolean" Vector__XXX
 SG_ MCU_overvoltage_warning : 51|1@1+ (1,0) [0|1] "Boolean" Vector__XXX
 SG_ MCU_overvoltage_warning_history : 50|1@1+ (1,0) [0|1] "Boolean" Vector__XXX
 SG_ MCU_over_speed_warning : 49|1@1+ (1,0) [0|1] "Boolean" Vector__XXX
 SG_ MCU_over_speed_warning_history : 48|1@1+ (1,0) [0|1] "Boolean" Vector__XXX
 SG_ MCU_inverter_over_temp : 47|1@1+ (1,0) [0|1] "Boolean" Vector__XXX
 SG_ MCU_inverter_over_temp_history : 46|1@1+ (1,0) [0|1] "Boolean" Vector__XXX
 SG_ MCU_stator_over_temp : 45|1@1+ (1,0) [0|1] "Boolean" Vector__XXX
 SG_ MCU_stator_over_temp_history : 44|1@1+ (1,0) [0|1] "Boolean" Vector__XXX
 SG_ MCU_rotor_over_temp : 43|1@1+ (1,0) [0|1] "Boolean" Vector__XXX
 SG_ MCU_rotor_over_temp_history : 42|1@1+ (1,0) [0|1] "Boolean" Vector__XXX
 SG_ MCU_undervoltage_warning : 41|1@1+ (1,0) [0|1] "Boolean" Vector__XXX
 SG_ MCU_undervoltage_warning_history : 40|1@1+ (1,0) [0|1] "Boolean" Vector__XXX
 SG_ MCU_over_phase_advance : 39|1@1+ (1,0) [0|1] "Boolean" Vector__XXX
 SG_ MCU_over_phase_advance_history : 38|1@1+ (1,0) [0|1] "Boolean" Vector__XXX
 SG_ MCU_over_bus_current : 37|1@1+ (1,0) [0|1] "Boolean" Vector__XXX
 SG_ MCU_over_bus_current_history : 36|1@1+ (1,0) [0|1] "Boolean" Vector__XXX
 SG_ MCU_over_leg_current : 35|1@1+ (1,0) [0|1] "Boolean" Vector__XXX
 SG_ MCU_over_leg_current_history : 34|1@1+ (1,0) [0|1] "Boolean" Vector__XXX
 SG_ MCU_not_enabled : 33|1@1+ (1,0) [0|1] "Boolean" Vector__XXX
 SG_ MCU_not_enabled_history : 32|1@1+ (1,0) [0|1] "Boolean" Vector__XXX
 SG_ Transmission_output_speed : 16|16@1- (1,0) [-16384|16384] "rpm" Vector__XXX
 SG_ MCU_motor_speed : 0|16@1- (1,0) [-16384|16384] "rpm" Vector__XXX

BO_ 2297299202 TCU_Status_Message_2_Copy_1: 8 TCU
 SG_ Current_transmission_mode : 60|4@1+ (1,0) [0|6] "Enumerated" Vector__XXX
 SG_ Selected_Gear : 58|2@1+ (1,0) [0|3] "Enumeration" Vector__XXX
 SG_ Upshift_in_progress : 57|1@1+ (1,0) [0|1] "Boolean" Vector__XXX
 SG_ Downshift_In_Progress : 56|1@1+ (1,0) [0|1] "Boolean" Vector__XXX
 SG_ Upshift_Failed : 55|1@1+ (1,0) [0|1] "Boolean" Vector__XXX
 SG_ DownShift_Failed : 54|1@1+ (1,0) [0|1] "Boolean" Vector__XXX
 SG_ Slow_Upshift : 53|1@1+ (1,0) [0|1] "Boolean" Vector__XXX
 SG_ Slow_Downshift : 52|1@1+ (1,0) [0|1] "Boolean" Vector__XXX
 SG_ Shift_Disabled : 51|1@1+ (1,0) [0|1] "Boolean" Vector__XXX
 SG_ Max_Shift_Speed_Delta_Exceeded : 50|1@1+ (1,0) [0|1] "Boolean" Vector__XXX
 SG_ Air_Pressure_Out_of_Range : 49|1@1+ (1,0) [0|1] "Boolean" Vector__XXX
 SG_ Forced_Gear_Engagement_Torque : 48|1@1+ (1,0) [0|1] "Boolean" Vector__XXX
 SG_ Motor_speed_mistach_match_error : 47|1@1+ (1,0) [0|1] "Boolean" Vector__XXX
 SG_ Driveshaft_speed_mistach_match : 46|1@1+ (1,0) [0|1] "Boolean" Vector__XXX
 SG_ MCU_CAN_Active : 45|1@1+ (1,0) [0|1] "Boolean" Vector__XXX
 SG_ MCU_CAN_Timeout : 44|1@1+ (1,0) [0|1] "Boolean" Vector__XXX
 SG_ MCU_Watchdog_error : 43|1@1+ (1,0) [0|1] "Boolean" Vector__XXX
 SG_ TCU_command_Msg1_error : 42|1@1+ (1,0) [0|1] "Boolean" Vector__XXX
 SG_ TCU_cmd_MSG1_watchdog_timeout : 41|1@1+ (1,0) [0|1] "Boolean" Vector__XXX
 SG_ TCU_command_MSG2_error : 40|1@1+ (1,0) [0|1] "Boolean" Vector__XXX
 SG_ TCU_cmd_MSG2_watchdog_timeout : 39|1@1+ (1,0) [0|1] "Boolean" Vector__XXX
 SG_ Trans_temp_warning : 38|1@1+ (1,0) [0|1] "Boolean" Vector__XXX
 SG_ Trans_temp_error : 37|1@1+ (1,0) [0|1] "Boolean" Vector__XXX
 SG_ Trans_temp_limiting : 36|1@1+ (1,0) [0|1] "Boolean" Vector__XXX
 SG_ Trans_temp_read_error : 35|1@1+ (1,0) [0|1] "Boolean" Vector__XXX
 SG_ MCU_inveter_temp_read_error : 34|1@1+ (1,0) [0|1] "Boolean" Vector__XXX
 SG_ MCU_stator_temp_read_error : 33|1@1+ (1,0) [0|1] "Boolean" Vector__XXX
 SG_ MCU_rotar_temp_read_error : 32|1@1+ (1,0) [0|1] "Boolean" Vector__XXX
 SG_ MCU_regen_type_error : 31|1@1+ (1,0) [0|1] "Boolean" Vector__XXX
 SG_ Factory_diagnostic_MSG_LSB : 16|15@1+ (1,0) [0|32767] "" Vector__XXX
 SG_ MCU_power_switches_off : 15|1@1+ (1,0) [0|1] "Boolean" Vector__XXX
 SG_ MCU_invalid_power_supply : 14|1@1+ (1,0) [0|1] "Boolean" Vector__XXX
 SG_ MCU_bad_switch : 13|1@1+ (1,0) [0|1] "Boolean" Vector__XXX
 SG_ MCU_bad_position_signal : 12|1@1+ (1,0) [0|1] "Boolean" Vector__XXX
 SG_ MCU_phase_current_sensor_error : 11|1@1+ (1,0) [0|1] "Boolean" Vector__XXX
 SG_ MCU_stall_condition_active : 10|1@1+ (1,0) [0|1] "Boolean" Vector__XXX
 SG_ MCU_forces_open_loop : 9|1@1+ (1,0) [0|1] "Boolean" Vector__XXX
 SG_ MCU_turbo_mode : 8|1@1+ (1,0) [0|1] "Boolean" Vector__XXX
 SG_ MCU_using_raw_speed : 7|1@1+ (1,0) [0|1] "Boolean" Vector__XXX
 SG_ MCU_accel_limited : 6|1@1+ (1,0) [0|1] "Boolean" Vector__XXX
 SG_ MCU_current_trip_failt_lleg_bus : 5|1@1+ (1,0) [0|1] "Boolean" Vector__XXX
 SG_ MCU_CAN_limits_active : 1|1@1+ (1,0) [0|1] "Boolean" Vector__XXX
 SG_ MCU_RegenSwitchOPen : 4|1@1+ (1,0) [0|1] "Boolean" Vector__XXX
 SG_ MCU_ABC_phase_order : 3|1@1+ (1,0) [0|1] "Enumeration" Vector__XXX
 SG_ MCU_system_disable_in_motion : 2|1@1+ (1,0) [0|1] "Boolean" Vector__XXX
 SG_ MCU_forced_voltage_control : 0|1@1+ (1,0) [0|1] "Boolean" Vector__XXX

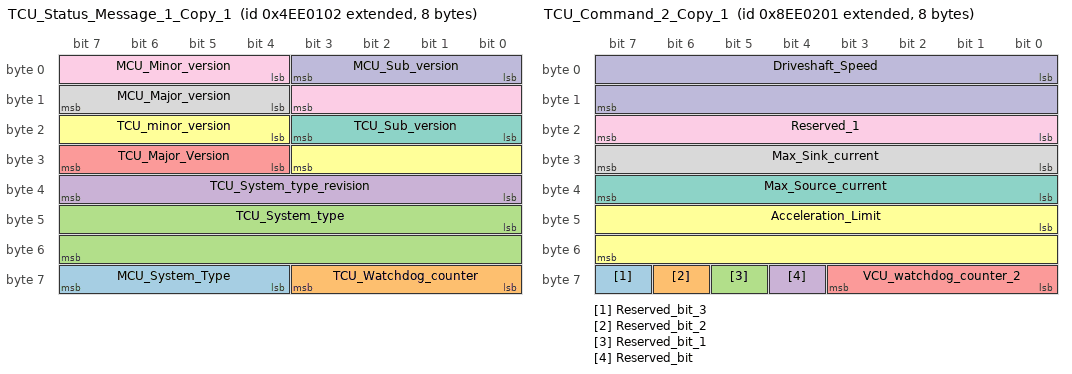
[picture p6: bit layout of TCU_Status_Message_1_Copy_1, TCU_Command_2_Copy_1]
BO_ 2230190338 TCU_Status_Message_1_Copy_1: 8 TCU
 SG_ MCU_System_Type : 60|4@1+ (1,0) [0|15] "Enumeration" Vector__XXX
 SG_ TCU_Watchdog_counter : 56|4@1+ (1,0) [0|15] "Rolling Count" Vector__XXX
 SG_ TCU_System_type : 40|16@1+ (1,0) [0|65535] "Enumeration" Vector__XXX
 SG_ TCU_System_type_revision : 32|8@1+ (1,0) [0|255] "Enumeration" Vector__XXX
 SG_ TCU_Major_Version : 28|4@1+ (1,0) [0|15] "Integer" Vector__XXX
 SG_ TCU_minor_version : 20|8@1+ (1,0) [0|15] "Integer" Vector__XXX
 SG_ TCU_Sub_version : 16|4@1+ (1,0) [0|15] "Integer" Vector__XXX
 SG_ MCU_Major_version : 12|4@1+ (1,0) [0|15] "Integer" Vector__XXX
 SG_ MCU_Minor_version : 4|8@1+ (1,0) [0|15] "Integer" Vector__XXX
 SG_ MCU_Sub_version : 0|4@1+ (1,0) [0|15] "Integer" Vector__XXX

BO_ 2297299457 TCU_Command_2_Copy_1: 8 VCU
 SG_ Reserved_bit_3 : 63|1@1+ (1,0) [0|0] "" Vector__XXX
 SG_ Reserved_bit_2 : 62|1@1+ (1,0) [0|0] "" Vector__XXX
 SG_ Reserved_bit_1 : 61|1@1+ (1,0) [0|0] "" Vector__XXX
 SG_ Reserved_bit : 60|1@1+ (1,0) [0|0] "" Vector__XXX
 SG_ VCU_watchdog_counter_2 : 56|4@1+ (1,0) [0|15] "Counter" Vector__XXX
 SG_ Acceleration_Limit : 40|16@1+ (1,0) [0|32128] "rpm / s" Vector__XXX
 SG_ Max_Source_current : 32|8@1+ (5,0) [0|1275] "Amps" Vector__XXX
 SG_ Max_Sink_current : 24|8@1+ (5,0) [0|1275] "Amps" Vector__XXX
 SG_ Reserved_1 : 16|8@1+ (1,0) [0|255] "" Vector__XXX
 SG_ Driveshaft_Speed : 0|16@1- (1,0) [-16384|16383] "rpm" Vector__XXX

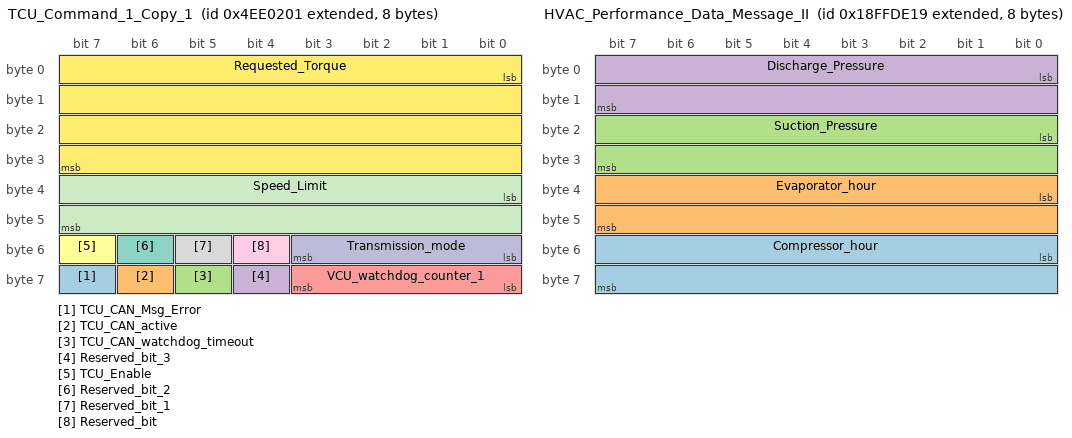
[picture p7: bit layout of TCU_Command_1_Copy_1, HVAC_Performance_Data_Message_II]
BO_ 2230190593 TCU_Command_1_Copy_1: 8 VCU
 SG_ TCU_CAN_Msg_Error : 63|1@1+ (1,0) [0|1] "Boolean" Vector__XXX
 SG_ TCU_CAN_active : 62|1@1+ (1,0) [0|1] "Boolean" Vector__XXX
 SG_ TCU_CAN_watchdog_timeout : 61|1@1+ (1,0) [0|1] "Boolean" Vector__XXX
 SG_ Reserved_bit_3 : 60|1@1+ (1,0) [0|0] "" Vector__XXX
 SG_ VCU_watchdog_counter_1 : 56|4@1+ (1,0) [0|15] "Integer" Vector__XXX
 SG_ TCU_Enable : 55|1@1+ (1,0) [0|1] "Boolean" Vector__XXX
 SG_ Reserved_bit_2 : 54|1@1+ (1,0) [0|0] "" Vector__XXX
 SG_ Reserved_bit_1 : 53|1@1+ (1,0) [0|0] "" Vector__XXX
 SG_ Reserved_bit : 52|1@1+ (1,0) [0|0] "" Vector__XXX
 SG_ Transmission_mode : 48|4@1+ (1,0) [0|4] "Enumeration" Vector__XXX
 SG_ Speed_Limit : 32|16@1+ (1,0) [0|4800] "RPM" Vector__XXX
 SG_ Requested_Torque : 0|32@1- (0.1,0) [-6425.6|6425.6] "Nm" Vector__XXX

BO_ 2349137662 New_Message_154: 8 Vector__XXX
 SG_ New_Signal_1048 : 24|8@1+ (1,0) [0|255] "" Vector__XXX

BO_ 2348941054 New_Message_153: 8 Vector__XXX
 SG_ New_Signal_1047 : 8|8@1+ (1,0) [0|255] "" Vector__XXX

BO_ 2565865873 EBS_Brake: 8 Praker_GW
 SG_ VMM_Halt_brake_status : 58|2@1+ (1,0) [0|3] "" Vector__XXX

BO_ 2566838809 HVAC_response: 8 HVAC
 SG_ Hvac_response : 0|64@1- (1,0) [-9.22337203685478E+018|9.22337203685478E+018] "" Vector__XXX

BO_ 2565603097 HVAC_DM1_BAM: 8 HVAC
 SG_ HVAC_BAM : 0|64@1- (1,0) [-9.22337203685478E+018|9.22337203685478E+018] "" Vector__XXX

BO_ 2565668633 HVAC_DM1_multiple_fault: 8 HVAC
 SG_ HVAC_multi_fault : 0|64@1- (1,0) [-9.22337203685478E+018|9.22337203685478E+018] "" Vector__XXX

BO_ 2566834713 HVAC_DM1: 8 HVAC
 SG_ HVAC_DM1 : 0|64@1- (1,0) [-9.22337203685478E+018|9.22337203685478E+018] "" Vector__XXX

BO_ 2565478721 Req_HVAC_SW_ID_: 8 VCU
 SG_ HVAC_req_sw : 0|64@1- (1,0) [-9.22337203685478E+018|9.22337203685478E+018] "" Vector__XXX

BO_ 2566905369 HVAC_Performance_Data_Message_II: 8 HVAC
 SG_ Compressor_hour : 48|16@1+ (1,0) [0|60000] "" Vector__XXX
 SG_ Evaporator_hour : 32|16@1+ (1,0) [0|60000] "" Vector__XXX
 SG_ Suction_Pressure : 16|16@1+ (1,0) [0|500] "" Vector__XXX
 SG_ Discharge_Pressure : 0|16@1+ (1,0) [0|500] "" Vector__XXX

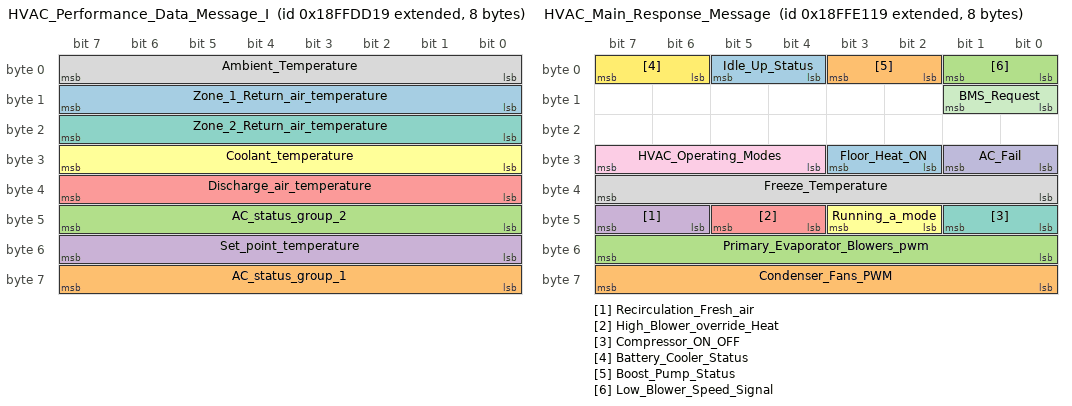
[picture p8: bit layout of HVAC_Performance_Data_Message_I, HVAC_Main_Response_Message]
BO_ 2566905113 HVAC_Performance_Data_Message_I: 8 HVAC
 SG_ Zone_1_Return_air_temperature : 8|8@1+ (1,-40) [-40|80] "deg.cel" Vector__XXX
 SG_ AC_status_group_1 : 56|8@1+ (1,0) [0|255] "" Vector__XXX
 SG_ AC_status_group_2 : 40|8@1+ (1,0) [0|255] "" Vector__XXX
 SG_ Set_point_temperature : 48|8@1+ (1,-40) [-40|80] "deg.cel" Vector__XXX
 SG_ Discharge_air_temperature : 32|8@1+ (1,-40) [-40|80] "deg.cel" Vector__XXX
 SG_ Coolant_temperature : 24|8@1+ (1,-40) [-40|80] "deg.cel" Vector__XXX
 SG_ Zone_2_Return_air_temperature : 16|8@1+ (1,-40) [-40|80] "deg.cel" Vector__XXX
 SG_ Ambient_Temperature : 0|8@1+ (1,-40) [-40|80] "deg.cel" Vector__XXX

BO_ 2566906137 HVAC_Main_Response_Message: 8 HVAC
 SG_ Floor_Heat_ON : 26|2@1+ (1,0) [0|3] "" Vector__XXX
 SG_ Condenser_Fans_PWM : 56|8@1+ (1,0) [0|100] "" Vector__XXX
 SG_ Primary_Evaporator_Blowers_pwm : 48|8@1+ (1,0) [0|100] "" Vector__XXX
 SG_ Recirculation_Fresh_air : 46|2@1+ (1,0) [0|3] "" Vector__XXX
 SG_ High_Blower_override_Heat : 44|2@1+ (1,0) [0|3] "" Vector__XXX
 SG_ Running_a_mode : 42|2@1+ (1,0) [0|3] "" Vector__XXX
 SG_ Compressor_ON_OFF : 40|2@1+ (1,0) [0|3] "" Vector__XXX
 SG_ Freeze_Temperature : 32|8@1+ (1,-40) [-40|80] "deg.cel" Vector__XXX
 SG_ HVAC_Operating_Modes : 28|4@1+ (1,0) [0|15] "" Vector__XXX
 SG_ AC_Fail : 24|2@1+ (1,0) [0|3] "" Vector__XXX
 SG_ BMS_Request : 8|2@1+ (1,0) [0|3] "" Vector__XXX
 SG_ Battery_Cooler_Status : 6|2@1+ (1,0) [0|3] "" Vector__XXX
 SG_ Idle_Up_Status : 4|2@1+ (1,0) [0|3] "" Vector__XXX
 SG_ Boost_Pump_Status : 2|2@1+ (1,0) [0|3] "" Vector__XXX
 SG_ Low_Blower_Speed_Signal : 0|2@1+ (1,0) [0|3] "" Vector__XXX

BO_ 2566843969 Engine_Coolant_Temperature: 8 VCU
 SG_ Engine_Coolant_Temperature : 0|8@1+ (1,-40) [-40|85] "deg.cel" Vector__XXX

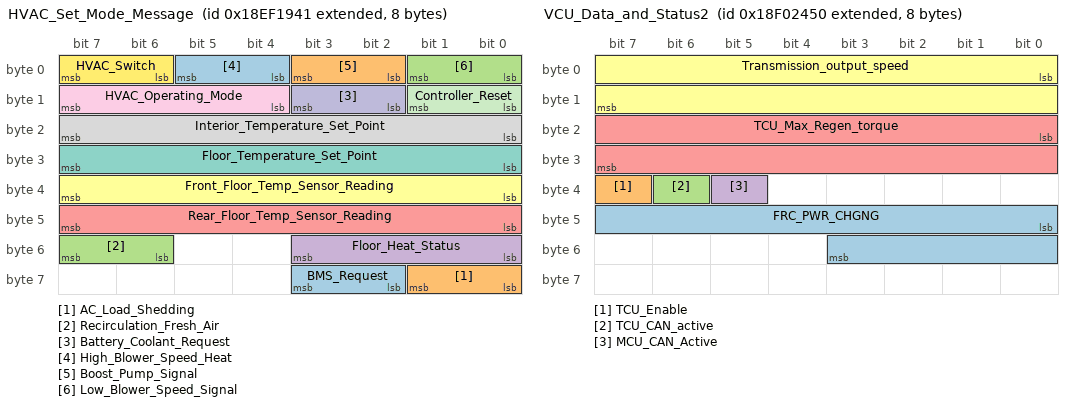
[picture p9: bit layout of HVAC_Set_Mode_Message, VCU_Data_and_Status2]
BO_ 2565806401 HVAC_Set_Mode_Message: 8 VCU
 SG_ BMS_Request : 58|2@1+ (1,0) [0|3] "" Vector__XXX
 SG_ AC_Load_Shedding : 56|2@1+ (1,0) [0|3] "" Vector__XXX
 SG_ Recirculation_Fresh_Air : 54|2@1+ (1,0) [0|3] "" Vector__XXX
 SG_ Floor_Heat_Status : 48|4@1+ (1,0) [0|15] "" Vector__XXX
 SG_ Rear_Floor_Temp_Sensor_Reading : 40|8@1+ (1,0) [17|28] "" Vector__XXX
 SG_ Front_Floor_Temp_Sensor_Reading : 32|8@1+ (1,0) [17|28] "" Vector__XXX
 SG_ Floor_Temperature_Set_Point : 24|8@1+ (1,0) [17|28] "" Vector__XXX
 SG_ Interior_Temperature_Set_Point : 16|8@1+ (1,0) [17|28] "" Vector__XXX
 SG_ HVAC_Operating_Mode : 12|4@1+ (1,0) [0|15] "" Vector__XXX
 SG_ Battery_Coolant_Request : 10|2@1+ (1,0) [0|3] "" Vector__XXX
 SG_ Controller_Reset : 8|2@1+ (1,0) [0|3] "" Vector__XXX
 SG_ HVAC_Switch : 6|2@1+ (1,0) [0|3] "" Vector__XXX
 SG_ High_Blower_Speed_Heat : 4|2@1+ (1,0) [0|3] "" Vector__XXX
 SG_ Boost_Pump_Signal : 2|2@1+ (1,0) [0|3] "" Vector__XXX
 SG_ Low_Blower_Speed_Signal : 0|2@1+ (1,0) [0|3] "" Vector__XXX

BO_ 2565874768 VCU_Data_and_Status2: 8 VCU
 SG_ FRC_PWR_CHGNG : 40|12@1+ (300,0) [0|1228200] "W" Vector__XXX
 SG_ TCU_Enable : 39|1@1+ (1,0) [0|1] "Boolean" Vector__XXX
 SG_ TCU_CAN_active : 38|1@1+ (1,0) [0|1] "Boolean" Vector__XXX
 SG_ MCU_CAN_Active : 37|1@1+ (1,0) [0|1] "Boolean" Vector__XXX
 SG_ TCU_Max_Regen_torque : 16|16@1+ (0.1,0) [0|6425.6] "Nm" Vector__XXX
 SG_ Transmission_output_speed : 0|16@1- (1,0) [-16384|16384] "rpm" Vector__XXX

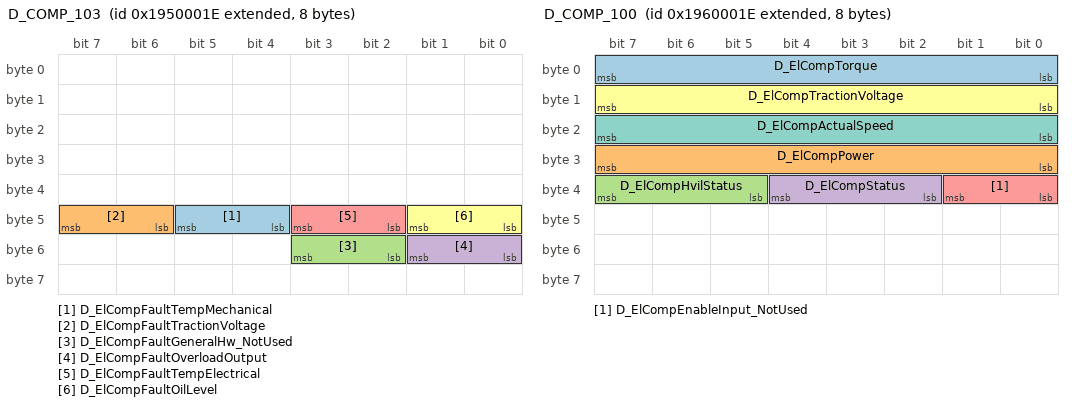
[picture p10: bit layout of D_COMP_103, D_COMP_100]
BO_ 2572156958 D_COMP_103: 8 Compressor_HPP
 SG_ D_ElCompFaultTempMechanical : 44|2@1+ (1,0) [0|3] "" Vector__XXX
 SG_ D_ElCompFaultTractionVoltage : 46|2@1+ (1,0) [0|3] "" Vector__XXX
 SG_ D_ElCompFaultGeneralHw_NotUsed : 50|2@1+ (1,0) [0|3] "" Vector__XXX
 SG_ D_ElCompFaultOverloadOutput : 48|2@1+ (1,0) [0|3] "" Vector__XXX
 SG_ D_ElCompFaultTempElectrical : 42|2@1+ (1,0) [0|3] "" Vector__XXX
 SG_ D_ElCompFaultOilLevel : 40|2@1+ (1,0) [0|3] "" Vector__XXX

BO_ 2573205534 D_COMP_100: 8 Compressor_HPP
 SG_ D_ElCompTorque : 0|8@1+ (0.2,0) [0|50] "Nm" Vector__XXX
 SG_ D_ElCompPower : 24|8@1+ (0.1,0) [0|25] "KW" Vector__XXX
 SG_ D_ElCompHvilStatus : 37|3@1+ (1,0) [0|7] "" Vector__XXX
 SG_ D_ElCompStatus : 34|3@1+ (1,0) [0|7] "" Vector__XXX
 SG_ D_ElCompEnableInput_NotUsed : 32|2@1+ (1,0) [0|3] "" Vector__XXX
 SG_ D_ElCompTractionVoltage : 8|8@1+ (4,0) [0|1000] "V" Vector__XXX
 SG_ D_ElCompActualSpeed : 16|8@1+ (20,0) [0|5000] "rpm" Vector__XXX

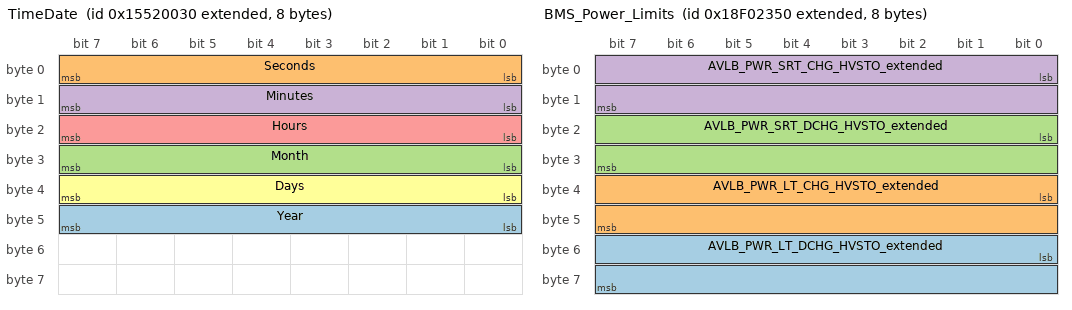
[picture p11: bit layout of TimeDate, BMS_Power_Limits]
BO_ 2505179184 TimeDate: 8 VCU
 SG_ Year : 40|8@1+ (1,1985) [1985|2235] "yrs" Vector__XXX
 SG_ Seconds : 0|8@1+ (0.25,0) [0|59.75] "sec" Vector__XXX
 SG_ Month : 24|8@1+ (1,0) [1|12] "month" Vector__XXX
 SG_ Minutes : 8|8@1+ (1,0) [0|59] "min" Vector__XXX
 SG_ Hours : 16|8@1+ (1,0) [0|23] "hr" Vector__XXX
 SG_ Days : 32|8@1- (0.25,0) [0.25|31.75] "days" Vector__XXX

BO_ 2506227760 D_CECU_103: 8 VCU
 SG_ D_ElCompSetSpeed : 0|8@1+ (20,0) [0|5000] "rpm" Vector__XXX
 SG_ D_ElCompAllowedCurrent : 8|16@1+ (0.05,0) [0|1600] "A" Vector__XXX

BO_ 2565874512 BMS_Power_Limits: 8 VCU
 SG_ AVLB_PWR_LT_DCHG_HVSTO_extended : 48|16@1+ (40,-2621280) [-2621280|2621280] "W" Vector__XXX
 SG_ AVLB_PWR_LT_CHG_HVSTO_extended : 32|16@1+ (40,0) [0|2621280] "W" Vector__XXX
 SG_ AVLB_PWR_SRT_DCHG_HVSTO_extended : 16|16@1+ (40,-2621280) [-2621280|2621280] "W" Vector__XXX
 SG_ AVLB_PWR_SRT_CHG_HVSTO_extended : 0|16@1+ (40,0) [0|2621280] "W" Vector__XXX

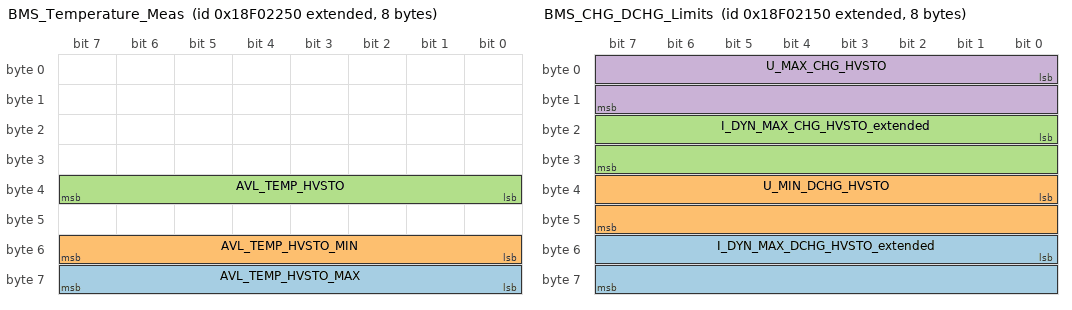
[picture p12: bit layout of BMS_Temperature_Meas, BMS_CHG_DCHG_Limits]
BO_ 2565874256 BMS_Temperature_Meas: 8 VCU
 SG_ AVL_TEMP_HVSTO_MAX : 56|8@1+ (1,-50) [-50|202] "°C" Vector__XXX
 SG_ AVL_TEMP_HVSTO_MIN : 48|8@1+ (1,-50) [-50|202] "°C" Vector__XXX
 SG_ AVL_TEMP_HVSTO : 32|8@1+ (1,-50) [-50|204] "°C" Vector__XXX

BO_ 2565874000 BMS_CHG_DCHG_Limits: 8 VCU
 SG_ I_DYN_MAX_DCHG_HVSTO_extended : 48|16@1+ (0.2,-6553) [-6553|6553] "A" Vector__XXX
 SG_ U_MIN_DCHG_HVSTO : 32|16@1+ (0.1,0) [0|819] "V" Vector__XXX
 SG_ I_DYN_MAX_CHG_HVSTO_extended : 16|16@1+ (0.2,-6553) [-6553|6553] "A" Vector__XXX
 SG_ U_MAX_CHG_HVSTO : 0|16@1+ (0.1,0) [0|819] "V" Vector__XXX

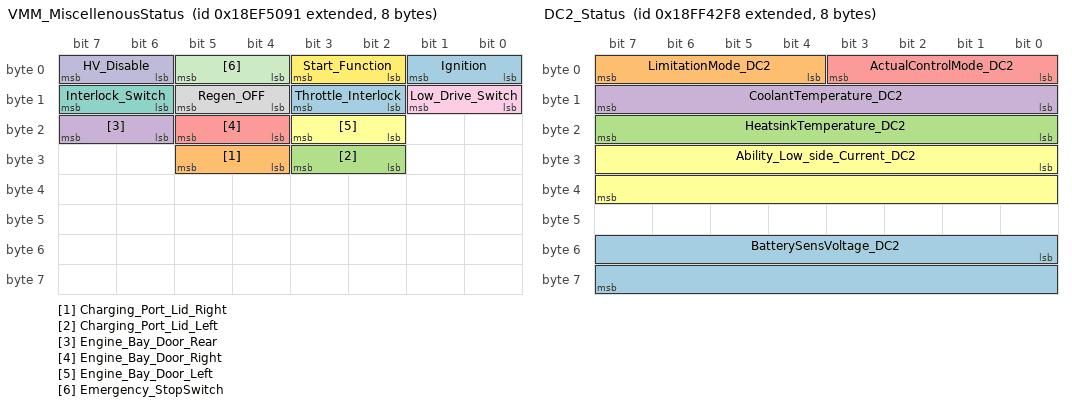
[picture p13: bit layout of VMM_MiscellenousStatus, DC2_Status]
BO_ 2565820561 VMM_MiscellenousStatus: 8 Praker_GW
 SG_ Throttle_Interlock : 10|2@1+ (1,0) [0|3] "" Vector__XXX
 SG_ Charging_Port_Lid_Right : 28|2@1+ (1,0) [0|3] "" Vector__XXX
 SG_ Charging_Port_Lid_Left : 26|2@1+ (1,0) [0|3] "" Vector__XXX
 SG_ Engine_Bay_Door_Rear : 22|2@1+ (1,0) [0|3] "" Vector__XXX
 SG_ Engine_Bay_Door_Right : 20|2@1+ (1,0) [0|3] "" Vector__XXX
 SG_ Engine_Bay_Door_Left : 18|2@1+ (1,0) [0|3] "" Vector__XXX
 SG_ Interlock_Switch : 14|2@1+ (1,0) [0|3] "" Vector__XXX
 SG_ Regen_OFF : 12|2@1+ (1,0) [0|3] "" Vector__XXX
 SG_ Low_Drive_Switch : 8|2@1+ (1,0) [0|3] "" Vector__XXX
 SG_ HV_Disable : 6|2@1+ (1,0) [0|3] "" Vector__XXX
 SG_ Emergency_StopSwitch : 4|2@1+ (1,0) [0|3] "" Vector__XXX
 SG_ Start_Function : 2|2@1+ (1,0) [0|3] "" Vector__XXX
 SG_ Ignition : 0|2@1+ (1,0) [0|3] "" Vector__XXX

BO_ 2566865656 DC2_Status: 8 DCDC_Inmotion_DC2
 SG_ BatterySensVoltage_DC2 : 48|16@1+ (0.05,0) [0|3212.7] "volts" Vector__XXX
 SG_ LimitationMode_DC2 : 4|4@1+ (1,0) [0|15] "" Vector__XXX
 SG_ HeatsinkTemperature_DC2 : 16|8@1+ (1,-40) [-40|209] "deg. Cel" Vector__XXX
 SG_ CoolantTemperature_DC2 : 8|8@1+ (1,-40) [-40|209] "Deg cel" Vector__XXX
 SG_ ActualControlMode_DC2 : 0|4@1+ (1,0) [0|15] "" Vector__XXX
 SG_ Ability_Low_side_Current_DC2 : 24|16@1+ (0.05,0) [0|3212.7] "A" Vector__XXX

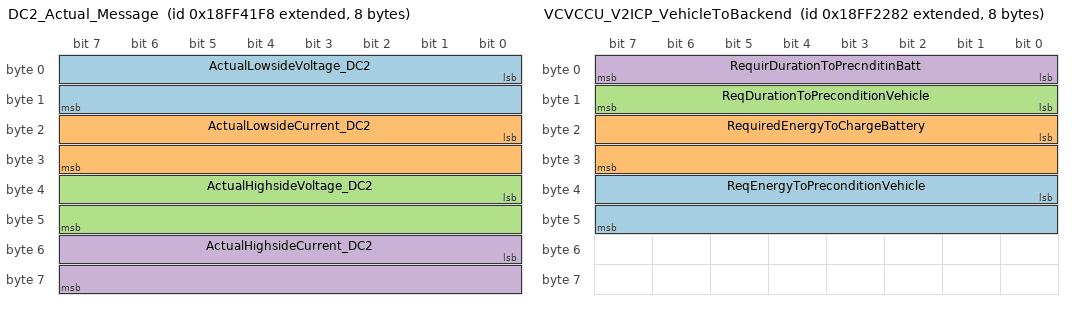
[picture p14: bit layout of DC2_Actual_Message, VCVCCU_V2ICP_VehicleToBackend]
BO_ 2566865400 DC2_Actual_Message: 8 DCDC_Inmotion_DC2
 SG_ ActualLowsideVoltage_DC2 : 0|16@1+ (0.05,0) [0|3212.75] "volts" Vector__XXX
 SG_ ActualLowsideCurrent_DC2 : 16|16@1+ (0.05,-1600) [-1600|3212.7] "Amps" Vector__XXX
 SG_ ActualHighsideVoltage_DC2 : 32|16@1+ (0.05,0) [0|3212.75] "volts" Vector__XXX
 SG_ ActualHighsideCurrent_DC2 : 48|16@1+ (0.05,-1600) [-1600|3212.7] "Amps" Vector__XXX

BO_ 2349072126 PGN_Faault_message: 8 Vector__XXX
 SG_ Fault_bits : 0|64@1+ (1,0) [0|1.84467440737096E+019] "" Vector__XXX

BO_ 2349006590 PGN_65348_Faults_Message: 8 Vector__XXX

BO_ 2149121859 Reference_Message: 8 Vector__XXX
 SG_ ReferenceLosideCurrent : 16|16@1+ (1,-1600) [-1600|1612.75] "A" Vector__XXX
 SG_ Reference_Low_side_Voltage : 0|16@1+ (0.05,-1600) [-1600|1612.75] "" Vector__XXX

BO_ 2566857346 VCVCCU_V2ICP_VehicleToBackend: 8 VCU
 SG_ ReqEnergyToPreconditionVehicle : 32|16@1+ (1,0) [0|1000] "KWh" Vector__XXX
 SG_ RequiredEnergyToChargeBattery : 16|16@1+ (1,0) [0|1000] "Kwh" Vector__XXX
 SG_ ReqDurationToPreconditionVehicle : 8|8@1+ (1,0) [0|250] "min" Vector__XXX
 SG_ RequirDurationToPrecnditinBatt : 0|8@1+ (1,0) [0|250] "min" Vector__XXX

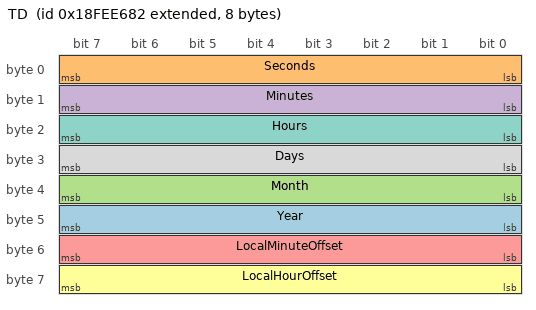
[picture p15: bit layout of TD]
BO_ 2566841986 TD: 8 VCU
 SG_ Year : 40|8@1+ (1,1985) [1985|2235] "yrs" Vector__XXX
 SG_ Seconds : 0|8@1+ (0.25,0) [0|59.75] "sec" Vector__XXX
 SG_ Month : 32|8@1+ (1,0) [1|12] "month" Vector__XXX
 SG_ Minutes : 8|8@1+ (1,0) [0|59] "min" Vector__XXX
 SG_ LocalMinuteOffset : 48|8@1+ (1,-125) [-59|59] "min" Vector__XXX
 SG_ LocalHourOffset : 56|8@1+ (1,-125) [-23|23] "" Vector__XXX
 SG_ Hours : 16|8@1+ (1,0) [0|23] "hr" Vector__XXX
 SG_ Days : 24|8@1- (0.25,0) [0.25|31.75] "days" Vector__XXX

BO_ 2566840450 VD: 8 VCU
 SG_ TripDistance : 32|32@1+ (0.125,0) [0|536870911.875] "" Vector__XXX
 SG_ TotalVehicleDistance : 0|32@1+ (0.125,0) [0|536870911.875] "Km" Vector__XXX

BO_ 2566910082 XCP_REQ_VCVCCU: 8 VCU
 SG_ XCP_REQ_VCCU : 0|64@1+ (1,0) [0|1.84467440737096E+019] "" Vector__XXX

CM_ "J1939 messages without part -7x";
CM_ BO_ 3221225472 "This is a message for not used signals, created by Vector CANdb++ DBC OLE DB Provider.";
BA_DEF_ BO_  "GenMsgSendType39" ENUM  "Zyklisch","Ereignisgesteuert","Auf Anfrage","dummy";
BA_DEF_ BO_  "GenMsgSendType38" ENUM  "Zyklisch","Ereignisgesteuert","Auf Anfrage","dummy";
BA_DEF_ BO_  "GenMsgSendType37" ENUM  "Zyklisch","Ereignisgesteuert","Auf Anfrage","dummy";
BA_DEF_ BO_  "GenMsgSendType36" ENUM  "Zyklisch","Ereignisgesteuert","Auf Anfrage","dummy";
BA_DEF_ BO_  "GenMsgSendType35" ENUM  "Zyklisch","Ereignisgesteuert","Auf Anfrage","dummy";
BA_DEF_ BO_  "GenMsgSendType34" ENUM  "Zyklisch","Ereignisgesteuert","Auf Anfrage","dummy";
BA_DEF_ BO_  "GenMsgSendType33" ENUM  "Zyklisch","Ereignisgesteuert","Auf Anfrage","dummy";
BA_DEF_ BO_  "GenMsgSendType32" ENUM  "Zyklisch","Ereignisgesteuert","Auf Anfrage","dummy";
BA_DEF_ BO_  "GenMsgSendType31" ENUM  "Zyklisch","Ereignisgesteuert","Auf Anfrage","dummy";
BA_DEF_ BO_  "GenMsgSendType30" ENUM  "Zyklisch","Ereignisgesteuert","Auf Anfrage","dummy";
BA_DEF_ BO_  "GenMsgSendType29" ENUM  "Zyklisch","Ereignisgesteuert","Auf Anfrage","dummy";
BA_DEF_ BO_  "GenMsgSendType28" ENUM  "Zyklisch","Ereignisgesteuert","Auf Anfrage","dummy";
BA_DEF_ BO_  "GenMsgSendType27" ENUM  "Zyklisch","Ereignisgesteuert","Auf Anfrage","dummy";
BA_DEF_ BO_  "GenMsgSendType26" ENUM  "Zyklisch","Ereignisgesteuert","Auf Anfrage","dummy";
BA_DEF_ BO_  "GenMsgSendType25" ENUM  "Zyklisch","Ereignisgesteuert","Auf Anfrage","dummy";
BA_DEF_ BO_  "GenMsgSendType24" ENUM  "Zyklisch","Ereignisgesteuert","Auf Anfrage","dummy";
BA_DEF_ BO_  "GenMsgSendType23" ENUM  "Zyklisch","Ereignisgesteuert","Auf Anfrage","dummy";
BA_DEF_ BO_  "GenMsgSendType22" ENUM  "Zyklisch","Ereignisgesteuert","Auf Anfrage","dummy";
BA_DEF_ BO_  "GenMsgSendType21" ENUM  "Zyklisch","Ereignisgesteuert","Auf Anfrage","dummy";
BA_DEF_ BO_  "GenMsgSendType20" ENUM  "Zyklisch","Ereignisgesteuert","Auf Anfrage","dummy";
BA_DEF_ BO_  "GenMsgSendType19" ENUM  "Zyklisch","Ereignisgesteuert","Auf Anfrage","dummy";
BA_DEF_ BO_  "GenMsgSendType18" ENUM  "Zyklisch","Ereignisgesteuert","Auf Anfrage","dummy";
BA_DEF_ BO_  "GenMsgSendType17" ENUM  "Zyklisch","Ereignisgesteuert","Auf Anfrage","dummy";
BA_DEF_ BO_  "GenMsgSendType16" ENUM  "Zyklisch","Ereignisgesteuert","Auf Anfrage","dummy";
BA_DEF_ BO_  "GenMsgSendType15" ENUM  "Zyklisch","Ereignisgesteuert","Auf Anfrage","dummy";
BA_DEF_ BO_  "GenMsgSendType14" ENUM  "Zyklisch","Ereignisgesteuert","Auf Anfrage","dummy";
BA_DEF_ BO_  "GenMsgSendType13" ENUM  "Zyklisch","Ereignisgesteuert","Auf Anfrage","dummy";
BA_DEF_ BO_  "GenMsgSendType12" ENUM  "Zyklisch","Ereignisgesteuert","Auf Anfrage","dummy";
BA_DEF_ BO_  "GenMsgSendType11" ENUM  "Zyklisch","Ereignisgesteuert","Auf Anfrage","dummy";
BA_DEF_ BO_  "GenMsgSendType10" ENUM  "Zyklisch","Ereignisgesteuert","Auf Anfrage","dummy";
BA_DEF_ BO_  "GenMsgSendType9" ENUM  "Zyklisch","Ereignisgesteuert","Auf Anfrage","dummy";
BA_DEF_ BO_  "GenMsgSendType8" ENUM  "Zyklisch","Ereignisgesteuert","Auf Anfrage","dummy";
BA_DEF_ BO_  "GenMsgSendType7" ENUM  "Zyklisch","Ereignisgesteuert","Auf Anfrage","dummy";
BA_DEF_ BO_  "GenMsgSendType6" ENUM  "Zyklisch","Ereignisgesteuert","Auf Anfrage","dummy";
BA_DEF_ BO_  "GenMsgSendType5" ENUM  "Zyklisch","Ereignisgesteuert","Auf Anfrage","dummy";
BA_DEF_ BO_  "GenMsgSendType4" ENUM  "Zyklisch","Ereignisgesteuert","Auf Anfrage","dummy";
BA_DEF_ BO_  "GenMsgSendType3" ENUM  "Zyklisch","Ereignisgesteuert","Auf Anfrage","dummy";
BA_DEF_ BO_  "GenMsgSendType2" ENUM  "Zyklisch","Ereignisgesteuert","Auf Anfrage","dummy";
BA_DEF_ BU_  "NmAsrCanMsgReducedTime" INT 0 65535;
BA_DEF_ BU_  "MessageManagerUsed" ENUM  "no","yes";
BA_DEF_  "Manufacturer_ALT" ENUM  "BMWAG";
BA_DEF_  "NmType" STRING ;
BA_DEF_  "NmAsrMessageCount" INT 1 255;
BA_DEF_  "NmAsrBaseAddress" HEX 0 2047;
BA_DEF_  "NmAsrCanMsgTxTimeoutTime" INT 0 65535;
BA_DEF_  "NmAsrCanMsgCycleTime" INT 0 65535;
BA_DEF_  "NmAsrRepeatMessageTime" INT 0 65535;
BA_DEF_  "NmAsrWaitBusSleepTime" INT 0 65535;
BA_DEF_  "NmAsrTimeoutTime" INT 0 65535;
BA_DEF_  "Manufacturer" ENUM  "DBAG","VAG","BMWAG";
BA_DEF_  "DBName" STRING ;
BA_DEF_ SG_  "SigType" ENUM  "Default","Range","RangeSigned","ASCII","Discrete","Control","ReferencePGN","DTC","StringDelimiter","StringLength","StringLengthControl","MessageCounter","MessageChecksum";
BA_DEF_ SG_  "GenSigStartValue" INT 0 2147483647;
BA_DEF_ SG_  "GenSigSendType" ENUM  "Cyclic","OnWrite","OnWriteWithRepetition","OnChange","OnChangeWithRepetition","IfActive","IfActiveWithRepetition","NoSigSendType";
BA_DEF_ SG_  "GenSigILSupport" ENUM  "No","Yes";
BA_DEF_ SG_  "GenSigEVName" STRING ;
BA_DEF_ BO_  "GenMsgStartDelayTime" INT 0 100000;
BA_DEF_ BO_  "GenMsgILSupport" ENUM  "No","Yes";
BA_DEF_ BO_  "GenMsgRequestable" INT 0 1;
BA_DEF_ BO_  "GenMsgSendType" ENUM  "cyclic","NotUsed","NotUsed","NotUsed","NotUsed","NotUsed","NotUsed","IfActive","noMsgSendType";
BA_DEF_ BO_  "VFrameFormat" ENUM  "StandardCAN","ExtendedCAN","reserved","J1939PG";
BA_DEF_ BO_  "GenMsgCycleTime" INT 0 3600000;
BA_DEF_ BU_  "NmStationAddress" INT 0 255;
BA_DEF_  "SAE_J1939_DA_SpecVersion" STRING ;
BA_DEF_  "SAE_J1939_81_SpecVersion" STRING ;
BA_DEF_  "DatabaseVersion" STRING ;
BA_DEF_  "BusType" STRING ;
BA_DEF_  "ProtocolType" STRING ;
BA_DEF_  "SAE_J1939_21_SpecVersion" STRING ;
BA_DEF_DEF_  "GenMsgSendType39" "Zyklisch";
BA_DEF_DEF_  "GenMsgSendType38" "Zyklisch";
BA_DEF_DEF_  "GenMsgSendType37" "Zyklisch";
BA_DEF_DEF_  "GenMsgSendType36" "Zyklisch";
BA_DEF_DEF_  "GenMsgSendType35" "Zyklisch";
BA_DEF_DEF_  "GenMsgSendType34" "Zyklisch";
BA_DEF_DEF_  "GenMsgSendType33" "Zyklisch";
BA_DEF_DEF_  "GenMsgSendType32" "Zyklisch";
BA_DEF_DEF_  "GenMsgSendType31" "Zyklisch";
BA_DEF_DEF_  "GenMsgSendType30" "Zyklisch";
BA_DEF_DEF_  "GenMsgSendType29" "Zyklisch";
BA_DEF_DEF_  "GenMsgSendType28" "Zyklisch";
BA_DEF_DEF_  "GenMsgSendType27" "Zyklisch";
BA_DEF_DEF_  "GenMsgSendType26" "Zyklisch";
BA_DEF_DEF_  "GenMsgSendType25" "Zyklisch";
BA_DEF_DEF_  "GenMsgSendType24" "Zyklisch";
BA_DEF_DEF_  "GenMsgSendType23" "Zyklisch";
BA_DEF_DEF_  "GenMsgSendType22" "Zyklisch";
BA_DEF_DEF_  "GenMsgSendType21" "Zyklisch";
BA_DEF_DEF_  "GenMsgSendType20" "Zyklisch";
BA_DEF_DEF_  "GenMsgSendType19" "Zyklisch";
BA_DEF_DEF_  "GenMsgSendType18" "Zyklisch";
BA_DEF_DEF_  "GenMsgSendType17" "Zyklisch";
BA_DEF_DEF_  "GenMsgSendType16" "Zyklisch";
BA_DEF_DEF_  "GenMsgSendType15" "Zyklisch";
BA_DEF_DEF_  "GenMsgSendType14" "Zyklisch";
BA_DEF_DEF_  "GenMsgSendType13" "Zyklisch";
BA_DEF_DEF_  "GenMsgSendType12" "Zyklisch";
BA_DEF_DEF_  "GenMsgSendType11" "Zyklisch";
BA_DEF_DEF_  "GenMsgSendType10" "Zyklisch";
BA_DEF_DEF_  "GenMsgSendType9" "Zyklisch";
BA_DEF_DEF_  "GenMsgSendType8" "Zyklisch";
BA_DEF_DEF_  "GenMsgSendType7" "Zyklisch";
BA_DEF_DEF_  "GenMsgSendType6" "Zyklisch";
BA_DEF_DEF_  "GenMsgSendType5" "Zyklisch";
BA_DEF_DEF_  "GenMsgSendType4" "Zyklisch";
BA_DEF_DEF_  "GenMsgSendType3" "Zyklisch";
BA_DEF_DEF_  "GenMsgSendType2" "Zyklisch";
BA_DEF_DEF_  "NmAsrCanMsgReducedTime" 640;
BA_DEF_DEF_  "MessageManagerUsed" "yes";
BA_DEF_DEF_  "Manufacturer_ALT" "BMWAG";
BA_DEF_DEF_  "NmType" "NmAsr";
BA_DEF_DEF_  "NmAsrMessageCount" 128;
BA_DEF_DEF_  "NmAsrBaseAddress" 1280;
BA_DEF_DEF_  "NmAsrCanMsgTxTimeoutTime" 1920;
BA_DEF_DEF_  "NmAsrCanMsgCycleTime" 640;
BA_DEF_DEF_  "NmAsrRepeatMessageTime" 3200;
BA_DEF_DEF_  "NmAsrWaitBusSleepTime" 1500;
BA_DEF_DEF_  "NmAsrTimeoutTime" 2000;
BA_DEF_DEF_  "Manufacturer" "BMWAG";
BA_DEF_DEF_  "DBName" "";
BA_DEF_DEF_  "SigType" "Default";
BA_DEF_DEF_  "GenSigStartValue" 0;
BA_DEF_DEF_  "GenSigSendType" "NoSigSendType";
BA_DEF_DEF_  "GenSigILSupport" "Yes";
BA_DEF_DEF_  "GenSigEVName" "Env@Nodename_@Signame";
BA_DEF_DEF_  "GenMsgStartDelayTime" 0;
BA_DEF_DEF_  "GenMsgILSupport" "Yes";
BA_DEF_DEF_  "GenMsgRequestable" 1;
BA_DEF_DEF_  "GenMsgSendType" "noMsgSendType";
BA_DEF_DEF_  "VFrameFormat" "J1939PG";
BA_DEF_DEF_  "GenMsgCycleTime" 0;
BA_DEF_DEF_  "NmStationAddress" 254;
BA_DEF_DEF_  "SAE_J1939_DA_SpecVersion" "";
BA_DEF_DEF_  "SAE_J1939_81_SpecVersion" "";
BA_DEF_DEF_  "DatabaseVersion" "";
BA_DEF_DEF_  "BusType" "";
BA_DEF_DEF_  "ProtocolType" "";
BA_DEF_DEF_  "SAE_J1939_21_SpecVersion" "";
BA_ "SAE_J1939_DA_SpecVersion" "2018-02";
BA_ "SAE_J1939_81_SpecVersion" "2017-03";
BA_ "DatabaseVersion" "10.0";
BA_ "BusType" "CAN";
BA_ "ProtocolType" "J1939";
BA_ "SAE_J1939_21_SpecVersion" "2016-03";
BA_ "DBName" "GW_Vincity";
BA_ "NmStationAddress" BU_ PKP_PRND_Keypad 33;
BA_ "NmStationAddress" BU_ HVAC 25;
BA_ "NmStationAddress" BU_ Compressor_HPP 30;
BA_ "NmStationAddress" BU_ DCDC_Inmotion_DC2 248;
BA_ "NmStationAddress" BU_ SME 1;
BA_ "NmStationAddress" BU_ VCCU 128;
BA_ "NmStationAddress" BU_ SME_4 0;
BA_ "NmStationAddress" BU_ SME_3 0;
BA_ "NmStationAddress" BU_ SME_2 0;
BA_ "NmStationAddress" BU_ SME_1 0;
BA_ "NmStationAddress" BU_ Diag_Tester 0;
BA_ "NmStationAddress" BU_ DCDC_inmotion_DC1 246;
BA_ "NmStationAddress" BU_ TCU 2;
BA_ "NmStationAddress" BU_ Praker_GW 145;
BA_ "NmStationAddress" BU_ OBC_Dilong 229;
BA_ "NmStationAddress" BU_ DCDC_Dilong 112;
BA_ "NmStationAddress" BU_ VCU 80;
BA_ "GenMsgSendType" BO_ 2565875024 0;
BA_ "GenMsgCycleTime" BO_ 2565875024 100;
BA_ "GenMsgCycleTime" BO_ 2349465342 10;
BA_ "GenMsgSendType" BO_ 2349465342 0;
BA_ "GenMsgCycleTime" BO_ 2349203198 100;
BA_ "GenMsgSendType" BO_ 2349203198 0;
BA_ "GenMsgCycleTime" BO_ 2364600071 10;
BA_ "GenMsgSendType" BO_ 2364600071 0;
BA_ "GenMsgCycleTime" BO_ 2364600068 10;
BA_ "GenMsgSendType" BO_ 2364600068 0;
BA_ "GenMsgCycleTime" BO_ 2364600067 10;
BA_ "GenMsgSendType" BO_ 2364600067 0;
BA_ "GenMsgCycleTime" BO_ 2364600070 10;
BA_ "GenMsgSendType" BO_ 2364600070 0;
BA_ "GenMsgCycleTime" BO_ 2364600069 100;
BA_ "GenMsgSendType" BO_ 2364600069 0;
BA_ "GenMsgSendType" BO_ 2566866168 0;
BA_ "GenMsgCycleTime" BO_ 2566866168 1000;
BA_ "GenMsgCycleTime" BO_ 2566866166 100;
BA_ "GenMsgSendType" BO_ 2566866166 0;
BA_ "GenMsgCycleTime" BO_ 2364600066 20;
BA_ "GenMsgSendType" BO_ 2364600066 0;
BA_ "GenMsgCycleTime" BO_ 2364600065 20;
BA_ "GenMsgSendType" BO_ 2364600065 0;
BA_ "GenMsgCycleTime" BO_ 2632843522 50;
BA_ "GenMsgSendType" BO_ 2632843522 0;
BA_ "GenMsgCycleTime" BO_ 2565734658 50;
BA_ "GenMsgSendType" BO_ 2565734658 0;
BA_ "GenMsgCycleTime" BO_ 2498625794 50;
BA_ "GenMsgSendType" BO_ 2498625794 0;
BA_ "GenMsgCycleTime" BO_ 2431516930 50;
BA_ "GenMsgSendType" BO_ 2431516930 0;
BA_ "GenMsgCycleTime" BO_ 2364408066 50;
BA_ "GenMsgSendType" BO_ 2364408066 0;
BA_ "GenMsgCycleTime" BO_ 2297299202 50;
BA_ "GenMsgSendType" BO_ 2297299202 0;
BA_ "GenMsgCycleTime" BO_ 2230190338 50;
BA_ "GenMsgSendType" BO_ 2230190338 0;
BA_ "GenMsgCycleTime" BO_ 2297299457 50;
BA_ "GenMsgSendType" BO_ 2297299457 0;
BA_ "GenMsgCycleTime" BO_ 2230190593 50;
BA_ "GenMsgSendType" BO_ 2230190593 0;
BA_ "GenMsgSendType" BO_ 2565865873 0;
BA_ "GenMsgCycleTime" BO_ 2565865873 100;
BA_ "GenMsgSendType" BO_ 2565603097 0;
BA_ "GenMsgCycleTime" BO_ 2565603097 1000;
BA_ "GenMsgSendType" BO_ 2565668633 0;
BA_ "GenMsgCycleTime" BO_ 2565668633 1000;
BA_ "GenMsgSendType" BO_ 2566834713 0;
BA_ "GenMsgCycleTime" BO_ 2566834713 1000;
BA_ "GenMsgCycleTime" BO_ 2566905369 1000;
BA_ "GenMsgSendType" BO_ 2566905369 0;
BA_ "GenMsgCycleTime" BO_ 2566905113 1000;
BA_ "GenMsgSendType" BO_ 2566905113 0;
BA_ "GenMsgSendType" BO_ 2566906137 0;
BA_ "GenMsgCycleTime" BO_ 2566906137 1000;
BA_ "GenMsgSendType" BO_ 2566843969 0;
BA_ "GenMsgCycleTime" BO_ 2566843969 1000;
BA_ "GenMsgSendType" BO_ 2565806401 0;
BA_ "GenMsgCycleTime" BO_ 2565806401 1000;
BA_ "GenMsgCycleTime" BO_ 2565874768 100;
BA_ "GenMsgSendType" BO_ 2565874768 0;
BA_ "GenMsgCycleTime" BO_ 2572156958 100;
BA_ "GenMsgSendType" BO_ 2572156958 0;
BA_ "GenMsgCycleTime" BO_ 2573205534 100;
BA_ "GenMsgSendType" BO_ 2573205534 0;
BA_ "GenMsgCycleTime" BO_ 2505179184 1000;
BA_ "GenMsgSendType" BO_ 2505179184 0;
BA_ "GenMsgCycleTime" BO_ 2506227760 500;
BA_ "GenMsgSendType" BO_ 2506227760 0;
BA_ "GenMsgCycleTime" BO_ 2565874512 1000;
BA_ "GenMsgSendType" BO_ 2565874512 0;
BA_ "GenMsgCycleTime" BO_ 2565874256 1000;
BA_ "GenMsgSendType" BO_ 2565874256 0;
BA_ "GenMsgCycleTime" BO_ 2565874000 100;
BA_ "GenMsgSendType" BO_ 2565874000 0;
BA_ "GenMsgSendType" BO_ 2565820561 0;
BA_ "GenMsgCycleTime" BO_ 2565820561 100;
BA_ "GenMsgCycleTime" BO_ 2566865656 100;
BA_ "GenMsgSendType" BO_ 2566865656 0;
BA_ "GenMsgCycleTime" BO_ 2566865400 10;
BA_ "GenMsgSendType" BO_ 2566865400 0;
BA_ "GenMsgSendType" BO_ 2349072126 0;
BA_ "GenMsgCycleTime" BO_ 2349072126 1000;
BA_ "GenMsgSendType" BO_ 2149121859 0;
BA_ "GenMsgCycleTime" BO_ 2149121859 1000;
BA_ "GenMsgSendType" BO_ 2566857346 0;
BA_ "GenMsgCycleTime" BO_ 2566857346 1000;
BA_ "GenMsgSendType" BO_ 2566841986 0;
BA_ "GenMsgCycleTime" BO_ 2566841986 1000;
BA_ "GenMsgSendType" BO_ 2566840450 0;
BA_ "GenMsgCycleTime" BO_ 2566840450 100;
BA_ "GenSigStartValue" SG_ 3221225472 VCVCCU_V2G_EVSEMaxVltgLimitFlag 3;
BA_ "GenSigStartValue" SG_ 3221225472 Reserved_2 255;
BA_ "GenSigStartValue" SG_ 3221225472 Reserved_3 255;
BA_ "GenSigStartValue" SG_ 3221225472 Reserved_7 255;
BA_ "GenSigStartValue" SG_ 3221225472 Reserved_5 255;
BA_ "GenSigStartValue" SG_ 3221225472 Reserved_4 255;
BA_ "GenSigStartValue" SG_ 3221225472 Reserved_1 255;
BA_ "GenSigStartValue" SG_ 3221225472 Reserved_0 255;
BA_ "GenSigStartValue" SG_ 3221225472 Reserved_6 255;
BA_ "GenSigStartValue" SG_ 2565808384 Keypad_identifier 33;
BA_ "GenSigStartValue" SG_ 2565808384 Heartbeat_period 0.5;
BA_ "GenSigStartValue" SG_ 2565808384 Periodic_state_transmission 1;
BA_ "GenSigStartValue" SG_ 2565808384 LED_brightness_level 63;
BA_ "GenSigStartValue" SG_ 2565808384 Key_message_period 1;
BA_ "GenSigStartValue" SG_ 2565808384 Key_LED_number 1;
BA_ "GenSigStartValue" SG_ 2565808384 Event_state_transmission 1;
BA_ "GenSigStartValue" SG_ 2565808384 CAN_source_address 33;
BA_ "GenSigStartValue" SG_ 2565808384 CAN_destination_address 255;
BA_ "GenSigStartValue" SG_ 2565808384 Baud_rate_setting 3.988;
BA_ "GenSigStartValue" SG_ 2565808384 Backlight_color 8;
BA_ "GenSigStartValue" SG_ 2565808384 Backlight_brightness_level 63;
BA_ "GenSigStartValue" SG_ 2565808384 RX_command_list 1;
BA_ "GenSigStartValue" SG_ 2565865249 TX_command_list 1;
BA_ "GenSigStartValue" SG_ 2565865249 Key_Number 1;
BA_ "GenSigStartValue" SG_ 2632843522 TCU_Lubricant_Temperature 40;
BA_ "GenSigStartValue" SG_ 2632843522 MCU_Inverter_Temperature 40;
BA_ "GenSigStartValue" SG_ 2632843522 MCU_Stator_Temperature 40;
BA_ "GenSigStartValue" SG_ 2632843522 MCU_Rotor_Temperature 40;
BA_ "GenSigStartValue" SG_ 2566905113 Zone_1_Return_air_temperature 40;
BA_ "GenSigStartValue" SG_ 2566905113 Set_point_temperature 40;
BA_ "GenSigStartValue" SG_ 2566905113 Discharge_air_temperature 40;
BA_ "GenSigStartValue" SG_ 2566905113 Coolant_temperature 40;
BA_ "GenSigStartValue" SG_ 2566905113 Zone_2_Return_air_temperature 40;
BA_ "GenSigStartValue" SG_ 2566905113 Ambient_Temperature 40;
BA_ "GenSigStartValue" SG_ 2566906137 Freeze_Temperature 40;
BA_ "GenSigStartValue" SG_ 2566843969 Engine_Coolant_Temperature 40;
BA_ "GenSigStartValue" SG_ 2565806401 Rear_Floor_Temp_Sensor_Reading 17;
BA_ "GenSigStartValue" SG_ 2565806401 Front_Floor_Temp_Sensor_Reading 17;
BA_ "GenSigStartValue" SG_ 2565806401 Floor_Temperature_Set_Point 17;
BA_ "GenSigStartValue" SG_ 2565806401 Interior_Temperature_Set_Point 17;
BA_ "GenSigStartValue" SG_ 2505179184 Month 1;
BA_ "GenSigStartValue" SG_ 2505179184 Days 1;
BA_ "GenSigStartValue" SG_ 2565874512 AVLB_PWR_LT_DCHG_HVSTO_extended 65532;
BA_ "GenSigStartValue" SG_ 2565874512 AVLB_PWR_SRT_DCHG_HVSTO_extended 65532;
BA_ "GenSigStartValue" SG_ 2565874256 AVL_TEMP_HVSTO_MAX 50;
BA_ "GenSigStartValue" SG_ 2565874256 AVL_TEMP_HVSTO_MIN 50;
BA_ "GenSigStartValue" SG_ 2565874256 AVL_TEMP_HVSTO 50;
BA_ "GenSigStartValue" SG_ 2565874000 I_DYN_MAX_DCHG_HVSTO_extended 32765;
BA_ "GenSigStartValue" SG_ 2565874000 I_DYN_MAX_CHG_HVSTO_extended 32765;
BA_ "GenSigStartValue" SG_ 2149121859 ReferenceLosideCurrent 1600;
BA_ "GenSigStartValue" SG_ 2149121859 Reference_Low_side_Voltage 32000;
BA_ "GenSigStartValue" SG_ 2566857346 ReqEnergyToPreconditionVehicle 65535;
BA_ "GenSigStartValue" SG_ 2566857346 RequiredEnergyToChargeBattery 65535;
BA_ "GenSigStartValue" SG_ 2566857346 ReqDurationToPreconditionVehicle 255;
BA_ "GenSigStartValue" SG_ 2566857346 RequirDurationToPrecnditinBatt 255;
BA_ "GenSigStartValue" SG_ 2566841986 Month 1;
BA_ "GenSigStartValue" SG_ 2566841986 LocalMinuteOffset 66;
BA_ "GenSigStartValue" SG_ 2566841986 LocalHourOffset 102;
BA_ "GenSigStartValue" SG_ 2566841986 Days 1;
VAL_ 3221225472 D_OBC_Charging_alarm 32 "0 normal 1 alarm" 16 "0 normal 1 alarm" 8 "0 normal 1 alarm" 4 "2 fault 3 no electic lock" 2 "0 unlock 1 lock" 1 "0 disconnect 1 HW close" ;
VAL_ 3221225472 ST_WARN_OTMP_HVSTO 3 "Signal Invalid" 2 "Active" 1 "Not Active" 0 "No statement possible" ;
VAL_ 3221225472 Limitation_Mode 15 "Error indicator" 14 "Not Available" 11 "External output voltage limit" 10 "Internal output voltage limit" 9 "External current limitation" 8 "High side current limitation" 7 "High side power limitation" 6 "coolant temp limitation" 5 "Power stage temp limitation" 4 "High input voltage limitation" 3 "low input voltage limitation" 2 "Event limitation" 1 "Maximum current limitatio" 0 "No Limitation" ;
VAL_ 3221225472 MCU_Errors 11 "MCU regen type Error" 10 "MCU stator over temp" 9 "MCU inverter fault" 8 "MCU stator over temp" 7 "MCU CAN Active" 6 "MCU inverter over temp" 5 " MCU over speed warning" 4 "MCU over speed alarm" 3 "MCU undervoltage alarm" 2 "MCU overvoltage alarm" 1 "MCU limp home mode " 0 "No error" ;
VAL_ 3221225472 TCU_Errors 6 " Transmission Temp Read Error" 5 "TransmissionTemperature Limiting" 4 "Transmission Temperature Error" 3 "Transmission Temperature Warning" 2 "TCU cmd MSG 2 watchdog timeout" 1 "TCU cmd MSG 1 watchdog timeout" 0 "No error" ;
VAL_ 3221225472 D_OBC_Status_flag 16 "0 com normal 1 com timeout" 8 "0 start state 1 off" 4 "0 normal 1 input volt error" 2 "0 normal 1 charg temp too high" 1 "0 normal 1 HW failure" ;
VAL_ 2565875024 BMS_PRD_DUR_CHGNG 65535 "signal_unfilled" 65534 "reserved_Error" 65533 "reserved_not_available" ;
VAL_ 2565808384 LED_secondary_color 9 "Description for the value '0x9'" 8 "Amber/Orange" 7 "White/Light_Blue" 6 "Magenta" 5 "Cyan" 4 "Yellow" 3 "Blue" 2 "Green" 1 "Red" 0 "off" ;
VAL_ 2565808384 LED_state 3 "Alternate_blink" 2 "Blink" 1 "On" 0 "Off" ;
VAL_ 2565808384 LED_color 9 "Yellow/Green" 8 "Amber/Orange" 7 "White/light_Blue" 6 "magenta" 5 "Cyan" 4 "Yellow" 3 "Blue" 2 "Green" 1 "red" 0 "OFF" ;
VAL_ 2565808384 Startup_LED_show 2 "Description for the value '0x2'" 1 "Complete_LED_Show" 0 "OFF" ;
VAL_ 2565808384 Startup_keys_message 1 "Command_Enabled" 0 "Command_Disabled" ;
VAL_ 2565808384 Periodic_state_transmission 1 "Description for the value '0x1'" 0 "Released" ;
VAL_ 2565808384 LED_acknowledgment_state 1 "command_enabled" 0 "command_Disabled" ;
VAL_ 2565808384 Key_LED_number 4 "Description for the value '0x4'" 3 "Key_LED3" 2 "Key_LED2" 1 "Key_LED1" ;
VAL_ 2565808384 Heartbeat_state 1 "command_enabled" 0 "command_Disabled" ;
VAL_ 2565808384 Event_state_transmission 1 "command_enabled" 0 "command_Disabled" ;
VAL_ 2565808384 DEMO_mode 1 "command_enabled" 0 "command_Disabled" ;
VAL_ 2565808384 Backlight_color 9 "Yellow/Green" 8 "Amber/Orange" 7 "White/light_blue" 6 "magenta" 5 "Cyan" 4 "Yellow" 3 "Blue" 2 "Green" 1 "Red" ;
VAL_ 2565808384 Address_claim_at_boot 1 "command_enabled" 0 "command_Disabled" ;
VAL_ 2565808384 RX_command_list 128 "Set_CANopen_protocol" 125 "Set_backlight_color" 124 "LED_dim_at_startup" 123 "Set_backlight_level_at_startup" 122 "Start_DEMO_mode" 119 "Periodic_key_message_period" 117 "Heartbeat" 116 "Address_claim_at_boot" 115 "LED_acknowledgment" 114 "Event_state_transmission" 113 "Periodic_state_transmission" 112 "Set_source_address" 111 "Baud_rate_setting" 110 "Set_destination_address" 52 "Set_startup_LED_show" 42 "Get_software_revision" 40 "Set_startup_keys_message" 3 "Set_backlight_level" 2 "Set_LED_brightness_level" 1 "LED_Command" ;
VAL_ 2565865249 LED_state 3 "Alternate_blink" 2 "Blink" 1 "on" 0 "off" ;
VAL_ 2565865249 TX_command_list 249 "Heart" 115 "LED_ack_message" 42 "software_revision" 1 "Key_contact_state" ;
VAL_ 2565865249 LED_secondary_color 9 "Yellow/green" 8 "Amber/Orange" 7 "White/light_blue" 6 "Magenta" 5 "Cyan" 4 "Yellow" 3 "Blue" 2 "Green" 1 "Red" 0 "off" ;
VAL_ 2565865249 LED_color 9 "Yellow/Green" 8 "Amber/Orange" 7 "White/light_blue" 6 "Magenta" 5 "Cyan" 4 "Yellow" 3 "Blue" 2 "Green" 1 "Red" 0 "off" ;
VAL_ 2565865249 Key_Number 4 "Key4" 3 "Key3" 2 "Key2" 1 "Key1" ;
VAL_ 2565865249 Contact_state 1 "Pressed" 0 "Released" ;
VAL_ 2566866168 Fault9_DC2 3 "Not Tested" 2 "Error Indicator" 1 "Active" 0 "Not Active" ;
VAL_ 2566866168 Fault8_DC2 3 "Not Tested" 2 "Error Indicator" 1 "Active" 0 "Not Active" ;
VAL_ 2566866168 Fault7_DC2 3 "Not Tested" 2 "Error Indicator" 1 "Active" 0 "Not Active" ;
VAL_ 2566866168 Fault6_DC2 3 "Not Tested" 2 "Error Indicator" 1 "Active" 0 "Not Active" ;
VAL_ 2566866168 Fault5_DC2 3 "Not Tested" 2 "Error Indicator" 1 "Active" 0 "Not Active" ;
VAL_ 2566866168 Fault4_DC2 3 "Not Tested" 2 "Error indicator" 1 "Active" 0 "Not Active" ;
VAL_ 2566866168 Fault3_DC2 3 "Not Tested'" 2 "Error indicator" 1 "Actve" 0 "Not Active" ;
VAL_ 2566866168 Fault32_DC2 3 "Not Tested" 2 "Error Indicator" 1 "Active" 0 "Not Active" ;
VAL_ 2566866168 Fault31_DC2 3 "Not Tested" 2 "Error Indicator" 1 "Active" 0 "Not Active" ;
VAL_ 2566866168 Fault30_DC2 3 "Not Tested" 2 "Error Indicator" 1 "Active" 0 "Not Active" ;
VAL_ 2566866168 Fault2_DC2 3 "Not tested" 2 "Error indicator" 1 "Active" 0 "Not Active" ;
VAL_ 2566866168 Fault29_DC2 3 "Not Tested" 2 "Error Indicator" 1 "Active" 0 "Not Active" ;
VAL_ 2566866168 Fault28_DC2 3 "Not Tested" 2 "Error Indicator" 1 "Active" 0 "Not Active" ;
VAL_ 2566866168 Fault27_DC2 3 "Not Tested" 2 "Error Indicator" 1 "Active" 0 "Not Active" ;
VAL_ 2566866168 Fault26_DC2 3 "Not Tested" 2 "Error Indicator" 1 "Active" 0 "Not Active" ;
VAL_ 2566866168 Fault25_DC2 3 "Not Tested" 2 "Error Indicator" 1 "Active" 0 "Not Active" ;
VAL_ 2566866168 Fault24_DC2 3 "Not Tested" 2 "Error Indicator" 1 "Active" 0 "Not Active" ;
VAL_ 2566866168 Fault23_DC2 3 "Not Tested" 2 "Error Indicator" 1 "Active" 0 "Not Active" ;
VAL_ 2566866168 Fault22_DC2 3 "Not Tested" 2 "Error Indicator" 1 "Active" 0 "Not Active" ;
VAL_ 2566866168 Fault21_DC2 3 "Not Tested" 2 "Error Indicator" 1 "Active" 0 "Not Active" ;
VAL_ 2566866168 Fault20_DC2 3 "Not Tested" 2 "Error Indicator" 1 "Active" 0 "Not Active" ;
VAL_ 2566866168 Fault1_DC2 3 "Not tested" 2 "Error indicator" 1 "Active" 0 "Not active" ;
VAL_ 2566866168 Fault19_DC2 3 "Not Tested" 2 "Error Indicator" 1 "Active" 0 "Not Active" ;
VAL_ 2566866168 Fault18_DC2 3 "Not Tested" 2 "Error Indicator" 1 "Active" 0 "Not Active" ;
VAL_ 2566866168 Fault17_DC2 3 "Not Tested" 2 "Error Indicator" 1 "Active" 0 "Not Active" ;
VAL_ 2566866168 Fault16_DC2 3 "Not Tested" 2 "Error Indicator" 1 "Active" 0 "Not Active" ;
VAL_ 2566866168 Fault15_DC2 3 "Not Tested" 2 "Error Indicator" 1 "Active" 0 "Not Active" ;
VAL_ 2566866168 Fault14_DC2 3 "Not Tested" 2 "Error Indicator" 1 "Active" 0 "Not Active" ;
VAL_ 2566866168 Fault13_DC2 3 "Not Tested" 2 "Error Indicator" 1 "Active" 0 "Not Active" ;
VAL_ 2566866168 Fault12_DC2 3 "Not Tested" 2 "Error Indicator" 1 "Active" 0 "Not Active" ;
VAL_ 2566866168 Fault11_DC2 3 "Not Tested" 2 "Error Indicator" 1 "Active" 0 "Not Active" ;
VAL_ 2566866168 Fault10_DC2 3 "Not Tested" 2 "Error Indicator" 1 "Active" 0 "Not Active" ;
VAL_ 2566866166 Fault9_DC2 3 "Not Tested" 2 "Error Indicator" 1 "Active" 0 "Not Active" ;
VAL_ 2566866166 Fault8_DC2 3 "Not Tested" 2 "Error Indicator" 1 "Active" 0 "Not Active" ;
VAL_ 2566866166 Fault7_DC2 3 "Not Tested" 2 "Error Indicator" 1 "Active" 0 "Not Active" ;
VAL_ 2566866166 Fault6_DC2 3 "Not Tested" 2 "Error Indicator" 1 "Active" 0 "Not Active" ;
VAL_ 2566866166 Fault5_DC2 3 "Not Tested" 2 "Error Indicator" 1 "Active" 0 "Not Active" ;
VAL_ 2566866166 Fault4_DC2 3 "Not Tested" 2 "Error indicator" 1 "Active" 0 "Not Active" ;
VAL_ 2566866166 Fault3_DC2 3 "Not Tested'" 2 "Error indicator" 1 "Actve" 0 "Not Active" ;
VAL_ 2566866166 Fault32_DC2 3 "Not Tested" 2 "Error Indicator" 1 "Active" 0 "Not Active" ;
VAL_ 2566866166 Fault31_DC2 3 "Not Tested" 2 "Error Indicator" 1 "Active" 0 "Not Active" ;
VAL_ 2566866166 Fault30_DC2 3 "Not Tested" 2 "Error Indicator" 1 "Active" 0 "Not Active" ;
VAL_ 2566866166 Fault2_DC2 3 "Not tested" 2 "Error indicator" 1 "Active" 0 "Not Active" ;
VAL_ 2566866166 Fault29_DC2 3 "Not Tested" 2 "Error Indicator" 1 "Active" 0 "Not Active" ;
VAL_ 2566866166 Fault28_DC2 3 "Not Tested" 2 "Error Indicator" 1 "Active" 0 "Not Active" ;
VAL_ 2566866166 Fault27_DC2 3 "Not Tested" 2 "Error Indicator" 1 "Active" 0 "Not Active" ;
VAL_ 2566866166 Fault26_DC2 3 "Not Tested" 2 "Error Indicator" 1 "Active" 0 "Not Active" ;
VAL_ 2566866166 Fault25_DC2 3 "Not Tested" 2 "Error Indicator" 1 "Active" 0 "Not Active" ;
VAL_ 2566866166 Fault24_DC2 3 "Not Tested" 2 "Error Indicator" 1 "Active" 0 "Not Active" ;
VAL_ 2566866166 Fault23_DC2 3 "Not Tested" 2 "Error Indicator" 1 "Active" 0 "Not Active" ;
VAL_ 2566866166 Fault22_DC2 3 "Not Tested" 2 "Error Indicator" 1 "Active" 0 "Not Active" ;
VAL_ 2566866166 Fault21_DC2 3 "Not Tested" 2 "Error Indicator" 1 "Active" 0 "Not Active" ;
VAL_ 2566866166 Fault20_DC2 3 "Not Tested" 2 "Error Indicator" 1 "Active" 0 "Not Active" ;
VAL_ 2566866166 Fault1_DC2 3 "Not tested" 2 "Error indicator" 1 "Active" 0 "Not active" ;
VAL_ 2566866166 Fault19_DC2 3 "Not Tested" 2 "Error Indicator" 1 "Active" 0 "Not Active" ;
VAL_ 2566866166 Fault18_DC2 3 "Not Tested" 2 "Error Indicator" 1 "Active" 0 "Not Active" ;
VAL_ 2566866166 Fault17_DC2 3 "Not Tested" 2 "Error Indicator" 1 "Active" 0 "Not Active" ;
VAL_ 2566866166 Fault16_DC2 3 "Not Tested" 2 "Error Indicator" 1 "Active" 0 "Not Active" ;
VAL_ 2566866166 Fault15_DC2 3 "Not Tested" 2 "Error Indicator" 1 "Active" 0 "Not Active" ;
VAL_ 2566866166 Fault14_DC2 3 "Not Tested" 2 "Error Indicator" 1 "Active" 0 "Not Active" ;
VAL_ 2566866166 Fault13_DC2 3 "Not Tested" 2 "Error Indicator" 1 "Active" 0 "Not Active" ;
VAL_ 2566866166 Fault12_DC2 3 "Not Tested" 2 "Error Indicator" 1 "Active" 0 "Not Active" ;
VAL_ 2566866166 Fault11_DC2 3 "Not Tested" 2 "Error Indicator" 1 "Active" 0 "Not Active" ;
VAL_ 2566866166 Fault10_DC2 3 "Not Tested" 2 "Error Indicator" 1 "Active" 0 "Not Active" ;
VAL_ 2297299202 Current_transmission_mode 3 "Forward Low" 2 "Forward Automatic" 1 "Reverse" 0 "Neutral" ;
VAL_ 2297299202 Selected_Gear 3 "Shift in Progress" 2 "High" 1 "Low" 0 "Neutral" ;
VAL_ 2297299202 Upshift_in_progress 1 "High gear Shift is in progress" 0 "High Shift is not in progress" ;
VAL_ 2297299202 Downshift_In_Progress 1 "High gear Shift is in progress" 0 "High Shift is not in progress" ;
VAL_ 2297299202 Upshift_Failed 1 "shift to High gear failed" 0 "shift to High gear successful" ;
VAL_ 2297299202 Slow_Upshift 1 "Shift require more amnt of time" 0 "Shift in a normal amount of time" ;
VAL_ 2297299202 Slow_Downshift 1 "Shift require more amnt of time" 0 "Shift in a normal amount of time" ;
VAL_ 2297299202 Shift_Disabled 1 "Gear shift disabled" 0 "Gear shift not disabled" ;
VAL_ 2297299202 Max_Shift_Speed_Delta_Exceeded 1 "Gear shift disabled" 0 "Gear shift not disabled" ;
VAL_ 2297299202 Air_Pressure_Out_of_Range 1 "solenoids is out of range" 0 "solenoids is in normal range" ;
VAL_ 2297299202 Forced_Gear_Engagement_Torque 1 "TCU imposing min torque reqt" 0 "TCU not imposing min torque reqt" ;
VAL_ 2230190338 MCU_System_Type 15 "Undefined" 14 "Undefined" 13 "Undefined" 12 "Undefined" 11 "Undefined" 10 "Undefined" 9 "Undefined" 8 "Undefined" 7 "EM-PMI318B-T360-465V" 6 "Undefined" 5 "EM-PMI318B-T520E-465V" 4 "EM-PMI318B-T440E-255V" 3 "EM-PMI318-T400-255V" 2 "EM-PMI318-T360-425V" 1 "EM-PMI318-T350-255V" 0 "UnKnown" ;
VAL_ 2565865873 VMM_Halt_brake_status 3 "Not available" 2 "Error " 1 "Halt brake Active" 0 "Halt brake Passive" ;
VAL_ 2566905113 AC_status_group_1 128 "Fresh Air ON" 64 "Unloader 2 Energized " 32 "Unloader 1 Energized" 16 "Compressor ON" 8 "Cond. Fan Low Speed Bit" 4 "Cond. Fan High Speed" 2 "Evap. Fan Low Speed" 1 "Evap. Fan High Speed" ;
VAL_ 2566905113 AC_status_group_2 128 "Zone 2 FRSH AIR " 64 "Zone 2 Heat ON" 32 "Zone 2 Fan HI" 16 "Zone 2 Fan ON" 8 "Floor Heat ON " 4 "Boost Pump ON " 2 "Fault Lamp ON " 1 "Heat Valve ON " ;
VAL_ 2566906137 Floor_Heat_ON 3 "Skip" 1 "ON" 0 "OFF" ;
VAL_ 2566906137 Recirculation_Fresh_air 3 "not used" 2 "door controlled per ladder diag" 1 "door open all the time" 0 "door closed all the time" ;
VAL_ 2566906137 High_Blower_override_Heat 1 "Heat mode-speed overidden" 0 "Normal" ;
VAL_ 2566906137 Running_a_mode 3 "Skip" 1 "ON" 0 "OFF" ;
VAL_ 2566906137 Compressor_ON_OFF 3 "Skip" 1 "ON" 0 "OFF" ;
VAL_ 2566906137 HVAC_Operating_Modes 15 "Description for the value '0xF'" 14 "EvporatorCondenserFansHighSpeed" 13 "Condenser Fans - High Speed" 12 "Evaporator Blowers - High Speed" 6 "All Heat Valves Open. AC OFF." 5 "Cooling/Reheat/Vent" 4 "Auto/Reheat ambient cut-out" 2 "Cooling/Vent" 1 "Heating/Vent" 0 "Only Vent (fresh air)" ;
VAL_ 2566906137 AC_Fail 3 "Skip" 1 "ON" 0 "OFF" ;
VAL_ 2566906137 BMS_Request 2 "Compressor off." 1 "Compressor at 50%,Heaters on off" 0 "Run normal." ;
VAL_ 2566906137 Battery_Cooler_Status 2 "Ignore" 1 "ON" 0 "OFF" ;
VAL_ 2566906137 Idle_Up_Status 3 "Skip" 1 "ON" 0 "OFF" ;
VAL_ 2566906137 Boost_Pump_Status 2 "bus controls the boost pump" 1 "notify boost pump is oN" 0 "notify boost pump is off" ;
VAL_ 2566906137 Low_Blower_Speed_Signal 3 "Skip" 1 "Low" 0 "Standard" ;
VAL_ 2565806401 BMS_Request 2 "Compressor off." 1 "Compressor at 50%,Heaters on off" 0 "Run normal." ;
VAL_ 2565806401 AC_Load_Shedding 3 "ignore" 2 "Medium Blowers speed" 1 "Run unloaded with medium " 0 "Run normal. " ;
VAL_ 2565806401 Recirculation_Fresh_Air 3 "ignored" 2 "FreshAir" 1 "Recirculation" 0 "Controlled" ;
VAL_ 2565806401 Floor_Heat_Status 15 "ignored" 10 "Rear Unit High Blower Speed" 9 "Rear Unit Low Blower Speed" 8 "Rear Unit Natural Convection" 7 "Rear Unit Heat Valve Open" 6 "Rear Unit Heat Valve Closed" 5 "Front Unit High Blower Speed" 4 "Front Unit Low Blower Speed" 3 "Front Unit Natural Convection" 2 "Front Unit Heat Valve Open" 1 "Front Unit Heat Valve Closed" 0 "Inactive" ;
VAL_ 2565806401 HVAC_Operating_Mode 15 "no action" 14 "EvapratoCondenserFansHigh Speed" 13 "Condenser Fans - High Speed" 12 "Evaporator Blowers - High Speed" 6 "All Heat Valves Open. AC OFF " 5 "Cooling/Reheat/Vent/low amb" 4 "Auto/Reheat" 3 "Reheat" 2 "Cooling/Vent    " 1 "Heating / Vent" 0 "Only Vent " ;
VAL_ 2565806401 Controller_Reset 3 "ignored" 2 "Not defined    " 1 "Forces blower speed to low speed" 0 "Runs in standard mode    " ;
VAL_ 2565806401 HVAC_Switch 3 "Inactive" 1 "runs to default/ requested mode" 0 "Inactive" ;
VAL_ 2565806401 High_Blower_Speed_Heat 3 "Description for the value '0x3'" 1 "Force blower speed to high" 0 "Runs in standard mode" ;
VAL_ 2565806401 Boost_Pump_Signal 2 "no action" 1 "Boost Pump is oN" 0 "Boost Pump is off" ;
VAL_ 2565806401 Low_Blower_Speed_Signal 3 "igniore" 1 "Forceblowerspeedtolow" 0 "Runs in standard mode  " ;
VAL_ 2565874768 FRC_PWR_CHGNG 4095 "Signal Invalid" ;
VAL_ 2572156958 D_ElCompFaultTempMechanical 3 "Not Available" 2 "Critical Overheat" 1 "OverHeat" 0 "Ok" ;
VAL_ 2572156958 D_ElCompFaultTractionVoltage 3 "Not Available" 2 "OverVoltage" 1 "Undervoltage" 0 "Ok" ;
VAL_ 2572156958 D_ElCompFaultGeneralHw_NotUsed 3 "Not  Available" 2 "Error" 1 "RUN" 0 "Do not RUN" ;
VAL_ 2572156958 D_ElCompFaultOverloadOutput 3 "Not Available" 2 "Reserved" 1 "Error Active" 0 "OK" ;
VAL_ 2572156958 D_ElCompFaultTempElectrical 3 "Not Available" 2 "Critical Overheat" 1 "OverHeat" 0 "Ok" ;
VAL_ 2572156958 D_ElCompFaultOilLevel 3 "Not available" 2 "Reserved" 1 "LOW" 0 "OK" ;
VAL_ 2573205534 D_ElCompTorque 255 "SNA" 254 "Error" ;
VAL_ 2573205534 D_ElCompPower 255 "SNA" 254 "Error" ;
VAL_ 2573205534 D_ElCompHvilStatus 7 "Not available" 6 "Reserved" 5 "Reserved" 4 "Reserved" 3 "Reserved" 2 "HVIL_diff >1V" 1 "HVIL < 5V" 0 "HVIl >= 5V" ;
VAL_ 2573205534 D_ElCompStatus 7 "Not available" 3 "Error Permanent" 2 "Error Recoverable" 1 "Running" 0 "Standby" ;
VAL_ 2573205534 D_ElCompEnableInput_NotUsed 3 "Not  Available" 2 "Error" 1 "RUN" 0 "Do not RUN" ;
VAL_ 2573205534 D_ElCompTractionVoltage 255 "SNA" 254 "Error" ;
VAL_ 2565874512 AVLB_PWR_LT_DCHG_HVSTO_extended 65535 "signal_unfilled" 65534 "reserved_Error" 65533 "reserved_not_available" ;
VAL_ 2565874512 AVLB_PWR_LT_CHG_HVSTO_extended 65535 "signal_unfilled" 65534 "reserved_Error" 65533 "reserved_not_available" ;
VAL_ 2565874512 AVLB_PWR_SRT_DCHG_HVSTO_extended 65535 "signal_unfilled" 65534 "reserved_Error" 65533 "reserved_not_available" ;
VAL_ 2565874512 AVLB_PWR_SRT_CHG_HVSTO_extended 65535 "signal_unfilled" 65534 "reserved_Error" 65533 "reserved_not_available" ;
VAL_ 2565874256 AVL_TEMP_HVSTO_MAX 255 "Signal_Unfilled" 254 "Reserved" 253 "Reserved" ;
VAL_ 2565874256 AVL_TEMP_HVSTO_MIN 255 "Signal_Unfilled" 254 "Reserved" 253 "Reserved" ;
VAL_ 2565874256 AVL_TEMP_HVSTO 255 "Signal Invalid" ;
VAL_ 2565874000 I_DYN_MAX_DCHG_HVSTO_extended 65535 "Signal Invalid" ;
VAL_ 2565874000 U_MIN_DCHG_HVSTO 65535 "Signal Invalid" ;
VAL_ 2565874000 I_DYN_MAX_CHG_HVSTO_extended 65535 "Signal Invalid" ;
VAL_ 2565874000 U_MAX_CHG_HVSTO 65535 "Signal Invalid" ;
VAL_ 2565820561 Throttle_Interlock 3 "Not available" 2 "Error" 1 "Active" 0 "Not active" ;
VAL_ 2565820561 Charging_Port_Lid_Right 3 "Not available" 2 "Error" 1 "Active" 0 "Not active" ;
VAL_ 2565820561 Charging_Port_Lid_Left 3 "Not available" 2 "Error" 1 "Active" 0 "Not active" ;
VAL_ 2565820561 Engine_Bay_Door_Rear 3 "Not available" 2 "Error" 1 "Active" 0 "Not active" ;
VAL_ 2565820561 Engine_Bay_Door_Right 3 "Not available" 2 "Error" 1 "Active" 0 "Not active" ;
VAL_ 2565820561 Engine_Bay_Door_Left 3 "Not available" 2 "Error" 1 "Active" 0 "Not active" ;
VAL_ 2565820561 Interlock_Switch 3 "Not available" 2 "Error" 1 "Active" 0 "Not active" ;
VAL_ 2565820561 Regen_OFF 3 "Not available" 2 "Error" 1 "Active" 0 "Not active" ;
VAL_ 2565820561 Low_Drive_Switch 3 "Not available" 2 "Error" 1 "Active" 0 "Not active" ;
VAL_ 2565820561 HV_Disable 3 "Not available" 2 "Error" 1 "Active" 0 "Not active" ;
VAL_ 2565820561 Emergency_StopSwitch 3 "Not available" 2 "Error" 1 "Active" 0 "Not active" ;
VAL_ 2565820561 Start_Function 3 "Not available" 2 "Error" 1 "Active" 0 "Not active" ;
VAL_ 2565820561 Ignition 3 "Not available" 2 "Error" 1 "Active" 0 "Not active" ;
VAL_ 2566865656 LimitationMode_DC2 15 "Error indicator" 14 "Not Available" 11 "External output voltage limit" 10 "Internal output voltage limit" 9 "External current limitation" 8 "High side current limitation" 7 "High side power limitation" 6 "coolant temp limitation" 5 "Power stage temp limitation" 4 "High input voltage limitation" 3 "low input voltage limitation" 2 "Event limitation" 1 "Maximum current limitatio" 0 "No Limitation" ;
VAL_ 2566865656 ActualControlMode_DC2 15 "Error Indicator" 14 "Not availble" 13 "Error state" 12 "Shutting down" 2 "Current control" 1 "Voltage control" 0 "Standby" ;
VAL_ 2349072126 Fault_bits 3 "Not tested" 2 "Error indicator" 1 "Active" 0 "Not active" ;
VAL_ 2566857346 ReqEnergyToPreconditionVehicle 255 "SNA" ;
VAL_ 2566857346 RequiredEnergyToChargeBattery 255 "SNA" ;
VAL_ 2566857346 ReqDurationToPreconditionVehicle 255 "SNA" ;
VAL_ 2566857346 RequirDurationToPrecnditinBatt 255 "SNA" ;
SIG_VALTYPE_ 2349465342 Dummy_Float_2 : 1;
SIG_VALTYPE_ 2349465342 Dummy_Float1 : 1;

SG_MUL_VAL_ 2565808384 LED_brightness_level RX_command_list 2-2, 124-124;
SG_MUL_VAL_ 2565808384 Backlight_brightness_level RX_command_list 3-3, 123-123;
